VERSION ""

NS_ :

BS_:

BU_: CVC_B BCM_FL BCM_FR DUMMY_ECU DKCU BCM_R

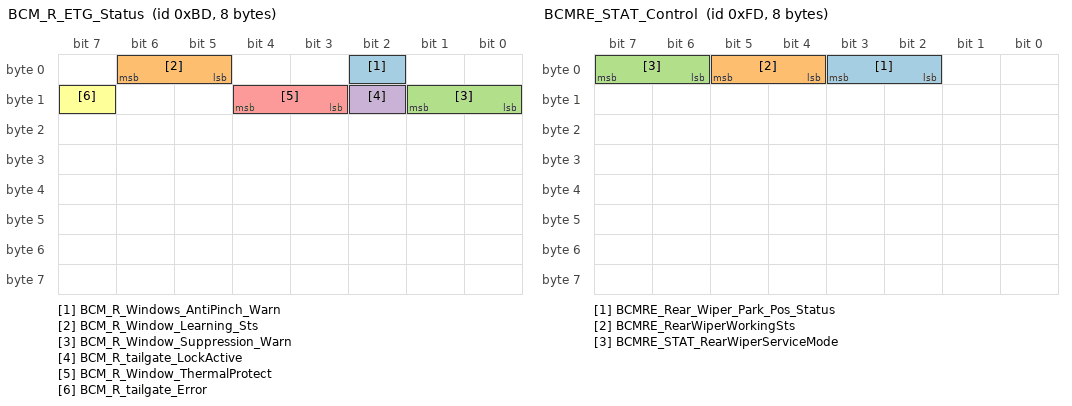
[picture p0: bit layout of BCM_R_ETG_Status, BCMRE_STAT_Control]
BO_ 189 BCM_R_ETG_Status: 8 BCM_R
 SG_ BCM_R_Windows_AntiPinch_Warn : 2|1@0+ (1,0) [0|1] ""  CVC_B
 SG_ BCM_R_Window_Learning_Sts : 6|2@0+ (1,0) [0|2] ""  CVC_B
 SG_ BCM_R_Window_Suppression_Warn : 9|2@0+ (1,0) [0|2] ""  CVC_B
 SG_ BCM_R_tailgate_LockActive : 10|1@0+ (1,0) [0|1] ""  CVC_B
 SG_ BCM_R_Window_ThermalProtect : 12|2@0+ (1,0) [0|2] ""  CVC_B
 SG_ BCM_R_tailgate_Error : 15|1@0+ (1,0) [0|1] ""  CVC_B

BO_ 206 BCMRE_DuctTemperature: 20 BCM_R
 SG_ BCMRE_DuctTempRearRight : 7|11@0+ (0.1,-30) [-30|100] "Degree C"  CVC_B
 SG_ BCMRE_DuctTempRearLeft : 12|11@0+ (0.1,-30) [-30|100] "Degree C"  CVC_B
 SG_ BCMRE_RearEvapTempSensor : 31|8@0+ (1,-40) [-40|85] "Degree C"  CVC_B
 SG_ BCMRE_DuctTempSensor3_Reserved : 39|8@0+ (1,-40) [-40|85] "Degree C"  CVC_B
 SG_ BCMRE_DuctTempSensor4_Reserved : 47|8@0+ (1,-40) [-40|85] "Degree C"  CVC_B
 SG_ BCMRE_DuctTempRearRightSts : 49|2@0+ (1,0) [0|3] ""  CVC_B
 SG_ BCMRE_DuctTempRearLeftSts : 51|2@0+ (1,0) [0|3] ""  CVC_B
 SG_ BCMRE_DuctTempSensor3_Sts : 53|2@0+ (1,0) [0|3] ""  CVC_B
 SG_ BCMRE_DuctTempSensor4_Sts : 55|2@0+ (1,0) [0|3] ""  CVC_B
 SG_ BCMRE_RearEvapTempSensor_Sts : 57|2@0+ (1,0) [0|3] ""  CVC_B

BO_ 253 BCMRE_STAT_Control: 8 BCM_R
 SG_ BCMRE_Rear_Wiper_Park_Pos_Status : 3|2@0+ (1,0) [0|3] ""  CVC_B
 SG_ BCMRE_RearWiperWorkingSts : 5|2@0+ (1,0) [0|2] ""  CVC_B
 SG_ BCMRE_STAT_RearWiperServiceMode : 7|2@0+ (1,0) [0|3] ""  CVC_B

BO_ 275 BCM_RE_Stat_SwtLightBrightness: 8 BCM_R
 SG_ BCM_Stat_SwitchLightBrightness : 7|8@0+ (0.4,0) [0|100] "%"  CVC_B
 SG_ BCM_Rear_Wash_Status : 8|1@0+ (1,0) [0|1] ""  CVC_B

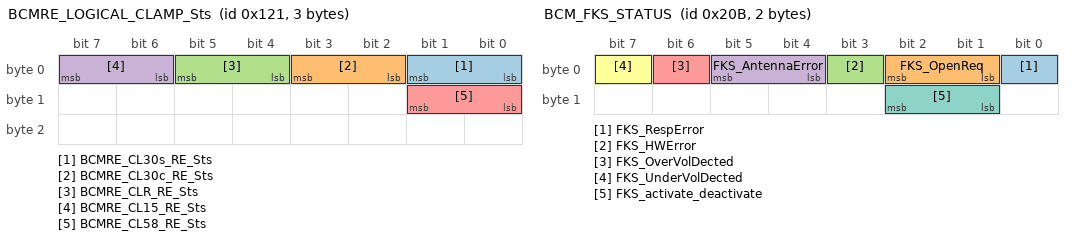
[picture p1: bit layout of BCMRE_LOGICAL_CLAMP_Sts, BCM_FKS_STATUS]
BO_ 289 BCMRE_LOGICAL_CLAMP_Sts: 3 BCM_R
 SG_ BCMRE_CL30s_RE_Sts : 1|2@0+ (1,0) [0|3] ""  CVC_B
 SG_ BCMRE_CL30c_RE_Sts : 3|2@0+ (1,0) [0|3] ""  CVC_B
 SG_ BCMRE_CLR_RE_Sts : 5|2@0+ (1,0) [0|3] ""  CVC_B
 SG_ BCMRE_CL15_RE_Sts : 7|2@0+ (1,0) [0|3] ""  CVC_B
 SG_ BCMRE_CL58_RE_Sts : 9|2@0+ (1,0) [0|3] ""  CVC_B

BO_ 325 BCMRE_ThermalComponents_Status: 32 BCM_R
 SG_ BCMRE_CoolantLevel3 : 1|2@0+ (1,0) [0|3] ""  CVC_B
 SG_ BCMRE_CoolantLevel3Error : 3|1@0+ (1,0) [0|1] ""  CVC_B
 SG_ BCMRE_PT_Sensor1_Pressure : 15|8@0+ (1,0) [0|37.27] "Bar"  CVC_B
 SG_ BCMRE_PT_Sensor1_Temp : 23|8@0+ (1,-40) [-40|150] "Degree C"  CVC_B
 SG_ BCMRE_PT_Sensor2_Pressure : 31|8@0+ (1,0) [0|37.27] "Bar"  CVC_B
 SG_ BCMRE_PT_Sensor2_Temp : 39|8@0+ (1,-40) [-40|150] "Degree C"  CVC_B
 SG_ BCMRE_Refrigerent_Temp_Sensor : 47|8@0+ (1,-40) [-40|130] "Degree C"  CVC_B
 SG_ BCMRE_SOV_Status : 49|2@0+ (1,0) [0|3] ""  CVC_B
 SG_ BCMRE_SOV2_Fault : 7|2@0+ (1,0) [0|3] ""  CVC_B
 SG_ BCMRE_EvapSOV2_Status : 5|2@0+ (1,0) [0|3] ""  CVC_B
 SG_ BCMRE_RearBlwMotor : 63|3@0+ (1,0) [0|7] ""  CVC_B
 SG_ BCMRE_RearBlwDiagFlag1 : 60|4@0+ (1,0) [0|15] ""  CVC_B
 SG_ BCMRE_RearBLFM_ErrorResp : 56|1@0+ (1,0) [0|1] ""  CVC_B
 SG_ BCMRE_RearBlwDiagFlag2 : 71|8@0+ (1,0) [0|255] ""  CVC_B
 SG_ BCMRE_RearBlwIBATT : 79|8@0+ (0.15,0) [0|38] "A"  CVC_B
 SG_ BCMRE_RearBlwRotationSpd : 87|8@0+ (20,0) [0|5100] "RPM"  CVC_B
 SG_ BCMRE_RearBlwTemperature : 95|8@0+ (1,-40) [0|255] "degC"  CVC_B
 SG_ BCMRE_RearBlwUBATT : 103|8@0+ (0.1,0) [0|255] "V"  CVC_B
 SG_ BCMRE_RearBlwSupplier : 111|8@0+ (1,0) [0|255] ""  CVC_B
 SG_ BCMRE_RearBlwUMotor : 119|8@0+ (0.1,0) [0|255] "V"  CVC_B
 SG_ BCMRE_RearBlwTorque : 167|10@0+ (0.001,0) [0|1.023] "Nm"  CVC_B
 SG_ BCMRE_RearAPTC_BusLineVolt : 127|8@0+ (4,0) [0|1020] "V"  CVC_B
 SG_ BCMRE_RearAPTC_BusLineCurrent : 135|8@0+ (0.1,0) [0|25.5] "A"  CVC_B
 SG_ BCMRE_RearAPTC_Temperature : 143|8@0+ (1,-40) [0|215] "Deg C"  CVC_B
 SG_ BCMRE_RearAPTC_HeatPwr : 151|8@0+ (1,0) [0|100] "%"  CVC_B
 SG_ BCMRE_RearAPTC_Status : 55|1@0+ (1,0) [0|1] ""  CVC_B
 SG_ BCMRE_RearAPTC_FaultState : 54|1@0+ (1,0) [0|1] ""  CVC_B
 SG_ BCMRE_RearAPTC_LinComError : 53|1@0+ (1,0) [0|1] ""  CVC_B
 SG_ BCMRE_RearAPTC_OverCurrentFault : 52|1@0+ (1,0) [0|1] ""  CVC_B
 SG_ BCMRE_RearAPTC_LvUnderVoltFault : 51|1@0+ (1,0) [0|1] ""  CVC_B
 SG_ BCMRE_RearAPTC_LvOverVoltFault : 50|1@0+ (1,0) [0|1] ""  CVC_B
 SG_ BCMRE_RearAPTC_IGBTTempSensorFau : 185|1@0+ (1,0) [0|1] ""  CVC_B
 SG_ BCMRE_RearAPTC_IGBTOverTempFault : 184|1@0+ (1,0) [0|1] ""  CVC_B
 SG_ BCMRE_RearAPTC_TempSensorFault : 192|1@0+ (1,0) [0|1] ""  CVC_B
 SG_ BCMRE_RearAPTC_OverTempFault : 193|1@0+ (1,0) [0|1] ""  CVC_B
 SG_ BCMRE_RearAPTC_HvUnderVoltFault : 194|1@0+ (1,0) [0|1] ""  CVC_B
 SG_ BCMRE_RearAPTC_HvOverVoltFault : 195|1@0+ (1,0) [0|1] ""  CVC_B
 SG_ BCMRE_RearAPTC_ShortCircuitFault : 196|1@0+ (1,0) [0|1] ""  CVC_B
 SG_ BCMRE_RearAPTC_OpentCircuitFault : 197|1@0+ (1,0) [0|1] ""  CVC_B
 SG_ BCMRE_RearAPTC_ResponseError : 198|1@0+ (1,0) [0|1] ""  CVC_B
 SG_ BCMRE_RearAPTC_IGBTTemperature : 159|8@0+ (1,-40) [0|215] "Deg C"  CVC_B
 SG_ BCMRE_RearEXV_RsErr : 199|1@0+ (1,0) [0|1] ""  CVC_B
 SG_ BCMRE_RearEXV_CurInit_Stat : 173|2@0+ (1,0) [0|3] ""  CVC_B
 SG_ BCMRE_RearEXV_Run_Stat : 2|1@0+ (1,0) [0|1] ""  CVC_B
 SG_ BCMRE_RearEXV_Fault_Stat : 171|4@0+ (1,0) [0|15] ""  CVC_B
 SG_ BCMRE_RearEXV_Volt_Stat : 189|2@0+ (1,0) [0|3] ""  CVC_B
 SG_ BCMRE_RearEXV_OvrTemp_Warn : 187|2@0+ (1,0) [0|3] ""  CVC_B
 SG_ BCMRE_RearEXV_Pos : 183|10@0+ (1,0) [0|576] ""  CVC_B

BO_ 522 ETG_STATUS: 8 BCM_R
 SG_ ETG_Lift_Gate_Status : 43|4@0+ (1,0) [0|15] ""  CVC_B
 SG_ ETG_Power_Latch_Status : 5|3@0+ (1,0) [0|7] ""  CVC_B
 SG_ ETG_Latch_Segment : 7|2@0+ (1,0) [0|3] ""  CVC_B
 SG_ ETG_Opening_Percentage : 15|8@0+ (1,0) [0|100] "%"  CVC_B
 SG_ ETG_DSW_Status : 16|1@0+ (1,0) [0|1] ""  CVC_B
 SG_ ETG_GSW_Status : 17|1@0+ (1,0) [0|1] ""  CVC_B
 SG_ ETG_LTS_Status : 18|1@0+ (1,0) [0|1] ""  CVC_B
 SG_ ETG_RTS_Status : 19|1@0+ (1,0) [0|1] ""  CVC_B
 SG_ ETG_HAL_Status : 20|1@0+ (1,0) [0|1] ""  CVC_B
 SG_ ETG_FUL_Status : 21|1@0+ (1,0) [0|1] ""  CVC_B
 SG_ ETG_AJR_Status : 22|1@0+ (1,0) [0|1] ""  CVC_B
 SG_ ETG_NTL_Status : 23|1@0+ (1,0) [0|1] ""  CVC_B
 SG_ ETG_ERR_Voltage : 25|2@0+ (1,0) [0|3] ""  CVC_B
 SG_ ETG_ERR_Left_Motor : 27|2@0+ (1,0) [0|3] ""  CVC_B
 SG_ ETG_ERR_Right_Motor : 29|2@0+ (1,0) [0|3] ""  CVC_B
 SG_ ETG_ERR_Latch : 31|2@0+ (1,0) [0|3] ""  CVC_B
 SG_ ETG_ERR_Hall : 33|2@0+ (1,0) [0|3] ""  CVC_B
 SG_ ETG_Lift_Motor_Stall : 34|1@0+ (1,0) [0|1] ""  CVC_B
 SG_ ETG_Lift_Motor_AntiPinch : 35|1@0+ (1,0) [0|1] ""  CVC_B
 SG_ ETG_Lift_Motor_Thermal : 36|1@0+ (1,0) [0|1] ""  CVC_B
 SG_ ETG_Power_Latch_Thermal : 37|1@0+ (1,0) [0|1] ""  CVC_B
 SG_ ETG_Abuse_Protection : 38|1@0+ (1,0) [0|1] ""  CVC_B

BO_ 523 BCM_FKS_STATUS: 2 BCM_R
 SG_ FKS_RespError : 0|1@0+ (1,0) [0|1] ""  CVC_B
 SG_ FKS_OpenReq : 2|2@0+ (1,0) [0|3] ""  CVC_B
 SG_ FKS_HWError : 3|1@0+ (1,0) [0|1] ""  CVC_B
 SG_ FKS_AntennaError : 5|2@0+ (1,0) [0|3] ""  CVC_B
 SG_ FKS_OverVolDected : 6|1@0+ (1,0) [0|1] ""  CVC_B
 SG_ FKS_UnderVolDected : 7|1@0+ (1,0) [0|1] ""  CVC_B
 SG_ FKS_activate_deactivate : 10|2@0+ (1,0) [0|3] ""  CVC_B

BO_ 535 BCMRE_ExteriorLight_STS: 12 BCM_R
 SG_ BCM_PositionLight_RL_STS : 2|3@0+ (1,0) [0|4] ""  CVC_B
 SG_ BCM_PositionLight_RR_STS : 5|3@0+ (1,0) [0|4] ""  CVC_B
 SG_ BCM_TurnIndicator_RL_STS : 10|3@0+ (1,0) [0|4] ""  CVC_B
 SG_ BCM_TurnIndicator_RR_STS : 13|3@0+ (1,0) [0|4] ""  CVC_B
 SG_ BCM_ReverseLamp_RL_STS : 18|3@0+ (1,0) [0|4] ""  CVC_B
 SG_ BCM_ReverseLamp_RR_STS : 21|3@0+ (1,0) [0|4] ""  CVC_B
 SG_ BCM_BrakeLight_RL_STS : 26|3@0+ (1,0) [0|4] ""  CVC_B
 SG_ BCM_BrakeLight_RR_STS : 29|3@0+ (1,0) [0|4] ""  CVC_B
 SG_ BCM_RearFogLamp_RR_STS : 34|3@0+ (1,0) [0|4] ""  CVC_B
 SG_ BCM_BrakeLight_Center_STS : 37|3@0+ (1,0) [0|4] ""  CVC_B
 SG_ BCM_LicensePlateLamp_RE_STS : 42|3@0+ (1,0) [0|4] ""  CVC_B
 SG_ BCM_RearFogLamp_RL_STS : 45|3@0+ (1,0) [0|4] ""  CVC_B
 SG_ BCM_SignatureRear_STS : 55|3@0+ (1,0) [0|4] ""  CVC_B
 SG_ BCMRE_WelcomeFarewellLight_STS : 71|3@0+ (1,0) [0|7] ""  CVC_B
 SG_ BCM_PositionLight_RM_STS : 68|3@0+ (1,0) [0|4] ""  CVC_B
 SG_ BCM_ParkingLight_RL_STS : 65|2@0+ (1,0) [0|3] ""  CVC_B
 SG_ BCM_ParkingLight_RM_STS : 79|2@0+ (1,0) [0|3] ""  CVC_B
 SG_ BCM_ParkingLight_RR_STS : 77|2@0+ (1,0) [0|3] ""  CVC_B

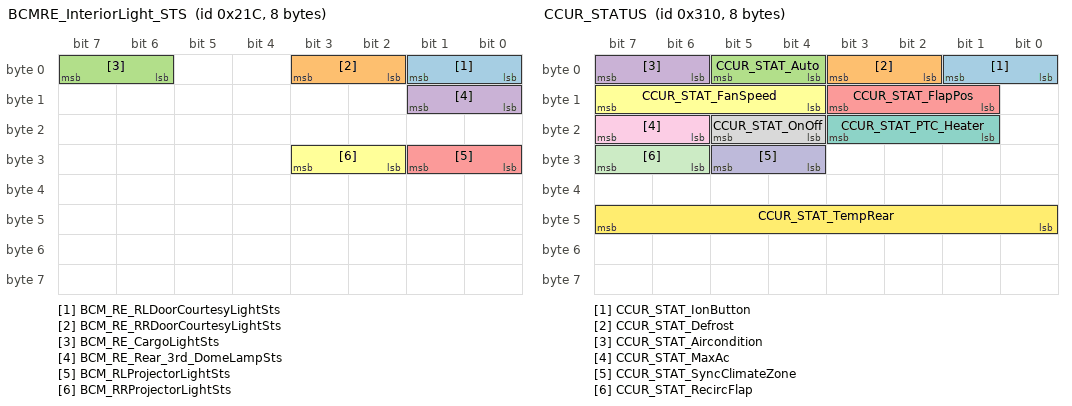
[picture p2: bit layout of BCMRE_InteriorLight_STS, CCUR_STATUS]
BO_ 540 BCMRE_InteriorLight_STS: 8 BCM_R
 SG_ BCM_RE_RLDoorCourtesyLightSts : 1|2@0+ (1,0) [0|3] ""  CVC_B
 SG_ BCM_RE_RRDoorCourtesyLightSts : 3|2@0+ (1,0) [0|3] ""  CVC_B
 SG_ BCM_RE_CargoLightSts : 7|2@0+ (1,0) [0|3] ""  CVC_B
 SG_ BCM_RE_Rear_3rd_DomeLampSts : 9|2@0+ (1,0) [0|3] ""  CVC_B
 SG_ BCM_RLProjectorLightSts : 25|2@0+ (1,0) [0|3] ""  CVC_B
 SG_ BCM_RRProjectorLightSts : 27|2@0+ (1,0) [0|3] ""  CVC_B

BO_ 784 CCUR_STATUS: 8 BCM_R
 SG_ CCUR_STAT_IonButton : 1|2@0+ (1,0) [0|3] ""  CVC_B
 SG_ CCUR_STAT_Defrost : 3|2@0+ (1,0) [0|3] ""  CVC_B
 SG_ CCUR_STAT_Auto : 5|2@0+ (1,0) [0|3] ""  CVC_B
 SG_ CCUR_STAT_Aircondition : 7|2@0+ (1,0) [0|3] ""  CVC_B
 SG_ CCUR_STAT_FlapPos : 11|3@0+ (1,0) [0|7] ""  CVC_B
 SG_ CCUR_STAT_FanSpeed : 15|4@0+ (1,0) [0|15] ""  CVC_B
 SG_ CCUR_STAT_PTC_Heater : 19|3@0+ (1,0) [0|7] ""  CVC_B
 SG_ CCUR_STAT_OnOff : 21|2@0+ (1,0) [0|3] ""  CVC_B
 SG_ CCUR_STAT_MaxAc : 23|2@0+ (1,0) [0|3] ""  CVC_B
 SG_ CCUR_STAT_SyncClimateZone : 29|2@0+ (1,0) [0|3] ""  CVC_B
 SG_ CCUR_STAT_RecircFlap : 31|2@0+ (1,0) [0|3] ""  CVC_B
 SG_ CCUR_STAT_TempRear : 47|8@0+ (0.5,0) [16|32] "Degree C"  CVC_B

BO_ 1040 BCM_RE_RearWindow_sts: 8 BCM_R
 SG_ BCMRE_RearHeatedWindow : 1|2@0+ (1,0) [0|3] ""  CVC_B

BO_ 1056 BCM_Comfort_Confirm_RE_sts: 8 BCM_R
 SG_ BCM_STAT_AutoRearWiper : 1|2@0+ (1,0) [0|3] ""  CVC_B
 SG_ BCM_STAT_MirrorFoldSetting : 3|2@0+ (1,0) [0|3] ""  CVC_B
 SG_ BCM_STAT_IMMO_KeyfobID2 : 7|3@0+ (1,0) [0|7] ""  CVC_B
 SG_ BCM_STAT_MirrorAutoUnfold : 9|2@0+ (1,0) [0|3] ""  CVC_B
 SG_ BCM_STAT_MirrorReverseLink : 11|2@0+ (1,0) [0|3] ""  CVC_B
 SG_ BCM_STAT_MirrorDefaultSTATting : 13|2@0+ (1,0) [0|3] ""  CVC_B
 SG_ BCM_STAT_WelcomeTriggerCondition : 15|2@0+ (1,0) [0|3] ""  CVC_B
 SG_ BCM_STAT_FrontDomeLamp : 17|2@0+ (1,0) [0|3] ""  CVC_B
 SG_ BCM_STAT_FollowMeHome : 20|3@0+ (1,0) [0|7] ""  CVC_B
 SG_ BCM_STAT_ExteriorLight : 23|3@0+ (1,0) [0|7] ""  CVC_B
 SG_ BCM_STAT_RemoteLockFeedback : 26|3@0+ (1,0) [0|7] ""  CVC_B
 SG_ BCM_STAT_RemoteDoorUnlock : 28|2@0+ (1,0) [0|3] ""  CVC_B
 SG_ BCM_STAT_AutoDoorUnlock : 30|2@0+ (1,0) [0|3] ""  CVC_B
 SG_ BCM_STAT_AmbientLightBrighness : 39|7@0+ (1,0) [0|100] "%"  CVC_B
 SG_ BCM_STAT_WiperServiceMode : 42|2@0+ (1,0) [0|3] ""  CVC_B
 SG_ BCM_STAT_IMMO_KeyfobID : 45|2@0+ (1,0) [0|3] ""  CVC_B
 SG_ BCM_STAT_RearHeatedWindowMirror : 47|2@0+ (1,0) [0|3] ""  CVC_B
 SG_ BCM_STAT_AntiTheftMode : 50|3@0+ (1,0) [0|7] ""  CVC_B
 SG_ BCM_STAT_ClimateKeepOnSts : 53|2@0+ (1,0) [0|3] ""  CVC_B
 SG_ BCM_STAT_FKSfeedback : 55|2@0+ (1,0) [0|3] ""  CVC_B
 SG_ SECCAN_CmftCnfrm : 63|8@0+ (1,0) [0|255] ""  CVC_B

BO_ 1075 BCMRE_Mirror_Sts: 8 BCM_R
 SG_ BCMRE_STAT_RearDefrost : 7|2@0+ (1,0) [0|3] ""  CVC_B

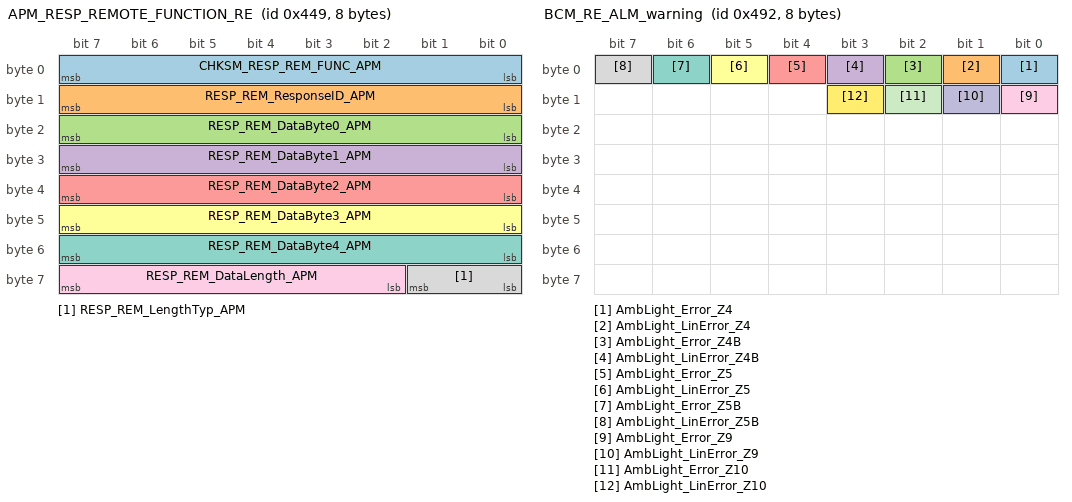
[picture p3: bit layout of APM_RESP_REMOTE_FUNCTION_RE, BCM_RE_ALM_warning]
BO_ 1097 APM_RESP_REMOTE_FUNCTION_RE: 8 BCM_R
 SG_ CHKSM_RESP_REM_FUNC_APM : 7|8@0+ (1,0) [0|255] ""  CVC_B
 SG_ RESP_REM_ResponseID_APM : 15|8@0+ (1,0) [0|254] ""  CVC_B
 SG_ RESP_REM_DataByte0_APM : 23|8@0+ (1,0) [0|254] ""  CVC_B
 SG_ RESP_REM_DataByte1_APM : 31|8@0+ (1,0) [0|254] ""  CVC_B
 SG_ RESP_REM_DataByte2_APM : 39|8@0+ (1,0) [0|254] ""  CVC_B
 SG_ RESP_REM_DataByte3_APM : 47|8@0+ (1,0) [0|254] ""  CVC_B
 SG_ RESP_REM_DataByte4_APM : 55|8@0+ (1,0) [0|254] ""  CVC_B
 SG_ RESP_REM_LengthTyp_APM : 57|2@0+ (1,0) [0|3] ""  CVC_B
 SG_ RESP_REM_DataLength_APM : 63|6@0+ (1,0) [0|63] ""  CVC_B

BO_ 1170 BCM_RE_ALM_warning: 8 BCM_R
 SG_ AmbLight_Error_Z4 : 0|1@0+ (1,0) [0|1] ""  CVC_B
 SG_ AmbLight_LinError_Z4 : 1|1@0+ (1,0) [0|1] ""  CVC_B
 SG_ AmbLight_Error_Z4B : 2|1@0+ (1,0) [0|1] ""  CVC_B
 SG_ AmbLight_LinError_Z4B : 3|1@0+ (1,0) [0|1] ""  CVC_B
 SG_ AmbLight_Error_Z5 : 4|1@0+ (1,0) [0|1] ""  CVC_B
 SG_ AmbLight_LinError_Z5 : 5|1@0+ (1,0) [0|1] ""  CVC_B
 SG_ AmbLight_Error_Z5B : 6|1@0+ (1,0) [0|1] ""  CVC_B
 SG_ AmbLight_LinError_Z5B : 7|1@0+ (1,0) [0|1] ""  CVC_B
 SG_ AmbLight_Error_Z9 : 8|1@0+ (1,0) [0|1] ""  CVC_B
 SG_ AmbLight_LinError_Z9 : 9|1@0+ (1,0) [0|1] ""  CVC_B
 SG_ AmbLight_Error_Z10 : 10|1@0+ (1,0) [0|1] ""  CVC_B
 SG_ AmbLight_LinError_Z10 : 11|1@0+ (1,0) [0|1] ""  CVC_B

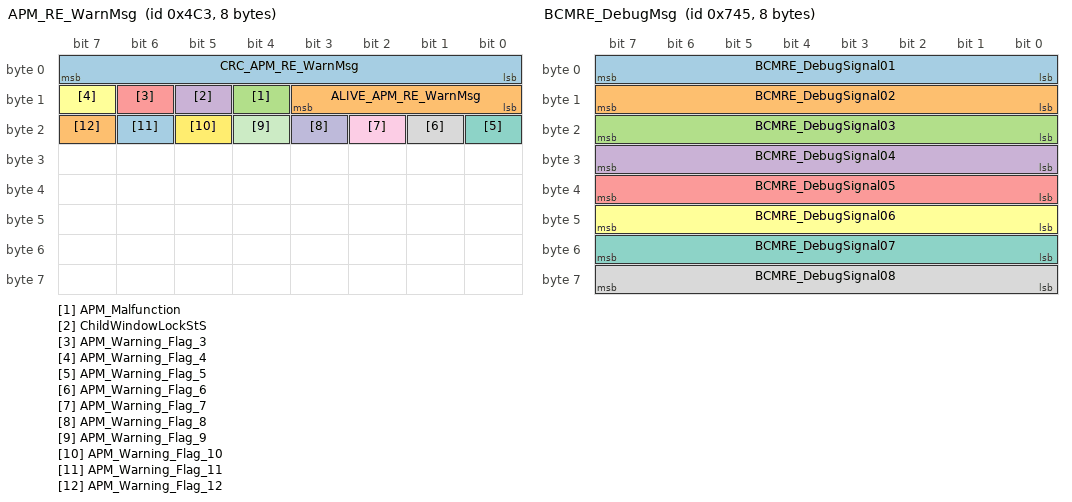
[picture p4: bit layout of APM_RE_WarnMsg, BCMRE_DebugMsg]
BO_ 1219 APM_RE_WarnMsg: 8 BCM_R
 SG_ CRC_APM_RE_WarnMsg : 7|8@0+ (1,0) [0|255] ""  CVC_B
 SG_ ALIVE_APM_RE_WarnMsg : 11|4@0+ (1,0) [0|15] ""  CVC_B
 SG_ APM_Malfunction : 12|1@0+ (1,0) [0|1] ""  CVC_B
 SG_ ChildWindowLockStS : 13|1@0+ (1,0) [0|1] ""  CVC_B
 SG_ APM_Warning_Flag_3 : 14|1@0+ (1,0) [0|1] ""  CVC_B
 SG_ APM_Warning_Flag_4 : 15|1@0+ (1,0) [0|1] ""  CVC_B
 SG_ APM_Warning_Flag_5 : 16|1@0+ (1,0) [0|1] ""  CVC_B
 SG_ APM_Warning_Flag_6 : 17|1@0+ (1,0) [0|1] ""  CVC_B
 SG_ APM_Warning_Flag_7 : 18|1@0+ (1,0) [0|1] ""  CVC_B
 SG_ APM_Warning_Flag_8 : 19|1@0+ (1,0) [0|1] ""  CVC_B
 SG_ APM_Warning_Flag_9 : 20|1@0+ (1,0) [0|1] ""  CVC_B
 SG_ APM_Warning_Flag_10 : 21|1@0+ (1,0) [0|1] ""  CVC_B
 SG_ APM_Warning_Flag_11 : 22|1@0+ (1,0) [0|1] ""  CVC_B
 SG_ APM_Warning_Flag_12 : 23|1@0+ (1,0) [0|1] ""  CVC_B

BO_ 1242 BCM_R_WarnMsg_R: 8 BCM_R
 SG_ CRC_BCM_R_WarnMsg_R : 7|8@0+ (1,0) [0|255] ""  CVC_B
 SG_ ALIVE_BCM_R_WarnMsg_R : 11|4@0+ (1,0) [0|15] ""  CVC_B
 SG_ BCM_R_NoValidKey_1 : 12|1@0+ (1,0) [0|1] ""  CVC_B
 SG_ BCM_R_SSB_defect : 13|1@0+ (1,0) [0|1] ""  CVC_B
 SG_ BCM_R_WrongGearPosToStart : 14|1@0+ (1,0) [0|1] ""  CVC_B
 SG_ BCM_R_NoValidKey_2 : 15|1@0+ (1,0) [0|1] ""  CVC_B
 SG_ BCM_R_PressBrakeToStart : 16|1@0+ (1,0) [0|1] ""  CVC_B
 SG_ BCM_R_TurnOffPosLightRemindr : 17|1@0+ (1,0) [0|1] ""  CVC_B
 SG_ BCM_R_KeyFob_LowBattery : 18|1@0+ (1,0) [0|1] ""  CVC_B
 SG_ BCM_R_StopLightDefect : 19|1@0+ (1,0) [0|1] ""  CVC_B
 SG_ BCM_R_LowBeamDefect : 20|1@0+ (1,0) [0|1] ""  CVC_B
 SG_ BCM_R_HighBeamDefect : 21|1@0+ (1,0) [0|1] ""  CVC_B
 SG_ BCM_R_PositionLightDefect : 22|1@0+ (1,0) [0|1] ""  CVC_B
 SG_ BCM_R_CHMLS_Defect : 23|1@0+ (1,0) [0|1] ""  CVC_B
 SG_ BCM_R_LicencePlateLight_Defect : 24|1@0+ (1,0) [0|1] ""  CVC_B
 SG_ BCM_R_FrontFog_Defect : 25|1@0+ (1,0) [0|1] ""  CVC_B
 SG_ BCM_R_RearLeftDoorLockDefect : 26|1@0+ (1,0) [0|1] ""  CVC_B
 SG_ BCM_R_ReverseLightDefect : 27|1@0+ (1,0) [0|1] ""  CVC_B
 SG_ BCM_R_RLS_Malfunction : 28|1@0+ (1,0) [0|1] ""  CVC_B
 SG_ BCM_R_12VBattery_LowLevel : 29|1@0+ (1,0) [0|1] ""  CVC_B
 SG_ BCM_R_ForgetKeyFOBInCar : 30|1@0+ (1,0) [0|1] ""  CVC_B
 SG_ BCM_R_12VBattery_Discharging : 31|1@0+ (1,0) [0|1] ""  CVC_B
 SG_ BCM_R_TurnIndicatorDefect : 32|1@0+ (1,0) [0|1] ""  CVC_B
 SG_ BCM_R_dTPMS_Malfunc : 33|1@0+ (1,0) [0|1] ""  CVC_B
 SG_ BCM_R_dTPMS_Malfunc_LostSensor : 34|1@0+ (1,0) [0|1] ""  CVC_B
 SG_ BCM_R_dTPMS_LowPressure : 35|1@0+ (1,0) [0|1] ""  CVC_B
 SG_ BCM_R_dTPMS_RapidLeak : 36|1@0+ (1,0) [0|1] ""  CVC_B
 SG_ BCM_R_dTPMS_HighTemperature : 37|1@0+ (1,0) [0|1] ""  CVC_B
 SG_ BCM_R_dTPMS_HighPressure : 38|1@0+ (1,0) [0|1] ""  CVC_B
 SG_ BCM_R_dTPMS_LowBattery : 39|1@0+ (1,0) [0|1] ""  CVC_B
 SG_ BCM_R_Keyfob_Leftcar : 40|1@0+ (1,0) [0|1] ""  CVC_B
 SG_ BCM_R_IDB_Brakelight_Malfunctio : 41|1@0+ (1,0) [0|1] ""  CVC_B
 SG_ BCM_R_CVC_Brakelight_Malfunction : 42|1@0+ (1,0) [0|1] ""  CVC_B
 SG_ BCM_R_ADAS_Turnlight_Malfunction : 43|1@0+ (1,0) [0|1] ""  CVC_B
 SG_ BCM_R_ADAS_Highbeam_Malfunction : 44|1@0+ (1,0) [0|1] ""  CVC_B
 SG_ BCM_R_ADAS_LowBeam_Malfunction : 45|1@0+ (1,0) [0|1] ""  CVC_B
 SG_ BCM_R_CVC_B_Malfunction : 46|1@0+ (1,0) [0|1] ""  CVC_B
 SG_ BCM_R_BCM_Malfunction : 47|1@0+ (1,0) [0|1] ""  CVC_B
 SG_ BCM_R_SCM_Malfunction : 48|1@0+ (1,0) [0|1] ""  CVC_B
 SG_ BCM_R_CrashSignalDefect : 49|1@0+ (1,0) [0|1] ""  CVC_B
 SG_ BCM_R_RearFog_Defect : 50|1@0+ (1,0) [0|1] ""  CVC_B
 SG_ BCM_R_FrontWiperDefect : 51|1@0+ (1,0) [0|1] ""  CVC_B
 SG_ BCM_R_FrontLeftDoorLockDefect : 55|1@0+ (1,0) [0|1] ""  CVC_B
 SG_ BCM_R_LDML_Malfunction : 56|1@0+ (1,0) [0|1] ""  CVC_B
 SG_ BCM_R_RLT_Malfunction : 60|1@0+ (1,0) [0|1] ""  CVC_B
 SG_ BCM_R_BCM_POWER_Malfunction : 61|1@0+ (1,0) [0|1] ""  CVC_B
 SG_ BCM_R_IDB_AutoHazardBlinking_Mal : 62|1@0+ (1,0) [0|1] ""  CVC_B
 SG_ BCM_R_LossCommGearStatus : 63|1@0+ (1,0) [0|1] ""  CVC_B

BO_ 1246 BCMRE_HornLight_Status: 8 BCM_R
 SG_ BCMRE_STAT_TurnIndicator : 7|4@0+ (1,0) [0|10] ""  CVC_B

BO_ 1861 BCMRE_DebugMsg: 8 BCM_FL
 SG_ BCMRE_DebugSignal01 : 7|8@0+ (1,0) [0|255] ""  CVC_B
 SG_ BCMRE_DebugSignal02 : 15|8@0+ (1,0) [0|255] ""  CVC_B
 SG_ BCMRE_DebugSignal03 : 23|8@0+ (1,0) [0|255] ""  CVC_B
 SG_ BCMRE_DebugSignal04 : 31|8@0+ (1,0) [0|255] ""  CVC_B
 SG_ BCMRE_DebugSignal05 : 39|8@0+ (1,0) [0|255] ""  CVC_B
 SG_ BCMRE_DebugSignal06 : 47|8@0+ (1,0) [0|255] ""  CVC_B
 SG_ BCMRE_DebugSignal07 : 55|8@0+ (1,0) [0|255] ""  CVC_B
 SG_ BCMRE_DebugSignal08 : 63|8@0+ (1,0) [0|255] ""  CVC_B

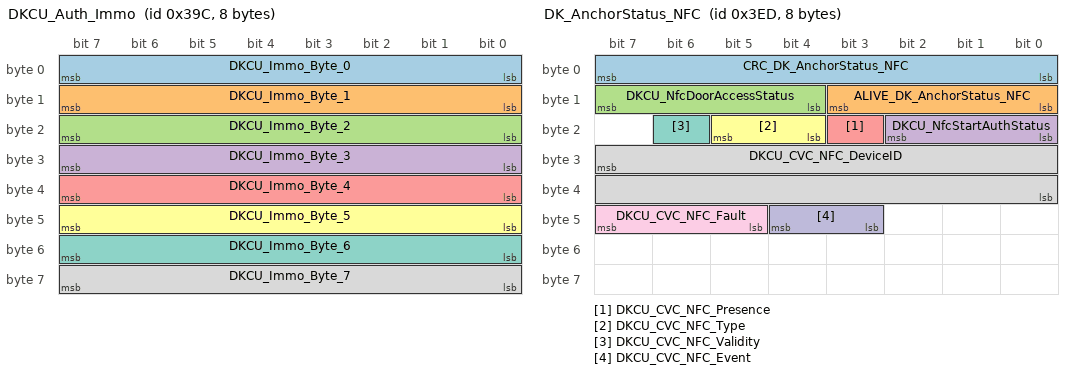
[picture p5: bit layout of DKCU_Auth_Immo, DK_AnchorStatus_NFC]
BO_ 924 DKCU_Auth_Immo: 8 DKCU
 SG_ DKCU_Immo_Byte_0 : 7|8@0+ (1,0) [0|255] ""  CVC_B
 SG_ DKCU_Immo_Byte_1 : 15|8@0+ (1,0) [0|255] ""  CVC_B
 SG_ DKCU_Immo_Byte_2 : 23|8@0+ (1,0) [0|255] ""  CVC_B
 SG_ DKCU_Immo_Byte_3 : 31|8@0+ (1,0) [0|255] ""  CVC_B
 SG_ DKCU_Immo_Byte_4 : 39|8@0+ (1,0) [0|255] ""  CVC_B
 SG_ DKCU_Immo_Byte_5 : 47|8@0+ (1,0) [0|255] ""  CVC_B
 SG_ DKCU_Immo_Byte_6 : 55|8@0+ (1,0) [0|255] ""  CVC_B
 SG_ DKCU_Immo_Byte_7 : 63|8@0+ (1,0) [0|255] ""  CVC_B

BO_ 1001 DK_KeyStatus: 32 DKCU
 SG_ CRC_DK_KeyStatus : 7|8@0+ (1,0) [0|255] ""  CVC_B
 SG_ ALIVE_DK_KeyStatus : 11|4@0+ (1,0) [0|15] ""  CVC_B
 SG_ DKCU_PrimaryDKValidationSts : 15|4@0+ (1,0) [0|15] ""  CVC_B
 SG_ DKCU_Guest1DKValidationSts : 19|4@0+ (1,0) [0|15] ""  CVC_B
 SG_ DKCU_Guest2DKValidationSts : 23|4@0+ (1,0) [0|15] ""  CVC_B
 SG_ DKCU_Guest3DKValidationSts : 27|4@0+ (1,0) [0|15] ""  CVC_B
 SG_ DKCU_Device_ID_Primary : 39|16@0+ (1,0) [0|65535] ""  CVC_B
 SG_ DKCU_Device_ID_Guest1 : 55|16@0+ (1,0) [0|65535] ""  CVC_B
 SG_ DKCU_Device_ID_Guest2 : 71|16@0+ (1,0) [0|65535] ""  CVC_B
 SG_ DKCU_Device_ID_Guest3 : 87|16@0+ (1,0) [0|65535] ""  CVC_B

BO_ 1002 DK_KeyLocation: 64 DKCU
 SG_ CRC_DK_KeyLocation : 7|8@0+ (1,0) [0|255] ""  CVC_B
 SG_ ALIVE_DK_KeyLocation : 11|4@0+ (1,0) [0|15] ""  CVC_B
 SG_ DKCU_PhoneKey_Count : 23|8@0+ (1,0) [0|4] ""  CVC_B
 SG_ DKCU_PhoneKey_PrimaryUser_ID : 31|1@0+ (1,0) [0|1] ""  CVC_B
 SG_ DKCU_PhoneKey_PrimaryUser_Locati : 30|4@0+ (1,0) [0|15] ""  CVC_B
 SG_ DKCU_PhoneKey_PrimaryUser_Motion : 26|1@0+ (1,0) [0|1] ""  CVC_B
 SG_ DKCU_PhoneKey_PrimaryUser_Age_10 : 39|16@0+ (1,0) [0|65535] ""  CVC_B
 SG_ DKCU_PhoneKey_PrimaryUser_RSSI : 55|8@0+ (1,-90) [-90|255] "dBm"  CVC_B
 SG_ DKCU_PhoneKey_PrimaryUser_ConfLv : 63|8@0+ (1,0) [0|255] "dBm"  CVC_B
 SG_ DKCU_UWB_Ranging_PrimaryUser_Dis : 71|4@0+ (0.1,0) [0|15] ""  CVC_B
 SG_ DKCU_BLE_Ranging_PrimaryUser_Dis : 67|8@0+ (1,0) [0|15] ""  CVC_B
 SG_ DKCU_CVC_PrimaryUser_DevicePolic : 75|4@0+ (1,0) [0|15] ""  CVC_B
 SG_ DKCU_PhoneKey_Guest1_ID : 87|1@0+ (1,0) [0|1] ""  CVC_B
 SG_ DKCU_PhoneKey_Guest1_Location : 86|4@0+ (1,0) [0|15] ""  CVC_B
 SG_ DKCU_PhoneKey_Guest1_MotionFlag : 82|1@0+ (1,0) [0|1] ""  CVC_B
 SG_ DKCU_PhoneKey_Guest1_Age_10ms : 95|16@0+ (1,0) [0|65535] ""  CVC_B
 SG_ DKCU_PhoneKey_Guest1_RSSI : 111|8@0+ (1,-90) [-90|255] ""  CVC_B
 SG_ DKCU_PhoneKey_Guest1_ConfLvl : 119|8@0+ (1,0) [0|255] ""  CVC_B
 SG_ DKCU_UWB_Ranging_Guest1_Distance : 127|4@0+ (0.1,0) [0|15] ""  CVC_B
 SG_ DKCU_BLE_Ranging_Guest1_Distance : 123|8@0+ (1,0) [0|255] ""  CVC_B
 SG_ DKCU_CVC_Guest1_DevicePolicy : 131|4@0+ (1,0) [0|15] ""  CVC_B
 SG_ DKCU_PhoneKey_Guest2_ID : 143|1@0+ (1,0) [0|1] ""  CVC_B
 SG_ DKCU_PhoneKey_Guest2_Location : 142|4@0+ (1,0) [0|15] ""  CVC_B
 SG_ DKCU_PhoneKey_Guest2_MotionFlag : 138|1@0+ (1,0) [0|1] ""  CVC_B
 SG_ DKCU_PhoneKey_Guest2_Age_10ms : 151|16@0+ (1,0) [0|65535] ""  CVC_B
 SG_ DKCU_PhoneKey_Guest2_RSSI : 167|8@0+ (1,-90) [-90|255] "dBm"  CVC_B
 SG_ DKCU_PhoneKey_Guest2_ConfLvl : 175|8@0+ (1,0) [0|255] ""  CVC_B
 SG_ DKCU_UWB_Ranging_Guest2_Distance : 183|4@0+ (0.1,0) [0|15] ""  CVC_B
 SG_ DKCU_BLE_Ranging_Guest2_Distance : 179|8@0+ (1,0) [0|255] ""  CVC_B
 SG_ DKCU_CVC_Guest2_DevicePolicy : 187|4@0+ (1,0) [0|15] ""  CVC_B
 SG_ DKCU_PhoneKey_Guest3_ID : 199|1@0+ (1,0) [0|1] ""  CVC_B
 SG_ DKCU_PhoneKey_Guest3_Location : 198|4@0+ (1,0) [0|15] ""  CVC_B
 SG_ DKCU_PhoneKey_Guest3_MotionFlag : 194|1@0+ (1,0) [0|1] ""  CVC_B
 SG_ DKCU_PhoneKey_Guest3_Age_10ms : 207|16@0+ (1,0) [0|65535] ""  CVC_B
 SG_ DKCU_PhoneKey_Guest3_RSSI : 223|8@0+ (1,-90) [-90|255] "dBm"  CVC_B
 SG_ DKCU_PhoneKey_Guest3_ConfLvl : 231|8@0+ (1,0) [0|255] ""  CVC_B
 SG_ DKCU_UWB_Ranging_Guest3_Distance : 239|4@0+ (0.1,0) [0|15] ""  CVC_B
 SG_ DKCU_BLE_Ranging_Guest3_Distance : 235|8@0+ (1,0) [0|255] ""  CVC_B
 SG_ DKCU_CVC_Guest3_DevicePolicy : 243|4@0+ (1,0) [0|15] ""  CVC_B

BO_ 1003 DK_DKCU_Command: 24 DKCU
 SG_ CRC_DK_DKCU_Command : 7|8@0+ (1,0) [0|255] ""  CVC_B
 SG_ ALIVE_DK_DKCU_Command : 11|4@0+ (1,0) [0|15] ""  CVC_B
 SG_ DKCU_CVC_Lock_Req : 12|1@0+ (1,0) [0|1] ""  CVC_B
 SG_ DKCU_CVC_Unlock_Req : 13|1@0+ (1,0) [0|1] ""  CVC_B
 SG_ DKCU_Foot_Kick_Req : 14|1@0+ (1,0) [0|1] ""  CVC_B
 SG_ DKCU_CVC_ApproachingUnlock_Req : 15|1@0+ (1,0) [0|1] ""  CVC_B
 SG_ DKCU_CVC_WalkawayLock_Req : 16|1@0+ (1,0) [0|1] ""  CVC_B
 SG_ DKCU_CVC_LocateCarReq : 17|1@0+ (1,0) [0|1] ""  CVC_B
 SG_ DKCU_CVC_FindCarReq : 18|1@0+ (1,0) [0|1] ""  CVC_B
 SG_ DKCU_CVC_Welcome_Req : 19|1@0+ (1,0) [0|1] ""  CVC_B
 SG_ Secure_ResetCnt_0x3EB : 135|16@0+ (1,0) [0|65535] ""  CVC_B
 SG_ Secure_MsgCnt_0x3EB : 151|16@0+ (1,0) [0|65535] ""  CVC_B
 SG_ Secure_MAC_0x3EB : 167|32@0+ (1,0) [0|4294967295] ""  CVC_B

BO_ 1005 DK_AnchorStatus_NFC: 8 DKCU
 SG_ CRC_DK_AnchorStatus_NFC : 7|8@0+ (1,0) [0|255] ""  CVC_B
 SG_ ALIVE_DK_AnchorStatus_NFC : 11|4@0+ (1,0) [0|15] ""  CVC_B
 SG_ DKCU_NfcDoorAccessStatus : 15|4@0+ (1,0) [0|15] ""  CVC_B
 SG_ DKCU_NfcStartAuthStatus : 18|3@0+ (1,0) [0|7] ""  CVC_B
 SG_ DKCU_CVC_NFC_Presence : 19|1@0+ (1,0) [0|1] ""  CVC_B
 SG_ DKCU_CVC_NFC_Type : 21|2@0+ (1,0) [0|3] ""  CVC_B
 SG_ DKCU_CVC_NFC_Validity : 22|1@0+ (1,0) [0|1] ""  CVC_B
 SG_ DKCU_CVC_NFC_DeviceID : 31|16@0+ (1,0) [0|65535] ""  CVC_B
 SG_ DKCU_CVC_NFC_Fault : 47|3@0+ (1,0) [0|2] ""  CVC_B
 SG_ DKCU_CVC_NFC_Event : 44|2@0+ (1,0) [0|3] ""  CVC_B

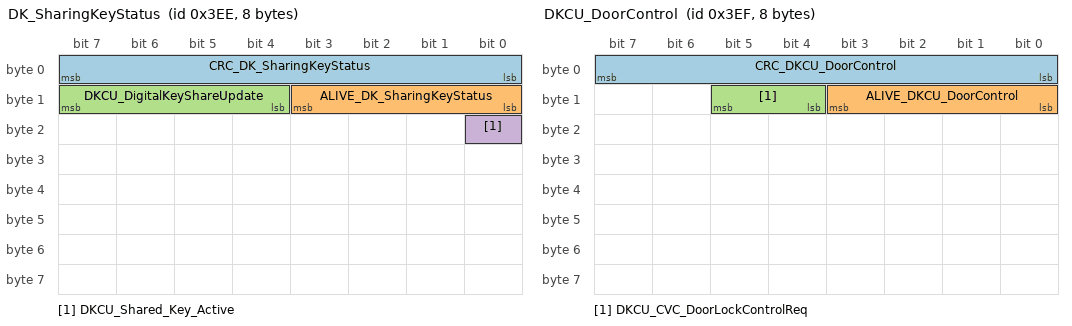
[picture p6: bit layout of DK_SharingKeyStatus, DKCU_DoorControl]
BO_ 1006 DK_SharingKeyStatus: 8 DKCU
 SG_ CRC_DK_SharingKeyStatus : 7|8@0+ (1,0) [0|255] ""  CVC_B
 SG_ ALIVE_DK_SharingKeyStatus : 11|4@0+ (1,0) [0|15] ""  CVC_B
 SG_ DKCU_DigitalKeyShareUpdate : 15|4@0+ (1,0) [0|15] ""  CVC_B
 SG_ DKCU_Shared_Key_Active : 16|1@0+ (1,0) [0|1] ""  CVC_B

BO_ 1007 DKCU_DoorControl: 8 DKCU
 SG_ CRC_DKCU_DoorControl : 7|8@0+ (1,0) [0|255] ""  CVC_B
 SG_ ALIVE_DKCU_DoorControl : 11|4@0+ (1,0) [0|15] ""  CVC_B
 SG_ DKCU_CVC_DoorLockControlReq : 13|2@0+ (1,0) [0|3] ""  CVC_B

BO_ 1008 DKCU_TailgateBonnetControl: 24 DKCU
 SG_ CRC_DKCU_TailgateBonnetControl : 7|8@0+ (1,0) [0|255] ""  CVC_B
 SG_ ALIVE_DKCU_TailgateBonnetControl : 11|4@0+ (1,0) [0|15] ""  CVC_B
 SG_ DKCU_CVC_TailgateLockControlReq : 13|2@0+ (1,0) [0|3] ""  CVC_B
 SG_ DKCU_CVC_TailgateOpenReq : 15|2@0+ (1,0) [0|3] ""  CVC_B
 SG_ DKCU_CVC_BonnetLockControlReq : 17|2@0+ (1,0) [0|3] ""  CVC_B
 SG_ DKCU_CVC_BonnetOpenReq : 19|2@0+ (1,0) [0|3] ""  CVC_B
 SG_ Secure_ResetCnt_0x3F0 : 135|16@0+ (1,0) [0|65535] ""  CVC_B
 SG_ Secure_MsgCnt_0x3F0 : 151|16@0+ (1,0) [0|65535] ""  CVC_B
 SG_ Secure_MAC_0x3F0 : 167|32@0+ (1,0) [0|4294967295] ""  CVC_B

BO_ 1010 DK_AnchorSignal_Status: 16 DKCU
 SG_ CRC_DK_AnchorSignal_Status : 7|8@0+ (1,0) [0|255] ""  CVC_B
 SG_ ALIVE_DK_AnchorSignal_Status : 11|4@0+ (1,0) [0|15] ""  CVC_B
 SG_ DKCU_BLE_RSSI_Front_dBm : 71|8@0+ (1,-127) [-127|0] ""  CVC_B
 SG_ DKCU_BLE_RSSI_Right_dBm : 31|8@0+ (1,-127) [-127|0] ""  CVC_B
 SG_ DKCU_BLE_RSSI_Left_dBm : 39|8@0+ (1,-127) [-127|0] ""  CVC_B
 SG_ DKCU_BLE_RSSI_Rear_dBm : 47|8@0+ (1,-127) [-127|0] ""  CVC_B
 SG_ DKCU_BLE_RSSI_MasterECU_dBm : 55|8@0+ (1,-127) [-127|0] ""  CVC_B
 SG_ DKCU_UWB_ConfLvl_Front_dBm : 63|8@0+ (1,-127) [-127|0] ""  CVC_B
 SG_ DKCU_UWB_ConfLvl_Right_dBm : 23|8@0+ (1,-127) [-127|0] ""  CVC_B
 SG_ DKCU_UWB_ConfLvl_Left_dBm : 79|8@0+ (1,-127) [-127|0] ""  CVC_B
 SG_ DKCU_UWB_ConfLvl_Rear_dBm : 87|8@0+ (1,-127) [-127|0] ""  CVC_B
 SG_ DKCU_UWB_ConfLvl_MasterECU_dBm : 95|8@0+ (1,-127) [-127|0] ""  CVC_B
 SG_ DKCU_UWB_ConfLvl_CPD_dBm : 103|8@0+ (1,-127) [-127|0] ""  CVC_B

BO_ 1012 DK_WarnMsg: 8 DKCU
 SG_ CRC_DK_WarnMsg : 7|8@0+ (1,0) [0|255] ""  CVC_B
 SG_ ALIVE_DK_WarnMsg : 11|4@0+ (1,0) [0|15] ""  CVC_B
 SG_ DKAnchor_FrontAnchorStatus_A1 : 12|1@0+ (1,0) [0|1] ""  CVC_B
 SG_ DKAnchor_LeftAnchorStatus_A2 : 13|1@0+ (1,0) [0|1] ""  CVC_B
 SG_ DKAnchor_RightAnchorStatus_A3 : 14|1@0+ (1,0) [0|1] ""  CVC_B
 SG_ DKAnchor_RearAnchorStatus_A4 : 15|1@0+ (1,0) [0|1] ""  CVC_B
 SG_ DKAnchor_DKCUAnchorStatus_A5 : 16|1@0+ (1,0) [0|1] ""  CVC_B
 SG_ DKAnchor_CPDAnchorStatus_A6 : 17|1@0+ (1,0) [0|1] ""  CVC_B
 SG_ DKAnchor_ExtNFCStatus_A7 : 18|1@0+ (1,0) [0|1] ""  CVC_B
 SG_ DKAnchor_IntNFCStatus_A8 : 19|1@0+ (1,0) [0|1] ""  CVC_B
 SG_ DK_PhoneKeyPanicAlarmAlert : 20|1@0+ (1,0) [0|1] ""  CVC_B
 SG_ DK_PhoneKeyBattLowAlert : 21|1@0+ (1,0) [0|1] ""  CVC_B
 SG_ DK_PhoneKeyIdleStsAlert : 22|1@0+ (1,0) [0|1] ""  CVC_B
 SG_ DK_VehicleIdleStsAlert : 23|1@0+ (1,0) [0|1] ""  CVC_B
 SG_ DK_BleOnOffStsAlert : 24|1@0+ (1,0) [0|1] ""  CVC_B
 SG_ DK_LeftCarAlert : 25|1@0+ (1,0) [0|1] ""  CVC_B
 SG_ DK_AuthFailAlert : 26|1@0+ (1,0) [0|1] ""  CVC_B
 SG_ DK_PhoneKeyForgotInsideAlert : 27|1@0+ (1,0) [0|1] ""  CVC_B
 SG_ DK_PhoneKeyApproachUnlockAlert : 28|1@0+ (1,0) [0|1] ""  CVC_B
 SG_ DK_PhoneKeyCapabilityAlert : 29|1@0+ (1,0) [0|1] ""  CVC_B
 SG_ DK_PhoneKeyNfcExteriorAuthFailAl : 30|1@0+ (1,0) [0|1] ""  CVC_B
 SG_ DK_PhoneKeyNfcInteriorAuthFailAl : 31|1@0+ (1,0) [0|1] ""  CVC_B
 SG_ DK_PhoneKeyTrunkClosingAlert : 32|1@0+ (1,0) [0|1] ""  CVC_B
 SG_ DK_PhoneKeyWalkawayLockFailAlert : 33|1@0+ (1,0) [0|1] ""  CVC_B
 SG_ DK_PhoneKeyRemoteBLECmdFailAlert : 34|1@0+ (1,0) [0|1] ""  CVC_B

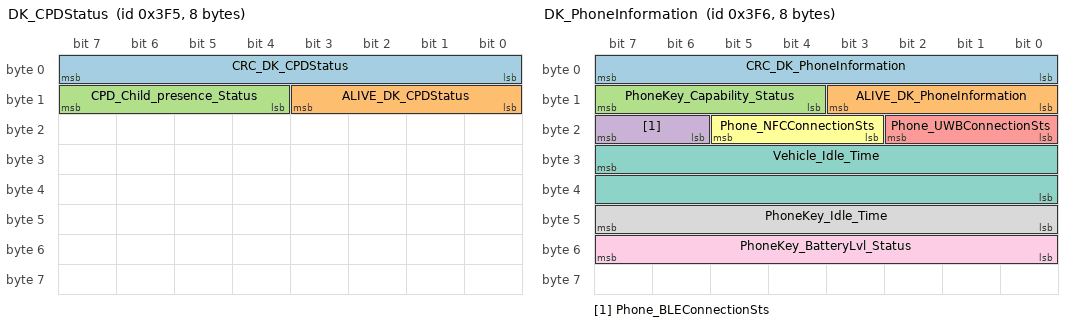
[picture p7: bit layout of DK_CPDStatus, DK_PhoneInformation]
BO_ 1013 DK_CPDStatus: 8 DKCU
 SG_ CRC_DK_CPDStatus : 7|8@0+ (1,0) [0|255] ""  CVC_B
 SG_ ALIVE_DK_CPDStatus : 11|4@0+ (1,0) [0|15] ""  CVC_B
 SG_ CPD_Child_presence_Status : 15|4@0+ (1,0) [0|15] ""  CVC_B

BO_ 1014 DK_PhoneInformation: 8 DKCU
 SG_ CRC_DK_PhoneInformation : 7|8@0+ (1,0) [0|255] ""  CVC_B
 SG_ ALIVE_DK_PhoneInformation : 11|4@0+ (1,0) [0|15] ""  CVC_B
 SG_ PhoneKey_Capability_Status : 15|4@0+ (1,0) [0|15] ""  CVC_B
 SG_ Phone_BLEConnectionSts : 23|2@0+ (1,0) [0|3] ""  CVC_B
 SG_ Phone_UWBConnectionSts : 18|3@0+ (1,0) [0|7] ""  CVC_B
 SG_ Phone_NFCConnectionSts : 21|3@0+ (1,0) [0|7] ""  CVC_B
 SG_ Vehicle_Idle_Time : 31|16@0+ (1,0) [0|65535] ""  CVC_B
 SG_ PhoneKey_Idle_Time : 47|8@0+ (1,0) [0|255] ""  CVC_B
 SG_ PhoneKey_BatteryLvl_Status : 55|8@0+ (1,0) [0|100] ""  CVC_B

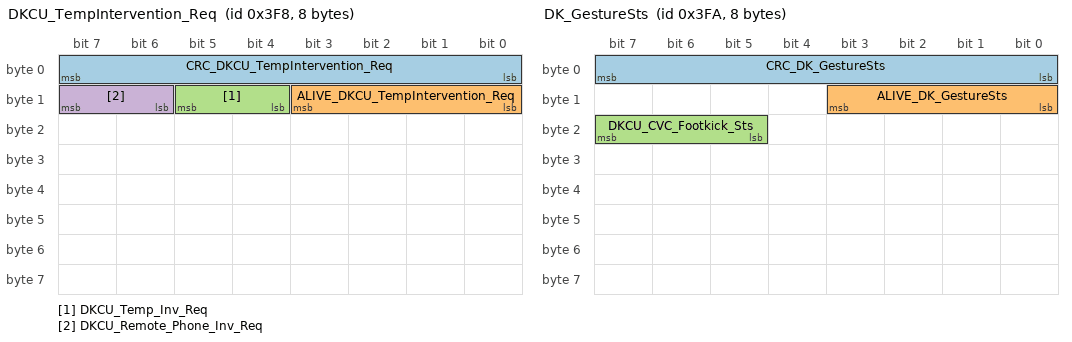
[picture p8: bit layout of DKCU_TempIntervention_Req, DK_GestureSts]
BO_ 1016 DKCU_TempIntervention_Req: 8 DKCU
 SG_ CRC_DKCU_TempIntervention_Req : 7|8@0+ (1,0) [0|255] ""  CVC_B
 SG_ ALIVE_DKCU_TempIntervention_Req : 11|4@0+ (1,0) [0|15] ""  CVC_B
 SG_ DKCU_Temp_Inv_Req : 13|2@0+ (1,0) [0|3] ""  CVC_B
 SG_ DKCU_Remote_Phone_Inv_Req : 15|2@0+ (1,0) [0|3] ""  CVC_B

BO_ 1018 DK_GestureSts: 8 DKCU
 SG_ CRC_DK_GestureSts : 7|8@0+ (1,0) [0|255] ""  CVC_B
 SG_ ALIVE_DK_GestureSts : 11|4@0+ (1,0) [0|15] ""  CVC_B
 SG_ DKCU_CVC_Footkick_Sts : 23|3@0+ (1,0) [0|7] ""  CVC_B

BO_ 1974 DKCU_Synchronization_Req: 8 DKCU
 SG_ DKCU_Req_RandomData : 7|24@0+ (1,0) [0|16777215] ""  CVC_B
 SG_ DKCU_Req_MAC : 31|40@0+ (1,0) [0|1099511627775] ""  CVC_B

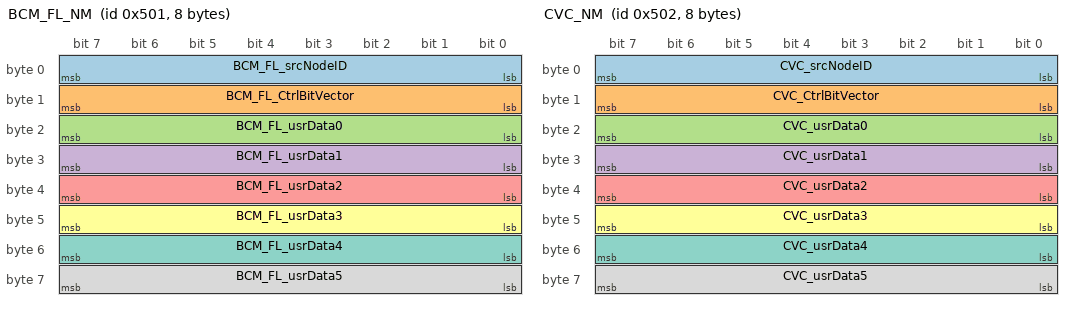
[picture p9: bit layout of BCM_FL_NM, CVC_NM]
BO_ 1281 BCM_FL_NM: 8 BCM_FL
 SG_ BCM_FL_srcNodeID : 7|8@0+ (1,0) [0|255] ""  CVC_B,BCM_FR,DKCU,BCM_R
 SG_ BCM_FL_CtrlBitVector : 15|8@0+ (1,0) [0|255] ""  CVC_B,BCM_FR,DKCU,BCM_R
 SG_ BCM_FL_usrData0 : 23|8@0+ (1,0) [0|255] ""  CVC_B,BCM_FR,DKCU,BCM_R
 SG_ BCM_FL_usrData1 : 31|8@0+ (1,0) [0|255] ""  CVC_B,BCM_FR,DKCU,BCM_R
 SG_ BCM_FL_usrData2 : 39|8@0+ (1,0) [0|255] ""  CVC_B,BCM_FR,DKCU,BCM_R
 SG_ BCM_FL_usrData3 : 47|8@0+ (1,0) [0|255] ""  CVC_B,BCM_FR,DKCU,BCM_R
 SG_ BCM_FL_usrData4 : 55|8@0+ (1,0) [0|255] ""  CVC_B,BCM_FR,DKCU,BCM_R
 SG_ BCM_FL_usrData5 : 63|8@0+ (1,0) [0|255] ""  CVC_B,BCM_FR,DKCU,BCM_R

BO_ 1282 CVC_NM: 8 CVC_B
 SG_ CVC_srcNodeID : 7|8@0+ (1,0) [0|255] ""  BCM_FL,BCM_FR,DKCU,BCM_R
 SG_ CVC_CtrlBitVector : 15|8@0+ (1,0) [0|255] ""  BCM_FL,BCM_FR,DKCU,BCM_R
 SG_ CVC_usrData0 : 23|8@0+ (1,0) [0|255] ""  BCM_FL,BCM_FR,DKCU,BCM_R
 SG_ CVC_usrData1 : 31|8@0+ (1,0) [0|255] ""  BCM_FL,BCM_FR,DKCU,BCM_R
 SG_ CVC_usrData2 : 39|8@0+ (1,0) [0|255] ""  BCM_FL,BCM_FR,DKCU,BCM_R
 SG_ CVC_usrData3 : 47|8@0+ (1,0) [0|255] ""  BCM_FL,BCM_FR,DKCU,BCM_R
 SG_ CVC_usrData4 : 55|8@0+ (1,0) [0|255] ""  BCM_FL,BCM_FR,DKCU,BCM_R
 SG_ CVC_usrData5 : 63|8@0+ (1,0) [0|255] ""  BCM_FL,BCM_FR,DKCU,BCM_R

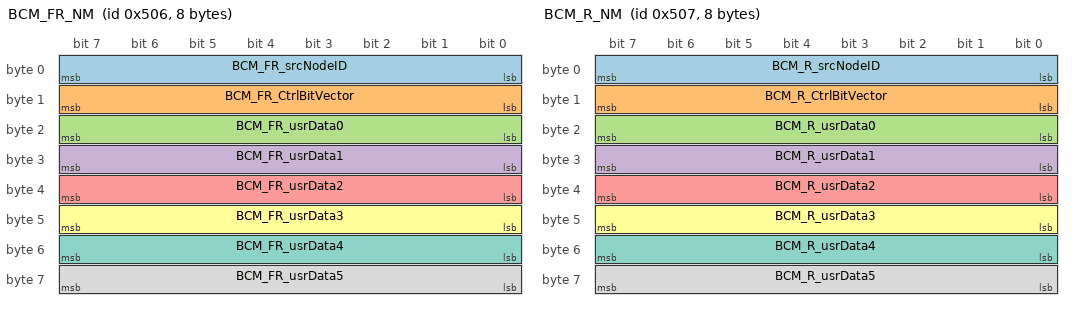
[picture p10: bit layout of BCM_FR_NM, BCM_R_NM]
BO_ 1286 BCM_FR_NM: 8 BCM_FR
 SG_ BCM_FR_srcNodeID : 7|8@0+ (1,0) [0|255] ""  CVC_B,BCM_FL,DKCU,BCM_R
 SG_ BCM_FR_CtrlBitVector : 15|8@0+ (1,0) [0|255] ""  CVC_B,BCM_FL,DKCU,BCM_R
 SG_ BCM_FR_usrData0 : 23|8@0+ (1,0) [0|255] ""  CVC_B,BCM_FL,DKCU,BCM_R
 SG_ BCM_FR_usrData1 : 31|8@0+ (1,0) [0|255] ""  CVC_B,BCM_FL,DKCU,BCM_R
 SG_ BCM_FR_usrData2 : 39|8@0+ (1,0) [0|255] ""  CVC_B,BCM_FL,DKCU,BCM_R
 SG_ BCM_FR_usrData3 : 47|8@0+ (1,0) [0|255] ""  CVC_B,BCM_FL,DKCU,BCM_R
 SG_ BCM_FR_usrData4 : 55|8@0+ (1,0) [0|255] ""  CVC_B,BCM_FL,DKCU,BCM_R
 SG_ BCM_FR_usrData5 : 63|8@0+ (1,0) [0|255] ""  CVC_B,BCM_FL,DKCU,BCM_R

BO_ 1287 BCM_R_NM: 8 BCM_R
 SG_ BCM_R_srcNodeID : 7|8@0+ (1,0) [0|255] ""  CVC_B,BCM_FL,BCM_FR,DKCU
 SG_ BCM_R_CtrlBitVector : 15|8@0+ (1,0) [0|255] ""  CVC_B,BCM_FL,BCM_FR,DKCU
 SG_ BCM_R_usrData0 : 23|8@0+ (1,0) [0|255] ""  CVC_B,BCM_FL,BCM_FR,DKCU
 SG_ BCM_R_usrData1 : 31|8@0+ (1,0) [0|255] ""  CVC_B,BCM_FL,BCM_FR,DKCU
 SG_ BCM_R_usrData2 : 39|8@0+ (1,0) [0|255] ""  CVC_B,BCM_FL,BCM_FR,DKCU
 SG_ BCM_R_usrData3 : 47|8@0+ (1,0) [0|255] ""  CVC_B,BCM_FL,BCM_FR,DKCU
 SG_ BCM_R_usrData4 : 55|8@0+ (1,0) [0|255] ""  CVC_B,BCM_FL,BCM_FR,DKCU
 SG_ BCM_R_usrData5 : 63|8@0+ (1,0) [0|255] ""  CVC_B,BCM_FL,BCM_FR,DKCU

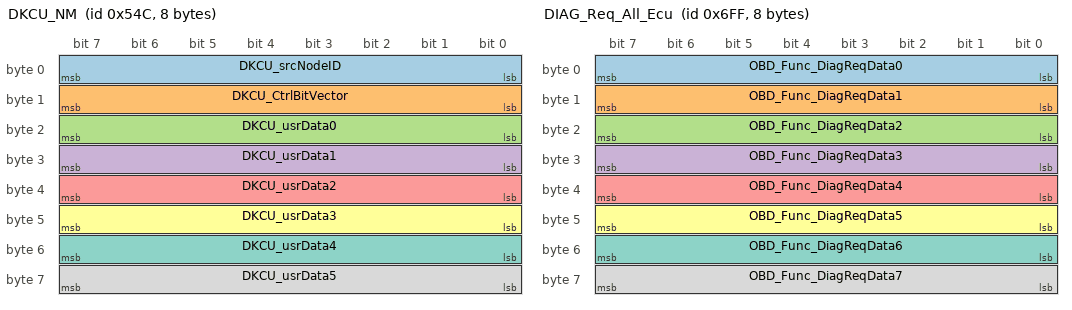
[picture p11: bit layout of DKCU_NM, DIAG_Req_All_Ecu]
BO_ 1356 DKCU_NM: 8 DKCU
 SG_ DKCU_srcNodeID : 7|8@0+ (1,0) [0|255] ""  CVC_B,BCM_FL,BCM_FR,BCM_R
 SG_ DKCU_CtrlBitVector : 15|8@0+ (1,0) [0|255] ""  CVC_B,BCM_FL,BCM_FR,BCM_R
 SG_ DKCU_usrData0 : 23|8@0+ (1,0) [0|255] ""  CVC_B,BCM_FL,BCM_FR,BCM_R
 SG_ DKCU_usrData1 : 31|8@0+ (1,0) [0|255] ""  CVC_B,BCM_FL,BCM_FR,BCM_R
 SG_ DKCU_usrData2 : 39|8@0+ (1,0) [0|255] ""  CVC_B,BCM_FL,BCM_FR,BCM_R
 SG_ DKCU_usrData3 : 47|8@0+ (1,0) [0|255] ""  CVC_B,BCM_FL,BCM_FR,BCM_R
 SG_ DKCU_usrData4 : 55|8@0+ (1,0) [0|255] ""  CVC_B,BCM_FL,BCM_FR,BCM_R
 SG_ DKCU_usrData5 : 63|8@0+ (1,0) [0|255] ""  CVC_B,BCM_FL,BCM_FR,BCM_R

BO_ 1537 BCM_FL_DiagResp: 64 BCM_FL
 SG_ BCM_FL_DiagRespData0 : 7|8@0+ (1,0) [0|255] ""  CVC_B
 SG_ BCM_FL_DiagRespData1 : 15|8@0+ (1,0) [0|255] ""  CVC_B
 SG_ BCM_FL_DiagRespData2 : 23|8@0+ (1,0) [0|255] ""  CVC_B
 SG_ BCM_FL_DiagRespData3 : 31|8@0+ (1,0) [0|255] ""  CVC_B
 SG_ BCM_FL_DiagRespData4 : 39|8@0+ (1,0) [0|255] ""  CVC_B
 SG_ BCM_FL_DiagRespData5 : 47|8@0+ (1,0) [0|255] ""  CVC_B
 SG_ BCM_FL_DiagRespData6 : 55|8@0+ (1,0) [0|255] ""  CVC_B
 SG_ BCM_FL_DiagRespData7 : 63|8@0+ (1,0) [0|255] ""  CVC_B
 SG_ BCM_FL_DiagRespData8 : 71|8@0+ (1,0) [0|255] ""  CVC_B
 SG_ BCM_FL_DiagRespData9 : 79|8@0+ (1,0) [0|255] ""  CVC_B
 SG_ BCM_FL_DiagRespData10 : 87|8@0+ (1,0) [0|255] ""  CVC_B
 SG_ BCM_FL_DiagRespData11 : 95|8@0+ (1,0) [0|255] ""  CVC_B
 SG_ BCM_FL_DiagRespData12 : 103|8@0+ (1,0) [0|255] ""  CVC_B
 SG_ BCM_FL_DiagRespData13 : 111|8@0+ (1,0) [0|255] ""  CVC_B
 SG_ BCM_FL_DiagRespData14 : 119|8@0+ (1,0) [0|255] ""  CVC_B
 SG_ BCM_FL_DiagRespData15 : 127|8@0+ (1,0) [0|255] ""  CVC_B
 SG_ BCM_FL_DiagRespData16 : 135|8@0+ (1,0) [0|255] ""  CVC_B
 SG_ BCM_FL_DiagRespData17 : 143|8@0+ (1,0) [0|255] ""  CVC_B
 SG_ BCM_FL_DiagRespData18 : 151|8@0+ (1,0) [0|255] ""  CVC_B
 SG_ BCM_FL_DiagRespData19 : 159|8@0+ (1,0) [0|255] ""  CVC_B
 SG_ BCM_FL_DiagRespData20 : 167|8@0+ (1,0) [0|255] ""  CVC_B
 SG_ BCM_FL_DiagRespData21 : 175|8@0+ (1,0) [0|255] ""  CVC_B
 SG_ BCM_FL_DiagRespData22 : 183|8@0+ (1,0) [0|255] ""  CVC_B
 SG_ BCM_FL_DiagRespData23 : 191|8@0+ (1,0) [0|255] ""  CVC_B
 SG_ BCM_FL_DiagRespData24 : 199|8@0+ (1,0) [0|255] ""  CVC_B
 SG_ BCM_FL_DiagRespData25 : 207|8@0+ (1,0) [0|255] ""  CVC_B
 SG_ BCM_FL_DiagRespData26 : 215|8@0+ (1,0) [0|255] ""  CVC_B
 SG_ BCM_FL_DiagRespData27 : 223|8@0+ (1,0) [0|255] ""  CVC_B
 SG_ BCM_FL_DiagRespData28 : 231|8@0+ (1,0) [0|255] ""  CVC_B
 SG_ BCM_FL_DiagRespData29 : 239|8@0+ (1,0) [0|255] ""  CVC_B
 SG_ BCM_FL_DiagRespData30 : 247|8@0+ (1,0) [0|255] ""  CVC_B
 SG_ BCM_FL_DiagRespData31 : 255|8@0+ (1,0) [0|255] ""  CVC_B
 SG_ BCM_FL_DiagRespData32 : 263|8@0+ (1,0) [0|255] ""  CVC_B
 SG_ BCM_FL_DiagRespData33 : 271|8@0+ (1,0) [0|255] ""  CVC_B
 SG_ BCM_FL_DiagRespData34 : 279|8@0+ (1,0) [0|255] ""  CVC_B
 SG_ BCM_FL_DiagRespData35 : 287|8@0+ (1,0) [0|255] ""  CVC_B
 SG_ BCM_FL_DiagRespData36 : 295|8@0+ (1,0) [0|255] ""  CVC_B
 SG_ BCM_FL_DiagRespData37 : 303|8@0+ (1,0) [0|255] ""  CVC_B
 SG_ BCM_FL_DiagRespData38 : 311|8@0+ (1,0) [0|255] ""  CVC_B
 SG_ BCM_FL_DiagRespData39 : 319|8@0+ (1,0) [0|255] ""  CVC_B
 SG_ BCM_FL_DiagRespData40 : 327|8@0+ (1,0) [0|255] ""  CVC_B
 SG_ BCM_FL_DiagRespData41 : 335|8@0+ (1,0) [0|255] ""  CVC_B
 SG_ BCM_FL_DiagRespData42 : 343|8@0+ (1,0) [0|255] ""  CVC_B
 SG_ BCM_FL_DiagRespData43 : 351|8@0+ (1,0) [0|255] ""  CVC_B
 SG_ BCM_FL_DiagRespData44 : 359|8@0+ (1,0) [0|255] ""  CVC_B
 SG_ BCM_FL_DiagRespData45 : 367|8@0+ (1,0) [0|255] ""  CVC_B
 SG_ BCM_FL_DiagRespData46 : 375|8@0+ (1,0) [0|255] ""  CVC_B
 SG_ BCM_FL_DiagRespData47 : 383|8@0+ (1,0) [0|255] ""  CVC_B
 SG_ BCM_FL_DiagRespData48 : 391|8@0+ (1,0) [0|255] ""  CVC_B
 SG_ BCM_FL_DiagRespData49 : 399|8@0+ (1,0) [0|255] ""  CVC_B
 SG_ BCM_FL_DiagRespData50 : 407|8@0+ (1,0) [0|255] ""  CVC_B
 SG_ BCM_FL_DiagRespData51 : 415|8@0+ (1,0) [0|255] ""  CVC_B
 SG_ BCM_FL_DiagRespData52 : 423|8@0+ (1,0) [0|255] ""  CVC_B
 SG_ BCM_FL_DiagRespData53 : 431|8@0+ (1,0) [0|255] ""  CVC_B
 SG_ BCM_FL_DiagRespData54 : 439|8@0+ (1,0) [0|255] ""  CVC_B
 SG_ BCM_FL_DiagRespData55 : 447|8@0+ (1,0) [0|255] ""  CVC_B
 SG_ BCM_FL_DiagRespData56 : 455|8@0+ (1,0) [0|255] ""  CVC_B
 SG_ BCM_FL_DiagRespData57 : 463|8@0+ (1,0) [0|255] ""  CVC_B
 SG_ BCM_FL_DiagRespData58 : 471|8@0+ (1,0) [0|255] ""  CVC_B
 SG_ BCM_FL_DiagRespData59 : 479|8@0+ (1,0) [0|255] ""  CVC_B
 SG_ BCM_FL_DiagRespData60 : 487|8@0+ (1,0) [0|255] ""  CVC_B
 SG_ BCM_FL_DiagRespData61 : 495|8@0+ (1,0) [0|255] ""  CVC_B
 SG_ BCM_FL_DiagRespData62 : 503|8@0+ (1,0) [0|255] ""  CVC_B
 SG_ BCM_FL_DiagRespData63 : 511|8@0+ (1,0) [0|255] ""  CVC_B

BO_ 1665 BCM_FL_DiagReq: 64 CVC_B
 SG_ BCM_FL_DiagReqData0 : 7|8@0+ (1,0) [0|255] ""  BCM_FL
 SG_ BCM_FL_DiagReqData1 : 15|8@0+ (1,0) [0|255] ""  BCM_FL
 SG_ BCM_FL_DiagReqData2 : 23|8@0+ (1,0) [0|255] ""  BCM_FL
 SG_ BCM_FL_DiagReqData3 : 31|8@0+ (1,0) [0|255] ""  BCM_FL
 SG_ BCM_FL_DiagReqData4 : 39|8@0+ (1,0) [0|255] ""  BCM_FL
 SG_ BCM_FL_DiagReqData5 : 47|8@0+ (1,0) [0|255] ""  BCM_FL
 SG_ BCM_FL_DiagReqData6 : 55|8@0+ (1,0) [0|255] ""  BCM_FL
 SG_ BCM_FL_DiagReqData7 : 63|8@0+ (1,0) [0|255] ""  BCM_FL
 SG_ BCM_FL_DiagReqData8 : 71|8@0+ (1,0) [0|255] ""  BCM_FL
 SG_ BCM_FL_DiagReqData9 : 79|8@0+ (1,0) [0|255] ""  BCM_FL
 SG_ BCM_FL_DiagReqData10 : 87|8@0+ (1,0) [0|255] ""  BCM_FL
 SG_ BCM_FL_DiagReqData11 : 95|8@0+ (1,0) [0|255] ""  BCM_FL
 SG_ BCM_FL_DiagReqData12 : 103|8@0+ (1,0) [0|255] ""  BCM_FL
 SG_ BCM_FL_DiagReqData13 : 111|8@0+ (1,0) [0|255] ""  BCM_FL
 SG_ BCM_FL_DiagReqData14 : 119|8@0+ (1,0) [0|255] ""  BCM_FL
 SG_ BCM_FL_DiagReqData15 : 127|8@0+ (1,0) [0|255] ""  BCM_FL
 SG_ BCM_FL_DiagReqData16 : 135|8@0+ (1,0) [0|255] ""  BCM_FL
 SG_ BCM_FL_DiagReqData17 : 143|8@0+ (1,0) [0|255] ""  BCM_FL
 SG_ BCM_FL_DiagReqData18 : 151|8@0+ (1,0) [0|255] ""  BCM_FL
 SG_ BCM_FL_DiagReqData19 : 159|8@0+ (1,0) [0|255] ""  BCM_FL
 SG_ BCM_FL_DiagReqData20 : 167|8@0+ (1,0) [0|255] ""  BCM_FL
 SG_ BCM_FL_DiagReqData21 : 175|8@0+ (1,0) [0|255] ""  BCM_FL
 SG_ BCM_FL_DiagReqData22 : 183|8@0+ (1,0) [0|255] ""  BCM_FL
 SG_ BCM_FL_DiagReqData23 : 191|8@0+ (1,0) [0|255] ""  BCM_FL
 SG_ BCM_FL_DiagReqData24 : 199|8@0+ (1,0) [0|255] ""  BCM_FL
 SG_ BCM_FL_DiagReqData25 : 207|8@0+ (1,0) [0|255] ""  BCM_FL
 SG_ BCM_FL_DiagReqData26 : 215|8@0+ (1,0) [0|255] ""  BCM_FL
 SG_ BCM_FL_DiagReqData27 : 223|8@0+ (1,0) [0|255] ""  BCM_FL
 SG_ BCM_FL_DiagReqData28 : 231|8@0+ (1,0) [0|255] ""  BCM_FL
 SG_ BCM_FL_DiagReqData29 : 239|8@0+ (1,0) [0|255] ""  BCM_FL
 SG_ BCM_FL_DiagReqData30 : 247|8@0+ (1,0) [0|255] ""  BCM_FL
 SG_ BCM_FL_DiagReqData31 : 255|8@0+ (1,0) [0|255] ""  BCM_FL
 SG_ BCM_FL_DiagReqData32 : 263|8@0+ (1,0) [0|255] ""  BCM_FL
 SG_ BCM_FL_DiagReqData33 : 271|8@0+ (1,0) [0|255] ""  BCM_FL
 SG_ BCM_FL_DiagReqData34 : 279|8@0+ (1,0) [0|255] ""  BCM_FL
 SG_ BCM_FL_DiagReqData35 : 287|8@0+ (1,0) [0|255] ""  BCM_FL
 SG_ BCM_FL_DiagReqData36 : 295|8@0+ (1,0) [0|255] ""  BCM_FL
 SG_ BCM_FL_DiagReqData37 : 303|8@0+ (1,0) [0|255] ""  BCM_FL
 SG_ BCM_FL_DiagReqData38 : 311|8@0+ (1,0) [0|255] ""  BCM_FL
 SG_ BCM_FL_DiagReqData39 : 319|8@0+ (1,0) [0|255] ""  BCM_FL
 SG_ BCM_FL_DiagReqData40 : 327|8@0+ (1,0) [0|255] ""  BCM_FL
 SG_ BCM_FL_DiagReqData41 : 335|8@0+ (1,0) [0|255] ""  BCM_FL
 SG_ BCM_FL_DiagReqData42 : 343|8@0+ (1,0) [0|255] ""  BCM_FL
 SG_ BCM_FL_DiagReqData43 : 351|8@0+ (1,0) [0|255] ""  BCM_FL
 SG_ BCM_FL_DiagReqData44 : 359|8@0+ (1,0) [0|255] ""  BCM_FL
 SG_ BCM_FL_DiagReqData45 : 367|8@0+ (1,0) [0|255] ""  BCM_FL
 SG_ BCM_FL_DiagReqData46 : 375|8@0+ (1,0) [0|255] ""  BCM_FL
 SG_ BCM_FL_DiagReqData47 : 383|8@0+ (1,0) [0|255] ""  BCM_FL
 SG_ BCM_FL_DiagReqData48 : 391|8@0+ (1,0) [0|255] ""  BCM_FL
 SG_ BCM_FL_DiagReqData49 : 399|8@0+ (1,0) [0|255] ""  BCM_FL
 SG_ BCM_FL_DiagReqData50 : 407|8@0+ (1,0) [0|255] ""  BCM_FL
 SG_ BCM_FL_DiagReqData51 : 415|8@0+ (1,0) [0|255] ""  BCM_FL
 SG_ BCM_FL_DiagReqData52 : 423|8@0+ (1,0) [0|255] ""  BCM_FL
 SG_ BCM_FL_DiagReqData53 : 431|8@0+ (1,0) [0|255] ""  BCM_FL
 SG_ BCM_FL_DiagReqData54 : 439|8@0+ (1,0) [0|255] ""  BCM_FL
 SG_ BCM_FL_DiagReqData55 : 447|8@0+ (1,0) [0|255] ""  BCM_FL
 SG_ BCM_FL_DiagReqData56 : 455|8@0+ (1,0) [0|255] ""  BCM_FL
 SG_ BCM_FL_DiagReqData57 : 463|8@0+ (1,0) [0|255] ""  BCM_FL
 SG_ BCM_FL_DiagReqData58 : 471|8@0+ (1,0) [0|255] ""  BCM_FL
 SG_ BCM_FL_DiagReqData59 : 479|8@0+ (1,0) [0|255] ""  BCM_FL
 SG_ BCM_FL_DiagReqData60 : 487|8@0+ (1,0) [0|255] ""  BCM_FL
 SG_ BCM_FL_DiagReqData61 : 495|8@0+ (1,0) [0|255] ""  BCM_FL
 SG_ BCM_FL_DiagReqData62 : 503|8@0+ (1,0) [0|255] ""  BCM_FL
 SG_ BCM_FL_DiagReqData63 : 511|8@0+ (1,0) [0|255] ""  BCM_FL

BO_ 1542 BCM_FR_DiagResp: 64 BCM_FR
 SG_ BCM_FR_DiagRespData0 : 7|8@0+ (1,0) [0|255] ""  CVC_B
 SG_ BCM_FR_DiagRespData1 : 15|8@0+ (1,0) [0|255] ""  CVC_B
 SG_ BCM_FR_DiagRespData2 : 23|8@0+ (1,0) [0|255] ""  CVC_B
 SG_ BCM_FR_DiagRespData3 : 31|8@0+ (1,0) [0|255] ""  CVC_B
 SG_ BCM_FR_DiagRespData4 : 39|8@0+ (1,0) [0|255] ""  CVC_B
 SG_ BCM_FR_DiagRespData5 : 47|8@0+ (1,0) [0|255] ""  CVC_B
 SG_ BCM_FR_DiagRespData6 : 55|8@0+ (1,0) [0|255] ""  CVC_B
 SG_ BCM_FR_DiagRespData7 : 63|8@0+ (1,0) [0|255] ""  CVC_B
 SG_ BCM_FR_DiagRespData8 : 71|8@0+ (1,0) [0|255] ""  CVC_B
 SG_ BCM_FR_DiagRespData9 : 79|8@0+ (1,0) [0|255] ""  CVC_B
 SG_ BCM_FR_DiagRespData10 : 87|8@0+ (1,0) [0|255] ""  CVC_B
 SG_ BCM_FR_DiagRespData11 : 95|8@0+ (1,0) [0|255] ""  CVC_B
 SG_ BCM_FR_DiagRespData12 : 103|8@0+ (1,0) [0|255] ""  CVC_B
 SG_ BCM_FR_DiagRespData13 : 111|8@0+ (1,0) [0|255] ""  CVC_B
 SG_ BCM_FR_DiagRespData14 : 119|8@0+ (1,0) [0|255] ""  CVC_B
 SG_ BCM_FR_DiagRespData15 : 127|8@0+ (1,0) [0|255] ""  CVC_B
 SG_ BCM_FR_DiagRespData16 : 135|8@0+ (1,0) [0|255] ""  CVC_B
 SG_ BCM_FR_DiagRespData17 : 143|8@0+ (1,0) [0|255] ""  CVC_B
 SG_ BCM_FR_DiagRespData18 : 151|8@0+ (1,0) [0|255] ""  CVC_B
 SG_ BCM_FR_DiagRespData19 : 159|8@0+ (1,0) [0|255] ""  CVC_B
 SG_ BCM_FR_DiagRespData20 : 167|8@0+ (1,0) [0|255] ""  CVC_B
 SG_ BCM_FR_DiagRespData21 : 175|8@0+ (1,0) [0|255] ""  CVC_B
 SG_ BCM_FR_DiagRespData22 : 183|8@0+ (1,0) [0|255] ""  CVC_B
 SG_ BCM_FR_DiagRespData23 : 191|8@0+ (1,0) [0|255] ""  CVC_B
 SG_ BCM_FR_DiagRespData24 : 199|8@0+ (1,0) [0|255] ""  CVC_B
 SG_ BCM_FR_DiagRespData25 : 207|8@0+ (1,0) [0|255] ""  CVC_B
 SG_ BCM_FR_DiagRespData26 : 215|8@0+ (1,0) [0|255] ""  CVC_B
 SG_ BCM_FR_DiagRespData27 : 223|8@0+ (1,0) [0|255] ""  CVC_B
 SG_ BCM_FR_DiagRespData28 : 231|8@0+ (1,0) [0|255] ""  CVC_B
 SG_ BCM_FR_DiagRespData29 : 239|8@0+ (1,0) [0|255] ""  CVC_B
 SG_ BCM_FR_DiagRespData30 : 247|8@0+ (1,0) [0|255] ""  CVC_B
 SG_ BCM_FR_DiagRespData31 : 255|8@0+ (1,0) [0|255] ""  CVC_B
 SG_ BCM_FR_DiagRespData32 : 263|8@0+ (1,0) [0|255] ""  CVC_B
 SG_ BCM_FR_DiagRespData33 : 271|8@0+ (1,0) [0|255] ""  CVC_B
 SG_ BCM_FR_DiagRespData34 : 279|8@0+ (1,0) [0|255] ""  CVC_B
 SG_ BCM_FR_DiagRespData35 : 287|8@0+ (1,0) [0|255] ""  CVC_B
 SG_ BCM_FR_DiagRespData36 : 295|8@0+ (1,0) [0|255] ""  CVC_B
 SG_ BCM_FR_DiagRespData37 : 303|8@0+ (1,0) [0|255] ""  CVC_B
 SG_ BCM_FR_DiagRespData38 : 311|8@0+ (1,0) [0|255] ""  CVC_B
 SG_ BCM_FR_DiagRespData39 : 319|8@0+ (1,0) [0|255] ""  CVC_B
 SG_ BCM_FR_DiagRespData40 : 327|8@0+ (1,0) [0|255] ""  CVC_B
 SG_ BCM_FR_DiagRespData41 : 335|8@0+ (1,0) [0|255] ""  CVC_B
 SG_ BCM_FR_DiagRespData42 : 343|8@0+ (1,0) [0|255] ""  CVC_B
 SG_ BCM_FR_DiagRespData43 : 351|8@0+ (1,0) [0|255] ""  CVC_B
 SG_ BCM_FR_DiagRespData44 : 359|8@0+ (1,0) [0|255] ""  CVC_B
 SG_ BCM_FR_DiagRespData45 : 367|8@0+ (1,0) [0|255] ""  CVC_B
 SG_ BCM_FR_DiagRespData46 : 375|8@0+ (1,0) [0|255] ""  CVC_B
 SG_ BCM_FR_DiagRespData47 : 383|8@0+ (1,0) [0|255] ""  CVC_B
 SG_ BCM_FR_DiagRespData48 : 391|8@0+ (1,0) [0|255] ""  CVC_B
 SG_ BCM_FR_DiagRespData49 : 399|8@0+ (1,0) [0|255] ""  CVC_B
 SG_ BCM_FR_DiagRespData50 : 407|8@0+ (1,0) [0|255] ""  CVC_B
 SG_ BCM_FR_DiagRespData51 : 415|8@0+ (1,0) [0|255] ""  CVC_B
 SG_ BCM_FR_DiagRespData52 : 423|8@0+ (1,0) [0|255] ""  CVC_B
 SG_ BCM_FR_DiagRespData53 : 431|8@0+ (1,0) [0|255] ""  CVC_B
 SG_ BCM_FR_DiagRespData54 : 439|8@0+ (1,0) [0|255] ""  CVC_B
 SG_ BCM_FR_DiagRespData55 : 447|8@0+ (1,0) [0|255] ""  CVC_B
 SG_ BCM_FR_DiagRespData56 : 455|8@0+ (1,0) [0|255] ""  CVC_B
 SG_ BCM_FR_DiagRespData57 : 463|8@0+ (1,0) [0|255] ""  CVC_B
 SG_ BCM_FR_DiagRespData58 : 471|8@0+ (1,0) [0|255] ""  CVC_B
 SG_ BCM_FR_DiagRespData59 : 479|8@0+ (1,0) [0|255] ""  CVC_B
 SG_ BCM_FR_DiagRespData60 : 487|8@0+ (1,0) [0|255] ""  CVC_B
 SG_ BCM_FR_DiagRespData61 : 495|8@0+ (1,0) [0|255] ""  CVC_B
 SG_ BCM_FR_DiagRespData62 : 503|8@0+ (1,0) [0|255] ""  CVC_B
 SG_ BCM_FR_DiagRespData63 : 511|8@0+ (1,0) [0|255] ""  CVC_B

BO_ 1670 BCM_FR_DiagReq: 64 CVC_B
 SG_ BCM_FR_DiagReqData0 : 7|8@0+ (1,0) [0|255] ""  BCM_FR
 SG_ BCM_FR_DiagReqData1 : 15|8@0+ (1,0) [0|255] ""  BCM_FR
 SG_ BCM_FR_DiagReqData2 : 23|8@0+ (1,0) [0|255] ""  BCM_FR
 SG_ BCM_FR_DiagReqData3 : 31|8@0+ (1,0) [0|255] ""  BCM_FR
 SG_ BCM_FR_DiagReqData4 : 39|8@0+ (1,0) [0|255] ""  BCM_FR
 SG_ BCM_FR_DiagReqData5 : 47|8@0+ (1,0) [0|255] ""  BCM_FR
 SG_ BCM_FR_DiagReqData6 : 55|8@0+ (1,0) [0|255] ""  BCM_FR
 SG_ BCM_FR_DiagReqData7 : 63|8@0+ (1,0) [0|255] ""  BCM_FR
 SG_ BCM_FR_DiagReqData8 : 71|8@0+ (1,0) [0|255] ""  BCM_FR
 SG_ BCM_FR_DiagReqData9 : 79|8@0+ (1,0) [0|255] ""  BCM_FR
 SG_ BCM_FR_DiagReqData10 : 87|8@0+ (1,0) [0|255] ""  BCM_FR
 SG_ BCM_FR_DiagReqData11 : 95|8@0+ (1,0) [0|255] ""  BCM_FR
 SG_ BCM_FR_DiagReqData12 : 103|8@0+ (1,0) [0|255] ""  BCM_FR
 SG_ BCM_FR_DiagReqData13 : 111|8@0+ (1,0) [0|255] ""  BCM_FR
 SG_ BCM_FR_DiagReqData14 : 119|8@0+ (1,0) [0|255] ""  BCM_FR
 SG_ BCM_FR_DiagReqData15 : 127|8@0+ (1,0) [0|255] ""  BCM_FR
 SG_ BCM_FR_DiagReqData16 : 135|8@0+ (1,0) [0|255] ""  BCM_FR
 SG_ BCM_FR_DiagReqData17 : 143|8@0+ (1,0) [0|255] ""  BCM_FR
 SG_ BCM_FR_DiagReqData18 : 151|8@0+ (1,0) [0|255] ""  BCM_FR
 SG_ BCM_FR_DiagReqData19 : 159|8@0+ (1,0) [0|255] ""  BCM_FR
 SG_ BCM_FR_DiagReqData20 : 167|8@0+ (1,0) [0|255] ""  BCM_FR
 SG_ BCM_FR_DiagReqData21 : 175|8@0+ (1,0) [0|255] ""  BCM_FR
 SG_ BCM_FR_DiagReqData22 : 183|8@0+ (1,0) [0|255] ""  BCM_FR
 SG_ BCM_FR_DiagReqData23 : 191|8@0+ (1,0) [0|255] ""  BCM_FR
 SG_ BCM_FR_DiagReqData24 : 199|8@0+ (1,0) [0|255] ""  BCM_FR
 SG_ BCM_FR_DiagReqData25 : 207|8@0+ (1,0) [0|255] ""  BCM_FR
 SG_ BCM_FR_DiagReqData26 : 215|8@0+ (1,0) [0|255] ""  BCM_FR
 SG_ BCM_FR_DiagReqData27 : 223|8@0+ (1,0) [0|255] ""  BCM_FR
 SG_ BCM_FR_DiagReqData28 : 231|8@0+ (1,0) [0|255] ""  BCM_FR
 SG_ BCM_FR_DiagReqData29 : 239|8@0+ (1,0) [0|255] ""  BCM_FR
 SG_ BCM_FR_DiagReqData30 : 247|8@0+ (1,0) [0|255] ""  BCM_FR
 SG_ BCM_FR_DiagReqData31 : 255|8@0+ (1,0) [0|255] ""  BCM_FR
 SG_ BCM_FR_DiagReqData32 : 263|8@0+ (1,0) [0|255] ""  BCM_FR
 SG_ BCM_FR_DiagReqData33 : 271|8@0+ (1,0) [0|255] ""  BCM_FR
 SG_ BCM_FR_DiagReqData34 : 279|8@0+ (1,0) [0|255] ""  BCM_FR
 SG_ BCM_FR_DiagReqData35 : 287|8@0+ (1,0) [0|255] ""  BCM_FR
 SG_ BCM_FR_DiagReqData36 : 295|8@0+ (1,0) [0|255] ""  BCM_FR
 SG_ BCM_FR_DiagReqData37 : 303|8@0+ (1,0) [0|255] ""  BCM_FR
 SG_ BCM_FR_DiagReqData38 : 311|8@0+ (1,0) [0|255] ""  BCM_FR
 SG_ BCM_FR_DiagReqData39 : 319|8@0+ (1,0) [0|255] ""  BCM_FR
 SG_ BCM_FR_DiagReqData40 : 327|8@0+ (1,0) [0|255] ""  BCM_FR
 SG_ BCM_FR_DiagReqData41 : 335|8@0+ (1,0) [0|255] ""  BCM_FR
 SG_ BCM_FR_DiagReqData42 : 343|8@0+ (1,0) [0|255] ""  BCM_FR
 SG_ BCM_FR_DiagReqData43 : 351|8@0+ (1,0) [0|255] ""  BCM_FR
 SG_ BCM_FR_DiagReqData44 : 359|8@0+ (1,0) [0|255] ""  BCM_FR
 SG_ BCM_FR_DiagReqData45 : 367|8@0+ (1,0) [0|255] ""  BCM_FR
 SG_ BCM_FR_DiagReqData46 : 375|8@0+ (1,0) [0|255] ""  BCM_FR
 SG_ BCM_FR_DiagReqData47 : 383|8@0+ (1,0) [0|255] ""  BCM_FR
 SG_ BCM_FR_DiagReqData48 : 391|8@0+ (1,0) [0|255] ""  BCM_FR
 SG_ BCM_FR_DiagReqData49 : 399|8@0+ (1,0) [0|255] ""  BCM_FR
 SG_ BCM_FR_DiagReqData50 : 407|8@0+ (1,0) [0|255] ""  BCM_FR
 SG_ BCM_FR_DiagReqData51 : 415|8@0+ (1,0) [0|255] ""  BCM_FR
 SG_ BCM_FR_DiagReqData52 : 423|8@0+ (1,0) [0|255] ""  BCM_FR
 SG_ BCM_FR_DiagReqData53 : 431|8@0+ (1,0) [0|255] ""  BCM_FR
 SG_ BCM_FR_DiagReqData54 : 439|8@0+ (1,0) [0|255] ""  BCM_FR
 SG_ BCM_FR_DiagReqData55 : 447|8@0+ (1,0) [0|255] ""  BCM_FR
 SG_ BCM_FR_DiagReqData56 : 455|8@0+ (1,0) [0|255] ""  BCM_FR
 SG_ BCM_FR_DiagReqData57 : 463|8@0+ (1,0) [0|255] ""  BCM_FR
 SG_ BCM_FR_DiagReqData58 : 471|8@0+ (1,0) [0|255] ""  BCM_FR
 SG_ BCM_FR_DiagReqData59 : 479|8@0+ (1,0) [0|255] ""  BCM_FR
 SG_ BCM_FR_DiagReqData60 : 487|8@0+ (1,0) [0|255] ""  BCM_FR
 SG_ BCM_FR_DiagReqData61 : 495|8@0+ (1,0) [0|255] ""  BCM_FR
 SG_ BCM_FR_DiagReqData62 : 503|8@0+ (1,0) [0|255] ""  BCM_FR
 SG_ BCM_FR_DiagReqData63 : 511|8@0+ (1,0) [0|255] ""  BCM_FR

BO_ 1543 BCM_R_DiagResp: 64 BCM_R
 SG_ BCM_R_DiagRespData0 : 7|8@0+ (1,0) [0|255] ""  CVC_B
 SG_ BCM_R_DiagRespData1 : 15|8@0+ (1,0) [0|255] ""  CVC_B
 SG_ BCM_R_DiagRespData2 : 23|8@0+ (1,0) [0|255] ""  CVC_B
 SG_ BCM_R_DiagRespData3 : 31|8@0+ (1,0) [0|255] ""  CVC_B
 SG_ BCM_R_DiagRespData4 : 39|8@0+ (1,0) [0|255] ""  CVC_B
 SG_ BCM_R_DiagRespData5 : 47|8@0+ (1,0) [0|255] ""  CVC_B
 SG_ BCM_R_DiagRespData6 : 55|8@0+ (1,0) [0|255] ""  CVC_B
 SG_ BCM_R_DiagRespData7 : 63|8@0+ (1,0) [0|255] ""  CVC_B
 SG_ BCM_R_DiagRespData8 : 71|8@0+ (1,0) [0|255] ""  CVC_B
 SG_ BCM_R_DiagRespData9 : 79|8@0+ (1,0) [0|255] ""  CVC_B
 SG_ BCM_R_DiagRespData10 : 87|8@0+ (1,0) [0|255] ""  CVC_B
 SG_ BCM_R_DiagRespData11 : 95|8@0+ (1,0) [0|255] ""  CVC_B
 SG_ BCM_R_DiagRespData12 : 103|8@0+ (1,0) [0|255] ""  CVC_B
 SG_ BCM_R_DiagRespData13 : 111|8@0+ (1,0) [0|255] ""  CVC_B
 SG_ BCM_R_DiagRespData14 : 119|8@0+ (1,0) [0|255] ""  CVC_B
 SG_ BCM_R_DiagRespData15 : 127|8@0+ (1,0) [0|255] ""  CVC_B
 SG_ BCM_R_DiagRespData16 : 135|8@0+ (1,0) [0|255] ""  CVC_B
 SG_ BCM_R_DiagRespData17 : 143|8@0+ (1,0) [0|255] ""  CVC_B
 SG_ BCM_R_DiagRespData18 : 151|8@0+ (1,0) [0|255] ""  CVC_B
 SG_ BCM_R_DiagRespData19 : 159|8@0+ (1,0) [0|255] ""  CVC_B
 SG_ BCM_R_DiagRespData20 : 167|8@0+ (1,0) [0|255] ""  CVC_B
 SG_ BCM_R_DiagRespData21 : 175|8@0+ (1,0) [0|255] ""  CVC_B
 SG_ BCM_R_DiagRespData22 : 183|8@0+ (1,0) [0|255] ""  CVC_B
 SG_ BCM_R_DiagRespData23 : 191|8@0+ (1,0) [0|255] ""  CVC_B
 SG_ BCM_R_DiagRespData24 : 199|8@0+ (1,0) [0|255] ""  CVC_B
 SG_ BCM_R_DiagRespData25 : 207|8@0+ (1,0) [0|255] ""  CVC_B
 SG_ BCM_R_DiagRespData26 : 215|8@0+ (1,0) [0|255] ""  CVC_B
 SG_ BCM_R_DiagRespData27 : 223|8@0+ (1,0) [0|255] ""  CVC_B
 SG_ BCM_R_DiagRespData28 : 231|8@0+ (1,0) [0|255] ""  CVC_B
 SG_ BCM_R_DiagRespData29 : 239|8@0+ (1,0) [0|255] ""  CVC_B
 SG_ BCM_R_DiagRespData30 : 247|8@0+ (1,0) [0|255] ""  CVC_B
 SG_ BCM_R_DiagRespData31 : 255|8@0+ (1,0) [0|255] ""  CVC_B
 SG_ BCM_R_DiagRespData32 : 263|8@0+ (1,0) [0|255] ""  CVC_B
 SG_ BCM_R_DiagRespData33 : 271|8@0+ (1,0) [0|255] ""  CVC_B
 SG_ BCM_R_DiagRespData34 : 279|8@0+ (1,0) [0|255] ""  CVC_B
 SG_ BCM_R_DiagRespData35 : 287|8@0+ (1,0) [0|255] ""  CVC_B
 SG_ BCM_R_DiagRespData36 : 295|8@0+ (1,0) [0|255] ""  CVC_B
 SG_ BCM_R_DiagRespData37 : 303|8@0+ (1,0) [0|255] ""  CVC_B
 SG_ BCM_R_DiagRespData38 : 311|8@0+ (1,0) [0|255] ""  CVC_B
 SG_ BCM_R_DiagRespData39 : 319|8@0+ (1,0) [0|255] ""  CVC_B
 SG_ BCM_R_DiagRespData40 : 327|8@0+ (1,0) [0|255] ""  CVC_B
 SG_ BCM_R_DiagRespData41 : 335|8@0+ (1,0) [0|255] ""  CVC_B
 SG_ BCM_R_DiagRespData42 : 343|8@0+ (1,0) [0|255] ""  CVC_B
 SG_ BCM_R_DiagRespData43 : 351|8@0+ (1,0) [0|255] ""  CVC_B
 SG_ BCM_R_DiagRespData44 : 359|8@0+ (1,0) [0|255] ""  CVC_B
 SG_ BCM_R_DiagRespData45 : 367|8@0+ (1,0) [0|255] ""  CVC_B
 SG_ BCM_R_DiagRespData46 : 375|8@0+ (1,0) [0|255] ""  CVC_B
 SG_ BCM_R_DiagRespData47 : 383|8@0+ (1,0) [0|255] ""  CVC_B
 SG_ BCM_R_DiagRespData48 : 391|8@0+ (1,0) [0|255] ""  CVC_B
 SG_ BCM_R_DiagRespData49 : 399|8@0+ (1,0) [0|255] ""  CVC_B
 SG_ BCM_R_DiagRespData50 : 407|8@0+ (1,0) [0|255] ""  CVC_B
 SG_ BCM_R_DiagRespData51 : 415|8@0+ (1,0) [0|255] ""  CVC_B
 SG_ BCM_R_DiagRespData52 : 423|8@0+ (1,0) [0|255] ""  CVC_B
 SG_ BCM_R_DiagRespData53 : 431|8@0+ (1,0) [0|255] ""  CVC_B
 SG_ BCM_R_DiagRespData54 : 439|8@0+ (1,0) [0|255] ""  CVC_B
 SG_ BCM_R_DiagRespData55 : 447|8@0+ (1,0) [0|255] ""  CVC_B
 SG_ BCM_R_DiagRespData56 : 455|8@0+ (1,0) [0|255] ""  CVC_B
 SG_ BCM_R_DiagRespData57 : 463|8@0+ (1,0) [0|255] ""  CVC_B
 SG_ BCM_R_DiagRespData58 : 471|8@0+ (1,0) [0|255] ""  CVC_B
 SG_ BCM_R_DiagRespData59 : 479|8@0+ (1,0) [0|255] ""  CVC_B
 SG_ BCM_R_DiagRespData60 : 487|8@0+ (1,0) [0|255] ""  CVC_B
 SG_ BCM_R_DiagRespData61 : 495|8@0+ (1,0) [0|255] ""  CVC_B
 SG_ BCM_R_DiagRespData62 : 503|8@0+ (1,0) [0|255] ""  CVC_B
 SG_ BCM_R_DiagRespData63 : 511|8@0+ (1,0) [0|255] ""  CVC_B

BO_ 1671 BCM_R_DiagReq: 64 CVC_B
 SG_ BCM_R_DiagReqData0 : 7|8@0+ (1,0) [0|255] ""  BCM_R
 SG_ BCM_R_DiagReqData1 : 15|8@0+ (1,0) [0|255] ""  BCM_R
 SG_ BCM_R_DiagReqData2 : 23|8@0+ (1,0) [0|255] ""  BCM_R
 SG_ BCM_R_DiagReqData3 : 31|8@0+ (1,0) [0|255] ""  BCM_R
 SG_ BCM_R_DiagReqData4 : 39|8@0+ (1,0) [0|255] ""  BCM_R
 SG_ BCM_R_DiagReqData5 : 47|8@0+ (1,0) [0|255] ""  BCM_R
 SG_ BCM_R_DiagReqData6 : 55|8@0+ (1,0) [0|255] ""  BCM_R
 SG_ BCM_R_DiagReqData7 : 63|8@0+ (1,0) [0|255] ""  BCM_R
 SG_ BCM_R_DiagReqData8 : 71|8@0+ (1,0) [0|255] ""  BCM_R
 SG_ BCM_R_DiagReqData9 : 79|8@0+ (1,0) [0|255] ""  BCM_R
 SG_ BCM_R_DiagReqData10 : 87|8@0+ (1,0) [0|255] ""  BCM_R
 SG_ BCM_R_DiagReqData11 : 95|8@0+ (1,0) [0|255] ""  BCM_R
 SG_ BCM_R_DiagReqData12 : 103|8@0+ (1,0) [0|255] ""  BCM_R
 SG_ BCM_R_DiagReqData13 : 111|8@0+ (1,0) [0|255] ""  BCM_R
 SG_ BCM_R_DiagReqData14 : 119|8@0+ (1,0) [0|255] ""  BCM_R
 SG_ BCM_R_DiagReqData15 : 127|8@0+ (1,0) [0|255] ""  BCM_R
 SG_ BCM_R_DiagReqData16 : 135|8@0+ (1,0) [0|255] ""  BCM_R
 SG_ BCM_R_DiagReqData17 : 143|8@0+ (1,0) [0|255] ""  BCM_R
 SG_ BCM_R_DiagReqData18 : 151|8@0+ (1,0) [0|255] ""  BCM_R
 SG_ BCM_R_DiagReqData19 : 159|8@0+ (1,0) [0|255] ""  BCM_R
 SG_ BCM_R_DiagReqData20 : 167|8@0+ (1,0) [0|255] ""  BCM_R
 SG_ BCM_R_DiagReqData21 : 175|8@0+ (1,0) [0|255] ""  BCM_R
 SG_ BCM_R_DiagReqData22 : 183|8@0+ (1,0) [0|255] ""  BCM_R
 SG_ BCM_R_DiagReqData23 : 191|8@0+ (1,0) [0|255] ""  BCM_R
 SG_ BCM_R_DiagReqData24 : 199|8@0+ (1,0) [0|255] ""  BCM_R
 SG_ BCM_R_DiagReqData25 : 207|8@0+ (1,0) [0|255] ""  BCM_R
 SG_ BCM_R_DiagReqData26 : 215|8@0+ (1,0) [0|255] ""  BCM_R
 SG_ BCM_R_DiagReqData27 : 223|8@0+ (1,0) [0|255] ""  BCM_R
 SG_ BCM_R_DiagReqData28 : 231|8@0+ (1,0) [0|255] ""  BCM_R
 SG_ BCM_R_DiagReqData29 : 239|8@0+ (1,0) [0|255] ""  BCM_R
 SG_ BCM_R_DiagReqData30 : 247|8@0+ (1,0) [0|255] ""  BCM_R
 SG_ BCM_R_DiagReqData31 : 255|8@0+ (1,0) [0|255] ""  BCM_R
 SG_ BCM_R_DiagReqData32 : 263|8@0+ (1,0) [0|255] ""  BCM_R
 SG_ BCM_R_DiagReqData33 : 271|8@0+ (1,0) [0|255] ""  BCM_R
 SG_ BCM_R_DiagReqData34 : 279|8@0+ (1,0) [0|255] ""  BCM_R
 SG_ BCM_R_DiagReqData35 : 287|8@0+ (1,0) [0|255] ""  BCM_R
 SG_ BCM_R_DiagReqData36 : 295|8@0+ (1,0) [0|255] ""  BCM_R
 SG_ BCM_R_DiagReqData37 : 303|8@0+ (1,0) [0|255] ""  BCM_R
 SG_ BCM_R_DiagReqData38 : 311|8@0+ (1,0) [0|255] ""  BCM_R
 SG_ BCM_R_DiagReqData39 : 319|8@0+ (1,0) [0|255] ""  BCM_R
 SG_ BCM_R_DiagReqData40 : 327|8@0+ (1,0) [0|255] ""  BCM_R
 SG_ BCM_R_DiagReqData41 : 335|8@0+ (1,0) [0|255] ""  BCM_R
 SG_ BCM_R_DiagReqData42 : 343|8@0+ (1,0) [0|255] ""  BCM_R
 SG_ BCM_R_DiagReqData43 : 351|8@0+ (1,0) [0|255] ""  BCM_R
 SG_ BCM_R_DiagReqData44 : 359|8@0+ (1,0) [0|255] ""  BCM_R
 SG_ BCM_R_DiagReqData45 : 367|8@0+ (1,0) [0|255] ""  BCM_R
 SG_ BCM_R_DiagReqData46 : 375|8@0+ (1,0) [0|255] ""  BCM_R
 SG_ BCM_R_DiagReqData47 : 383|8@0+ (1,0) [0|255] ""  BCM_R
 SG_ BCM_R_DiagReqData48 : 391|8@0+ (1,0) [0|255] ""  BCM_R
 SG_ BCM_R_DiagReqData49 : 399|8@0+ (1,0) [0|255] ""  BCM_R
 SG_ BCM_R_DiagReqData50 : 407|8@0+ (1,0) [0|255] ""  BCM_R
 SG_ BCM_R_DiagReqData51 : 415|8@0+ (1,0) [0|255] ""  BCM_R
 SG_ BCM_R_DiagReqData52 : 423|8@0+ (1,0) [0|255] ""  BCM_R
 SG_ BCM_R_DiagReqData53 : 431|8@0+ (1,0) [0|255] ""  BCM_R
 SG_ BCM_R_DiagReqData54 : 439|8@0+ (1,0) [0|255] ""  BCM_R
 SG_ BCM_R_DiagReqData55 : 447|8@0+ (1,0) [0|255] ""  BCM_R
 SG_ BCM_R_DiagReqData56 : 455|8@0+ (1,0) [0|255] ""  BCM_R
 SG_ BCM_R_DiagReqData57 : 463|8@0+ (1,0) [0|255] ""  BCM_R
 SG_ BCM_R_DiagReqData58 : 471|8@0+ (1,0) [0|255] ""  BCM_R
 SG_ BCM_R_DiagReqData59 : 479|8@0+ (1,0) [0|255] ""  BCM_R
 SG_ BCM_R_DiagReqData60 : 487|8@0+ (1,0) [0|255] ""  BCM_R
 SG_ BCM_R_DiagReqData61 : 495|8@0+ (1,0) [0|255] ""  BCM_R
 SG_ BCM_R_DiagReqData62 : 503|8@0+ (1,0) [0|255] ""  BCM_R
 SG_ BCM_R_DiagReqData63 : 511|8@0+ (1,0) [0|255] ""  BCM_R

BO_ 1612 DKCU_DiagResp: 64 DKCU
 SG_ DKCU_DiagRespData0 : 7|8@0+ (1,0) [0|255] ""  CVC_B
 SG_ DKCU_DiagRespData1 : 15|8@0+ (1,0) [0|255] ""  CVC_B
 SG_ DKCU_DiagRespData2 : 23|8@0+ (1,0) [0|255] ""  CVC_B
 SG_ DKCU_DiagRespData3 : 31|8@0+ (1,0) [0|255] ""  CVC_B
 SG_ DKCU_DiagRespData4 : 39|8@0+ (1,0) [0|255] ""  CVC_B
 SG_ DKCU_DiagRespData5 : 47|8@0+ (1,0) [0|255] ""  CVC_B
 SG_ DKCU_DiagRespData6 : 55|8@0+ (1,0) [0|255] ""  CVC_B
 SG_ DKCU_DiagRespData7 : 63|8@0+ (1,0) [0|255] ""  CVC_B
 SG_ DKCU_DiagRespData8 : 71|8@0+ (1,0) [0|255] ""  CVC_B
 SG_ DKCU_DiagRespData9 : 79|8@0+ (1,0) [0|255] ""  CVC_B
 SG_ DKCU_DiagRespData10 : 87|8@0+ (1,0) [0|255] ""  CVC_B
 SG_ DKCU_DiagRespData11 : 95|8@0+ (1,0) [0|255] ""  CVC_B
 SG_ DKCU_DiagRespData12 : 103|8@0+ (1,0) [0|255] ""  CVC_B
 SG_ DKCU_DiagRespData13 : 111|8@0+ (1,0) [0|255] ""  CVC_B
 SG_ DKCU_DiagRespData14 : 119|8@0+ (1,0) [0|255] ""  CVC_B
 SG_ DKCU_DiagRespData15 : 127|8@0+ (1,0) [0|255] ""  CVC_B
 SG_ DKCU_DiagRespData16 : 135|8@0+ (1,0) [0|255] ""  CVC_B
 SG_ DKCU_DiagRespData17 : 143|8@0+ (1,0) [0|255] ""  CVC_B
 SG_ DKCU_DiagRespData18 : 151|8@0+ (1,0) [0|255] ""  CVC_B
 SG_ DKCU_DiagRespData19 : 159|8@0+ (1,0) [0|255] ""  CVC_B
 SG_ DKCU_DiagRespData20 : 167|8@0+ (1,0) [0|255] ""  CVC_B
 SG_ DKCU_DiagRespData21 : 175|8@0+ (1,0) [0|255] ""  CVC_B
 SG_ DKCU_DiagRespData22 : 183|8@0+ (1,0) [0|255] ""  CVC_B
 SG_ DKCU_DiagRespData23 : 191|8@0+ (1,0) [0|255] ""  CVC_B
 SG_ DKCU_DiagRespData24 : 199|8@0+ (1,0) [0|255] ""  CVC_B
 SG_ DKCU_DiagRespData25 : 207|8@0+ (1,0) [0|255] ""  CVC_B
 SG_ DKCU_DiagRespData26 : 215|8@0+ (1,0) [0|255] ""  CVC_B
 SG_ DKCU_DiagRespData27 : 223|8@0+ (1,0) [0|255] ""  CVC_B
 SG_ DKCU_DiagRespData28 : 231|8@0+ (1,0) [0|255] ""  CVC_B
 SG_ DKCU_DiagRespData29 : 239|8@0+ (1,0) [0|255] ""  CVC_B
 SG_ DKCU_DiagRespData30 : 247|8@0+ (1,0) [0|255] ""  CVC_B
 SG_ DKCU_DiagRespData31 : 255|8@0+ (1,0) [0|255] ""  CVC_B
 SG_ DKCU_DiagRespData32 : 263|8@0+ (1,0) [0|255] ""  CVC_B
 SG_ DKCU_DiagRespData33 : 271|8@0+ (1,0) [0|255] ""  CVC_B
 SG_ DKCU_DiagRespData34 : 279|8@0+ (1,0) [0|255] ""  CVC_B
 SG_ DKCU_DiagRespData35 : 287|8@0+ (1,0) [0|255] ""  CVC_B
 SG_ DKCU_DiagRespData36 : 295|8@0+ (1,0) [0|255] ""  CVC_B
 SG_ DKCU_DiagRespData37 : 303|8@0+ (1,0) [0|255] ""  CVC_B
 SG_ DKCU_DiagRespData38 : 311|8@0+ (1,0) [0|255] ""  CVC_B
 SG_ DKCU_DiagRespData39 : 319|8@0+ (1,0) [0|255] ""  CVC_B
 SG_ DKCU_DiagRespData40 : 327|8@0+ (1,0) [0|255] ""  CVC_B
 SG_ DKCU_DiagRespData41 : 335|8@0+ (1,0) [0|255] ""  CVC_B
 SG_ DKCU_DiagRespData42 : 343|8@0+ (1,0) [0|255] ""  CVC_B
 SG_ DKCU_DiagRespData43 : 351|8@0+ (1,0) [0|255] ""  CVC_B
 SG_ DKCU_DiagRespData44 : 359|8@0+ (1,0) [0|255] ""  CVC_B
 SG_ DKCU_DiagRespData45 : 367|8@0+ (1,0) [0|255] ""  CVC_B
 SG_ DKCU_DiagRespData46 : 375|8@0+ (1,0) [0|255] ""  CVC_B
 SG_ DKCU_DiagRespData47 : 383|8@0+ (1,0) [0|255] ""  CVC_B
 SG_ DKCU_DiagRespData48 : 391|8@0+ (1,0) [0|255] ""  CVC_B
 SG_ DKCU_DiagRespData49 : 399|8@0+ (1,0) [0|255] ""  CVC_B
 SG_ DKCU_DiagRespData50 : 407|8@0+ (1,0) [0|255] ""  CVC_B
 SG_ DKCU_DiagRespData51 : 415|8@0+ (1,0) [0|255] ""  CVC_B
 SG_ DKCU_DiagRespData52 : 423|8@0+ (1,0) [0|255] ""  CVC_B
 SG_ DKCU_DiagRespData53 : 431|8@0+ (1,0) [0|255] ""  CVC_B
 SG_ DKCU_DiagRespData54 : 439|8@0+ (1,0) [0|255] ""  CVC_B
 SG_ DKCU_DiagRespData55 : 447|8@0+ (1,0) [0|255] ""  CVC_B
 SG_ DKCU_DiagRespData56 : 455|8@0+ (1,0) [0|255] ""  CVC_B
 SG_ DKCU_DiagRespData57 : 463|8@0+ (1,0) [0|255] ""  CVC_B
 SG_ DKCU_DiagRespData58 : 471|8@0+ (1,0) [0|255] ""  CVC_B
 SG_ DKCU_DiagRespData59 : 479|8@0+ (1,0) [0|255] ""  CVC_B
 SG_ DKCU_DiagRespData60 : 487|8@0+ (1,0) [0|255] ""  CVC_B
 SG_ DKCU_DiagRespData61 : 495|8@0+ (1,0) [0|255] ""  CVC_B
 SG_ DKCU_DiagRespData62 : 503|8@0+ (1,0) [0|255] ""  CVC_B
 SG_ DKCU_DiagRespData63 : 511|8@0+ (1,0) [0|255] ""  CVC_B

BO_ 1740 DKCU_DiagReq: 64 CVC_B
 SG_ DKCU_DiagReqData0 : 7|8@0+ (1,0) [0|255] ""  DKCU
 SG_ DKCU_DiagReqData1 : 15|8@0+ (1,0) [0|255] ""  DKCU
 SG_ DKCU_DiagReqData2 : 23|8@0+ (1,0) [0|255] ""  DKCU
 SG_ DKCU_DiagReqData3 : 31|8@0+ (1,0) [0|255] ""  DKCU
 SG_ DKCU_DiagReqData4 : 39|8@0+ (1,0) [0|255] ""  DKCU
 SG_ DKCU_DiagReqData5 : 47|8@0+ (1,0) [0|255] ""  DKCU
 SG_ DKCU_DiagReqData6 : 55|8@0+ (1,0) [0|255] ""  DKCU
 SG_ DKCU_DiagReqData7 : 63|8@0+ (1,0) [0|255] ""  DKCU
 SG_ DKCU_DiagReqData8 : 71|8@0+ (1,0) [0|255] ""  DKCU
 SG_ DKCU_DiagReqData9 : 79|8@0+ (1,0) [0|255] ""  DKCU
 SG_ DKCU_DiagReqData10 : 87|8@0+ (1,0) [0|255] ""  DKCU
 SG_ DKCU_DiagReqData11 : 95|8@0+ (1,0) [0|255] ""  DKCU
 SG_ DKCU_DiagReqData12 : 103|8@0+ (1,0) [0|255] ""  DKCU
 SG_ DKCU_DiagReqData13 : 111|8@0+ (1,0) [0|255] ""  DKCU
 SG_ DKCU_DiagReqData14 : 119|8@0+ (1,0) [0|255] ""  DKCU
 SG_ DKCU_DiagReqData15 : 127|8@0+ (1,0) [0|255] ""  DKCU
 SG_ DKCU_DiagReqData16 : 135|8@0+ (1,0) [0|255] ""  DKCU
 SG_ DKCU_DiagReqData17 : 143|8@0+ (1,0) [0|255] ""  DKCU
 SG_ DKCU_DiagReqData18 : 151|8@0+ (1,0) [0|255] ""  DKCU
 SG_ DKCU_DiagReqData19 : 159|8@0+ (1,0) [0|255] ""  DKCU
 SG_ DKCU_DiagReqData20 : 167|8@0+ (1,0) [0|255] ""  DKCU
 SG_ DKCU_DiagReqData21 : 175|8@0+ (1,0) [0|255] ""  DKCU
 SG_ DKCU_DiagReqData22 : 183|8@0+ (1,0) [0|255] ""  DKCU
 SG_ DKCU_DiagReqData23 : 191|8@0+ (1,0) [0|255] ""  DKCU
 SG_ DKCU_DiagReqData24 : 199|8@0+ (1,0) [0|255] ""  DKCU
 SG_ DKCU_DiagReqData25 : 207|8@0+ (1,0) [0|255] ""  DKCU
 SG_ DKCU_DiagReqData26 : 215|8@0+ (1,0) [0|255] ""  DKCU
 SG_ DKCU_DiagReqData27 : 223|8@0+ (1,0) [0|255] ""  DKCU
 SG_ DKCU_DiagReqData28 : 231|8@0+ (1,0) [0|255] ""  DKCU
 SG_ DKCU_DiagReqData29 : 239|8@0+ (1,0) [0|255] ""  DKCU
 SG_ DKCU_DiagReqData30 : 247|8@0+ (1,0) [0|255] ""  DKCU
 SG_ DKCU_DiagReqData31 : 255|8@0+ (1,0) [0|255] ""  DKCU
 SG_ DKCU_DiagReqData32 : 263|8@0+ (1,0) [0|255] ""  DKCU
 SG_ DKCU_DiagReqData33 : 271|8@0+ (1,0) [0|255] ""  DKCU
 SG_ DKCU_DiagReqData34 : 279|8@0+ (1,0) [0|255] ""  DKCU
 SG_ DKCU_DiagReqData35 : 287|8@0+ (1,0) [0|255] ""  DKCU
 SG_ DKCU_DiagReqData36 : 295|8@0+ (1,0) [0|255] ""  DKCU
 SG_ DKCU_DiagReqData37 : 303|8@0+ (1,0) [0|255] ""  DKCU
 SG_ DKCU_DiagReqData38 : 311|8@0+ (1,0) [0|255] ""  DKCU
 SG_ DKCU_DiagReqData39 : 319|8@0+ (1,0) [0|255] ""  DKCU
 SG_ DKCU_DiagReqData40 : 327|8@0+ (1,0) [0|255] ""  DKCU
 SG_ DKCU_DiagReqData41 : 335|8@0+ (1,0) [0|255] ""  DKCU
 SG_ DKCU_DiagReqData42 : 343|8@0+ (1,0) [0|255] ""  DKCU
 SG_ DKCU_DiagReqData43 : 351|8@0+ (1,0) [0|255] ""  DKCU
 SG_ DKCU_DiagReqData44 : 359|8@0+ (1,0) [0|255] ""  DKCU
 SG_ DKCU_DiagReqData45 : 367|8@0+ (1,0) [0|255] ""  DKCU
 SG_ DKCU_DiagReqData46 : 375|8@0+ (1,0) [0|255] ""  DKCU
 SG_ DKCU_DiagReqData47 : 383|8@0+ (1,0) [0|255] ""  DKCU
 SG_ DKCU_DiagReqData48 : 391|8@0+ (1,0) [0|255] ""  DKCU
 SG_ DKCU_DiagReqData49 : 399|8@0+ (1,0) [0|255] ""  DKCU
 SG_ DKCU_DiagReqData50 : 407|8@0+ (1,0) [0|255] ""  DKCU
 SG_ DKCU_DiagReqData51 : 415|8@0+ (1,0) [0|255] ""  DKCU
 SG_ DKCU_DiagReqData52 : 423|8@0+ (1,0) [0|255] ""  DKCU
 SG_ DKCU_DiagReqData53 : 431|8@0+ (1,0) [0|255] ""  DKCU
 SG_ DKCU_DiagReqData54 : 439|8@0+ (1,0) [0|255] ""  DKCU
 SG_ DKCU_DiagReqData55 : 447|8@0+ (1,0) [0|255] ""  DKCU
 SG_ DKCU_DiagReqData56 : 455|8@0+ (1,0) [0|255] ""  DKCU
 SG_ DKCU_DiagReqData57 : 463|8@0+ (1,0) [0|255] ""  DKCU
 SG_ DKCU_DiagReqData58 : 471|8@0+ (1,0) [0|255] ""  DKCU
 SG_ DKCU_DiagReqData59 : 479|8@0+ (1,0) [0|255] ""  DKCU
 SG_ DKCU_DiagReqData60 : 487|8@0+ (1,0) [0|255] ""  DKCU
 SG_ DKCU_DiagReqData61 : 495|8@0+ (1,0) [0|255] ""  DKCU
 SG_ DKCU_DiagReqData62 : 503|8@0+ (1,0) [0|255] ""  DKCU
 SG_ DKCU_DiagReqData63 : 511|8@0+ (1,0) [0|255] ""  DKCU

BO_ 1791 DIAG_Req_All_Ecu: 8 CVC_B
 SG_ OBD_Func_DiagReqData0 : 7|8@0+ (1,0) [0|255] ""  BCM_FL,BCM_FR,DKCU,BCM_R
 SG_ OBD_Func_DiagReqData1 : 15|8@0+ (1,0) [0|255] ""  BCM_FL,BCM_FR,DKCU,BCM_R
 SG_ OBD_Func_DiagReqData2 : 23|8@0+ (1,0) [0|255] ""  BCM_FL,BCM_FR,DKCU,BCM_R
 SG_ OBD_Func_DiagReqData3 : 31|8@0+ (1,0) [0|255] ""  BCM_FL,BCM_FR,DKCU,BCM_R
 SG_ OBD_Func_DiagReqData4 : 39|8@0+ (1,0) [0|255] ""  BCM_FL,BCM_FR,DKCU,BCM_R
 SG_ OBD_Func_DiagReqData5 : 47|8@0+ (1,0) [0|255] ""  BCM_FL,BCM_FR,DKCU,BCM_R
 SG_ OBD_Func_DiagReqData6 : 55|8@0+ (1,0) [0|255] ""  BCM_FL,BCM_FR,DKCU,BCM_R
 SG_ OBD_Func_DiagReqData7 : 63|8@0+ (1,0) [0|255] ""  BCM_FL,BCM_FR,DKCU,BCM_R

CM_ SG_ 189 BCM_R_Windows_AntiPinch_Warn "Feedback anti-pinch status to CVC for HMI warning";
CM_ SG_ 189 BCM_R_Window_Learning_Sts "Feedback learning status to CVC";
CM_ SG_ 189 BCM_R_Window_Suppression_Warn "Feedback the lifter suppression status";
CM_ SG_ 189 BCM_R_tailgate_LockActive "Feedback on the locking status of the tailgate";
CM_ SG_ 189 BCM_R_Window_ThermalProtect "Feedback thermal protection status";
CM_ SG_ 189 BCM_R_tailgate_Error "Feedback the incorrect position of the tailgate to CVC for issuing corresponding warnings on HMI";
CM_ SG_ 253 BCMRE_Rear_Wiper_Park_Pos_Status "Feedback the rear wiper status at parking position";
CM_ SG_ 253 BCMRE_RearWiperWorkingSts "Feedback the rear wiper working status";
CM_ SG_ 253 BCMRE_STAT_RearWiperServiceMode "Feedback the rear wiper service mode";
CM_ SG_ 275 BCM_Stat_SwitchLightBrightness "BCM_Stat_SwitchLightBrightness";
CM_ SG_ 275 BCM_Rear_Wash_Status "Rear Wiper Wash Status";
CM_ SG_ 289 BCMRE_CL30s_RE_Sts "Feedback status of clamp 30s RE side";
CM_ SG_ 289 BCMRE_CL30c_RE_Sts "Feedback status of clamp 30c RE side";
CM_ SG_ 289 BCMRE_CLR_RE_Sts "Feedback status of clamp_R RE side";
CM_ SG_ 289 BCMRE_CL15_RE_Sts "Feedback status of clamp 15 RE side";
CM_ SG_ 289 BCMRE_CL58_RE_Sts "Feedback status of clamp 58 RE side";
CM_ SG_ 325 BCMRE_SOV2_Fault "Rear HVAC SOV Fault";
CM_ SG_ 325 BCMRE_EvapSOV2_Status "Rear HVAC SOV Status";
CM_ SG_ 522 ETG_Lift_Gate_Status "The working status of rear lift gate";
CM_ SG_ 522 ETG_Power_Latch_Status "The working status of power latch";
CM_ SG_ 522 ETG_Latch_Segment "The segment of power latch";
CM_ SG_ 522 ETG_Opening_Percentage "The opening percentage of rear lift gate";
CM_ SG_ 522 ETG_DSW_Status "The status of driver switch";
CM_ SG_ 522 ETG_GSW_Status "The status of gate switch";
CM_ SG_ 522 ETG_LTS_Status "The status of left touch sensor";
CM_ SG_ 522 ETG_RTS_Status "The status of right touch sensor";
CM_ SG_ 522 ETG_HAL_Status "The level status of latch's half switch";
CM_ SG_ 522 ETG_FUL_Status "The level status of latch's full switch";
CM_ SG_ 522 ETG_AJR_Status "The level status of latch's AJAR switch";
CM_ SG_ 522 ETG_NTL_Status "The level status of latch's neutral switch";
CM_ SG_ 522 ETG_ERR_Voltage "The error status of ETG voltage";
CM_ SG_ 522 ETG_ERR_Left_Motor "The error status of left lift motor";
CM_ SG_ 522 ETG_ERR_Right_Motor "The error status of right lift motor";
CM_ SG_ 522 ETG_ERR_Latch "The error status of power latch";
CM_ SG_ 522 ETG_ERR_Hall "The error status of hall signal";
CM_ SG_ 522 ETG_Lift_Motor_Stall "The stall protection status of lift motor";
CM_ SG_ 522 ETG_Lift_Motor_AntiPinch "The antipinch protection status of lift motor";
CM_ SG_ 522 ETG_Lift_Motor_Thermal "The thermal protection status of lift motor";
CM_ SG_ 522 ETG_Power_Latch_Thermal "The thermal protection status of power latch";
CM_ SG_ 522 ETG_Abuse_Protection "The abuse protection status of ETG";
CM_ SG_ 523 FKS_RespError "FMS Error Status";
CM_ SG_ 523 FKS_OpenReq "Hands Free Access Operation Request";
CM_ SG_ 523 FKS_HWError "HW Error is set if error in RAM, ROM or NVRAM is detected.";
CM_ SG_ 523 FKS_AntennaError "Error for Bottom and Top Electrode is set if electrode is not connected, connection is broken or electrod is shorted to GND/VSUP.";
CM_ SG_ 523 FKS_OverVolDected "Over voltage error";
CM_ SG_ 523 FKS_UnderVolDected "Under voltage error";
CM_ SG_ 523 FKS_activate_deactivate "feedback activate or deactivate";
CM_ SG_ 535 BCM_PositionLight_RL_STS "Feedback status of RL position light";
CM_ SG_ 535 BCM_PositionLight_RR_STS "Feedback status of RR position light";
CM_ SG_ 535 BCM_TurnIndicator_RL_STS "Feedback status of RL indicator";
CM_ SG_ 535 BCM_TurnIndicator_RR_STS "Feedback status of RR indicator";
CM_ SG_ 535 BCM_ReverseLamp_RL_STS "Feedback left reverse lamp status";
CM_ SG_ 535 BCM_ReverseLamp_RR_STS "Feedback right reverse lamp status";
CM_ SG_ 535 BCM_BrakeLight_RL_STS "Feedback left brake light status";
CM_ SG_ 535 BCM_BrakeLight_RR_STS "Feedback right brake light status";
CM_ SG_ 535 BCM_RearFogLamp_RR_STS "Feedback Front fog light right";
CM_ SG_ 535 BCM_BrakeLight_Center_STS "Feedback center mounting light status";
CM_ SG_ 535 BCM_LicensePlateLamp_RE_STS "Feedback license plate lamp status";
CM_ SG_ 535 BCM_RearFogLamp_RL_STS "Feedback Front fog light left";
CM_ SG_ 535 BCM_PositionLight_RM_STS "RM Position Light Status";
CM_ SG_ 535 BCM_ParkingLight_RL_STS "RL Parking Light Status";
CM_ SG_ 535 BCM_ParkingLight_RM_STS "RM Parking Light Status";
CM_ SG_ 535 BCM_ParkingLight_RR_STS "RR Parking Light Status";
CM_ SG_ 540 BCM_RE_RLDoorCourtesyLightSts "Left rear door welcome light status";
CM_ SG_ 540 BCM_RE_RRDoorCourtesyLightSts "Right rear door welcome light status";
CM_ SG_ 540 BCM_RE_CargoLightSts "Status of trunk lights";
CM_ SG_ 540 BCM_RE_Rear_3rd_DomeLampSts "Rear roof light status";
CM_ SG_ 540 BCM_RLProjectorLightSts "Left rear projection light status";
CM_ SG_ 540 BCM_RRProjectorLightSts "Right rear projection light status";
CM_ SG_ 784 CCUR_STAT_IonButton "Status if the ionisator is active";
CM_ SG_ 784 CCUR_STAT_Defrost "Status activation of Defrost mode";
CM_ SG_ 784 CCUR_STAT_Auto "Status activation of auto mode";
CM_ SG_ 784 CCUR_STAT_Aircondition "Aircondition status";
CM_ SG_ 784 CCUR_STAT_FlapPos "Request for flap position";
CM_ SG_ 784 CCUR_STAT_FanSpeed "Blower settings Fan Speed for climate system";
CM_ SG_ 784 CCUR_STAT_PTC_Heater "CCU status for PTC heater";
CM_ SG_ 784 CCUR_STAT_OnOff "Status On  Off button for clima";
CM_ SG_ 784 CCUR_STAT_MaxAc "Status activation of MAX AC mode";
CM_ SG_ 784 CCUR_STAT_SyncClimateZone "Status dual clima automatic";
CM_ SG_ 784 CCUR_STAT_RecircFlap "Recirculation flap status, 100% fresh air, 0% recirculation mode";
CM_ SG_ 784 CCUR_STAT_TempRear "CCU status of temperature control driver (displaying temperature)";
CM_ SG_ 1040 BCMRE_RearHeatedWindow "Feedback Rear Demist status";
CM_ SG_ 1056 BCM_STAT_AutoRearWiper "On/Off Auto rear wiper";
CM_ SG_ 1056 BCM_STAT_MirrorFoldSetting "Status MirrorFold Default value =  0x1 Auto Fold ON/Invalid value = 3";
CM_ SG_ 1056 BCM_STAT_IMMO_KeyfobID2 "console as per request of a MHU to link keyfob to a profile - improvement signal";
CM_ SG_ 1056 BCM_STAT_MirrorAutoUnfold "Change Mirror Auto unfold mode";
CM_ SG_ 1056 BCM_STAT_MirrorReverseLink "Mirror Auto Tilt On Reverse Feedback";
CM_ SG_ 1056 BCM_STAT_MirrorDefaultSTATting "Trigger the default Mirror setting";
CM_ SG_ 1056 BCM_STAT_WelcomeTriggerCondition "Confirm Welcome trigger condition";
CM_ SG_ 1056 BCM_STAT_FrontDomeLamp "Confirm setting On/Off/Auto Front Dome Lamp";
CM_ SG_ 1056 BCM_STAT_FollowMeHome "Change follow me home headlamp mode and delay";
CM_ SG_ 1056 BCM_STAT_ExteriorLight "Change Exterior light mode";
CM_ SG_ 1056 BCM_STAT_RemoteLockFeedback "Remote Lock dback: customer can choose light feedback when lock the door with remote key";
CM_ SG_ 1056 BCM_STAT_RemoteDoorUnlock "Settings for Door lock unlock conditions";
CM_ SG_ 1056 BCM_STAT_AutoDoorUnlock "Auto door unlock: When the car is stopped and the shift lever is in ?P? position, selected doors will be unlocked automatically";
CM_ SG_ 1056 BCM_STAT_AmbientLightBrighness "Change Ambient light brighness percent";
CM_ SG_ 1056 BCM_STAT_WiperServiceMode "console as per request of a MHU to link keybof to a";
CM_ SG_ 1056 BCM_STAT_IMMO_KeyfobID "console as per request of a MHU to link keybof to a";
CM_ SG_ 1056 BCM_STAT_RearHeatedWindowMirror "This signal is necessary for the activation or deactivation of the rear screen heating for the rear window and the mirrors.Invalid value = 3";
CM_ SG_ 1056 BCM_STAT_AntiTheftMode "Confirm of setting Anti-theft mode";
CM_ SG_ 1056 BCM_STAT_ClimateKeepOnSts "Climate keep ON feedback status";
CM_ SG_ 1056 BCM_STAT_FKSfeedback "BCM_STAT_FKSfeedback";
CM_ SG_ 1056 SECCAN_CmftCnfrm "Secret portion from Secure CAN algorithm";
CM_ SG_ 1075 BCMRE_STAT_RearDefrost "Status activation of Defrost mode";
CM_ SG_ 1097 CHKSM_RESP_REM_FUNC_APM "Checksum";
CM_ SG_ 1097 RESP_REM_ResponseID_APM "The Service Identifier contains the information which function is requested";
CM_ SG_ 1097 RESP_REM_DataByte0_APM "Data byte for the  remote function";
CM_ SG_ 1097 RESP_REM_DataByte1_APM "Data byte for the  remote function";
CM_ SG_ 1097 RESP_REM_DataByte2_APM "Data byte for the  remote function";
CM_ SG_ 1097 RESP_REM_DataByte3_APM "Data byte for the  remote function";
CM_ SG_ 1097 RESP_REM_DataByte4_APM "Adresse of transmitter for remote functions";
CM_ SG_ 1097 RESP_REM_LengthTyp_APM "Lenght bit identify how long are the response  data";
CM_ SG_ 1097 RESP_REM_DataLength_APM "Lenght of the used data for the remote function response";
CM_ SG_ 1170 AmbLight_Error_Z4 "Status of Ambient Light ColorZone 4";
CM_ SG_ 1170 AmbLight_LinError_Z4 "Status of Ambient Light ColorZone 4";
CM_ SG_ 1170 AmbLight_Error_Z4B "Status of Ambient Light ColorZone 4";
CM_ SG_ 1170 AmbLight_LinError_Z4B "Status of Ambient Light ColorZone 4";
CM_ SG_ 1170 AmbLight_Error_Z5 "Status of Ambient Light ColorZone 5";
CM_ SG_ 1170 AmbLight_LinError_Z5 "Status of Ambient Light ColorZone 5";
CM_ SG_ 1170 AmbLight_Error_Z5B "Status of Ambient Light ColorZone 5";
CM_ SG_ 1170 AmbLight_LinError_Z5B "Status of Ambient Light ColorZone 5";
CM_ SG_ 1170 AmbLight_Error_Z9 "Status of Ambient Light ColorZone 9";
CM_ SG_ 1170 AmbLight_LinError_Z9 "Status of Ambient Light ColorZone 9";
CM_ SG_ 1170 AmbLight_Error_Z10 "Status of Ambient Light ColorZone 10";
CM_ SG_ 1170 AmbLight_LinError_Z10 "Status of Ambient Light ColorZone 10";
CM_ SG_ 1219 CRC_APM_RE_WarnMsg "Checksum";
CM_ SG_ 1219 ALIVE_APM_RE_WarnMsg "Alive Counter";
CM_ SG_ 1219 APM_Malfunction "Anti-pinch module malfunction";
CM_ SG_ 1219 ChildWindowLockStS "Child window lock status";
CM_ SG_ 1219 APM_Warning_Flag_3 "Warning Message Flag, Component owner, Supplier align and define for this signal";
CM_ SG_ 1219 APM_Warning_Flag_4 "Warning Message Flag, Component owner, Supplier align and define for this signal";
CM_ SG_ 1219 APM_Warning_Flag_5 "Warning Message Flag, Component owner, Supplier align and define for this signal";
CM_ SG_ 1219 APM_Warning_Flag_6 "Warning Message Flag, Component owner, Supplier align and define for this signal";
CM_ SG_ 1219 APM_Warning_Flag_7 "Warning Message Flag, Component owner, Supplier align and define for this signal";
CM_ SG_ 1219 APM_Warning_Flag_8 "Warning Message Flag, Component owner, Supplier align and define for this signal";
CM_ SG_ 1219 APM_Warning_Flag_9 "Warning Message Flag, Component owner, Supplier align and define for this signal";
CM_ SG_ 1219 APM_Warning_Flag_10 "Warning Message Flag, Component owner, Supplier align and define for this signal";
CM_ SG_ 1219 APM_Warning_Flag_11 "Warning Message Flag, Component owner, Supplier align and define for this signal";
CM_ SG_ 1219 APM_Warning_Flag_12 "Warning Message Flag, Component owner, Supplier align and define for this signal";
CM_ SG_ 1242 CRC_BCM_R_WarnMsg_R "Checksum BCM Warning Message";
CM_ SG_ 1242 ALIVE_BCM_R_WarnMsg_R "Alive counter";
CM_ SG_ 1242 BCM_R_NoValidKey_1 "Illegal key in the car";
CM_ SG_ 1242 BCM_R_SSB_defect "SSB button defect";
CM_ SG_ 1242 BCM_R_WrongGearPosToStart "Gear position is not P/N, Gear in wrong position to start";
CM_ SG_ 1242 BCM_R_NoValidKey_2 "Key FOBs are not in the car";
CM_ SG_ 1242 BCM_R_PressBrakeToStart "Brake padel not pressed to start the car";
CM_ SG_ 1242 BCM_R_TurnOffPosLightRemindr "Driver forget to turn off Position Lights during leaving car";
CM_ SG_ 1242 BCM_R_KeyFob_LowBattery "Keyfob battery low";
CM_ SG_ 1242 BCM_R_StopLightDefect "Stop light defect";
CM_ SG_ 1242 BCM_R_LowBeamDefect "Low beam defect";
CM_ SG_ 1242 BCM_R_HighBeamDefect "High beam defect";
CM_ SG_ 1242 BCM_R_PositionLightDefect "Position light defect";
CM_ SG_ 1242 BCM_R_CHMLS_Defect "CHMSL defect";
CM_ SG_ 1242 BCM_R_LicencePlateLight_Defect "License plate light defect";
CM_ SG_ 1242 BCM_R_FrontFog_Defect "Front fog lamp malfunction";
CM_ SG_ 1242 BCM_R_RearLeftDoorLockDefect "Defects or malfunctions in the left rear door lock";
CM_ SG_ 1242 BCM_R_ReverseLightDefect "Reverse light defect";
CM_ SG_ 1242 BCM_R_RLS_Malfunction "Rainwater/light sensor malfunction";
CM_ SG_ 1242 BCM_R_12VBattery_LowLevel "Low battery 12V battery";
CM_ SG_ 1242 BCM_R_ForgetKeyFOBInCar "Lock the car when the key is inside";
CM_ SG_ 1242 BCM_R_12VBattery_Discharging "Discharge of 12V battery";
CM_ SG_ 1242 BCM_R_TurnIndicatorDefect "Turn signal malfunction";
CM_ SG_ 1242 BCM_R_dTPMS_Malfunc "TPMS malfunction";
CM_ SG_ 1242 BCM_R_dTPMS_Malfunc_LostSensor "TPMS malfunction, sensor loss alarm";
CM_ SG_ 1242 BCM_R_dTPMS_LowPressure "Low tire pressure";
CM_ SG_ 1242 BCM_R_dTPMS_RapidLeak "Quick leak alarm";
CM_ SG_ 1242 BCM_R_dTPMS_HighTemperature "High tire temperature";
CM_ SG_ 1242 BCM_R_dTPMS_HighPressure "High tire pressure";
CM_ SG_ 1242 BCM_R_dTPMS_LowBattery "TPMS sensor battery low power";
CM_ SG_ 1242 BCM_R_Keyfob_Leftcar "Remote key leaving car warning";
CM_ SG_ 1242 BCM_R_IDB_Brakelight_Malfunctio "BCM detects brake light malfunction through internal data bus";
CM_ SG_ 1242 BCM_R_CVC_Brakelight_Malfunction "When BCM communicates with CVC, it is found that there is a fault with the brake light";
CM_ SG_ 1242 BCM_R_ADAS_Turnlight_Malfunction "BCM detects a malfunction in the turn signal during ADAS interaction";
CM_ SG_ 1242 BCM_R_ADAS_Highbeam_Malfunction "BCM and ADAS have discovered a malfunction in the high beam headlights";
CM_ SG_ 1242 BCM_R_ADAS_LowBeam_Malfunction "BCM and ADAS have discovered a malfunction in the low beam headlights";
CM_ SG_ 1242 BCM_R_CVC_B_Malfunction "BCM detects CVC-B fault";
CM_ SG_ 1242 BCM_R_BCM_Malfunction "Left front BCM detected internal malfunction";
CM_ SG_ 1242 BCM_R_SCM_Malfunction "BCM detects a fault in the seat control module";
CM_ SG_ 1242 BCM_R_CrashSignalDefect "Collision unlock signal error";
CM_ SG_ 1242 BCM_R_RearFog_Defect "BCM detects a fault in the left rear fog lamp or its control circuit";
CM_ SG_ 1242 BCM_R_FrontWiperDefect "Front wiper Fail";
CM_ SG_ 1242 BCM_R_FrontLeftDoorLockDefect "FrontLeftDoorLock Fail";
CM_ SG_ 1242 BCM_R_LDML_Malfunction "Front left ligth driver module Malfunction";
CM_ SG_ 1242 BCM_R_RLT_Malfunction "Tailgate ligth driver module Malfunction";
CM_ SG_ 1242 BCM_R_BCM_POWER_Malfunction "BCM detects a malfunction in its own power system";
CM_ SG_ 1242 BCM_R_IDB_AutoHazardBlinking_Mal "BCM detects a malfunction in the automatic hazard warning light flashing function through the internal data bus";
CM_ SG_ 1246 BCMRE_STAT_TurnIndicator "Turn light output  Status";
CM_ SG_ 1002 DKCU_PhoneKey_Count "Number of Digital Keys connected";
CM_ SG_ 1002 DKCU_PhoneKey_PrimaryUser_ID "Primary User ID";
CM_ SG_ 1002 DKCU_PhoneKey_PrimaryUser_Locati "Digital Key Location status";
CM_ SG_ 1002 DKCU_PhoneKey_PrimaryUser_Motion "Device is in motion or not";
CM_ SG_ 1002 DKCU_PhoneKey_PrimaryUser_Age_10 "Elapsed Time (10ms cycle) Since Last Location Update";
CM_ SG_ 1002 DKCU_PhoneKey_PrimaryUser_RSSI "Bluetooth Signal Stength for the device connected. Raw 0 -> −90 dBm Raw 45 -> −45 dBm Raw 60 -> −30 dBm";
CM_ SG_ 1002 DKCU_PhoneKey_PrimaryUser_ConfLv "Confidence Level (Signal quality) of UWB ranginging";
CM_ SG_ 1002 DKCU_UWB_Ranging_PrimaryUser_Dis "Digital Key UWB Ranging Distance";
CM_ SG_ 1002 DKCU_BLE_Ranging_PrimaryUser_Dis "Digital Key Bluetooth Ranging Distance";
CM_ SG_ 1002 DKCU_CVC_PrimaryUser_DevicePolic "PhoneKey Access Policy for Primary user";
CM_ SG_ 1002 DKCU_PhoneKey_Guest1_ID "Guest1 User ID";
CM_ SG_ 1002 DKCU_PhoneKey_Guest1_Location "Digital Key Location status";
CM_ SG_ 1002 DKCU_PhoneKey_Guest1_MotionFlag "Device is in motion or not";
CM_ SG_ 1002 DKCU_PhoneKey_Guest1_Age_10ms "Elapsed Time (10ms cycle) Since Last Location Update";
CM_ SG_ 1002 DKCU_PhoneKey_Guest1_RSSI "Bluetooth Signal Stength for the device connected. Raw 0 -> −90 dBm Raw 45 -> −45 dBm Raw 60 -> −30 dBm";
CM_ SG_ 1002 DKCU_PhoneKey_Guest1_ConfLvl "Confidence Level (Signal quality) of UWB ranginging";
CM_ SG_ 1002 DKCU_UWB_Ranging_Guest1_Distance "Digital Key UWB Ranging Distance";
CM_ SG_ 1002 DKCU_BLE_Ranging_Guest1_Distance "Digital Key Bluetooth Ranging Distance";
CM_ SG_ 1002 DKCU_CVC_Guest1_DevicePolicy "PhoneKey Access Policy for Primary user";
CM_ SG_ 1002 DKCU_PhoneKey_Guest2_ID "Guest2 User ID";
CM_ SG_ 1002 DKCU_PhoneKey_Guest2_Location "Digital Key Location status";
CM_ SG_ 1002 DKCU_PhoneKey_Guest2_MotionFlag "Device is in motion or not";
CM_ SG_ 1002 DKCU_PhoneKey_Guest2_Age_10ms "Elapsed Time (10ms cycle) Since Last Location Update";
CM_ SG_ 1002 DKCU_PhoneKey_Guest2_RSSI "Bluetooth Signal Stength for the device connected. Raw 0 -> −90 dBm Raw 45 -> −45 dBm Raw 60 -> −30 dBm";
CM_ SG_ 1002 DKCU_PhoneKey_Guest2_ConfLvl "Confidence Level (Signal quality) of UWB ranginging";
CM_ SG_ 1002 DKCU_UWB_Ranging_Guest2_Distance "Digital Key UWB Ranging Distance";
CM_ SG_ 1002 DKCU_BLE_Ranging_Guest2_Distance "Digital Key Bluetooth Ranging Distance";
CM_ SG_ 1002 DKCU_CVC_Guest2_DevicePolicy "PhoneKey Access Policy for Primary user";
CM_ SG_ 1002 DKCU_PhoneKey_Guest3_ID "Guest3 User ID";
CM_ SG_ 1002 DKCU_PhoneKey_Guest3_Location "Digital Key Location status";
CM_ SG_ 1002 DKCU_PhoneKey_Guest3_MotionFlag "Device is in motion or not";
CM_ SG_ 1002 DKCU_PhoneKey_Guest3_Age_10ms "Elapsed Time (10ms cycle) Since Last Location Update";
CM_ SG_ 1002 DKCU_PhoneKey_Guest3_RSSI "Bluetooth Signal Stength for the device connected. Raw 0 -> −90 dBm Raw 45 -> −45 dBm Raw 60 -> −30 dBm";
CM_ SG_ 1002 DKCU_PhoneKey_Guest3_ConfLvl "Confidence Level (Signal quality) of UWB ranginging";
CM_ SG_ 1002 DKCU_UWB_Ranging_Guest3_Distance "Digital Key UWB Ranging Distance";
CM_ SG_ 1002 DKCU_BLE_Ranging_Guest3_Distance "Digital Key Bluetooth Ranging Distance";
CM_ SG_ 1002 DKCU_CVC_Guest3_DevicePolicy "PhoneKey Access Policy for Primary user";
CM_ SG_ 1003 DKCU_CVC_Welcome_Req "Welcome request";
CM_ SG_ 1005 DKCU_CVC_NFC_Presence "NFC object indication";
CM_ SG_ 1005 DKCU_CVC_NFC_Type "NFC device type";
CM_ SG_ 1005 DKCU_CVC_NFC_Validity "NFC valid confirmation";
CM_ SG_ 1005 DKCU_CVC_NFC_DeviceID "Device ID";
CM_ SG_ 1005 DKCU_CVC_NFC_Fault "Fault Indication";
CM_ SG_ 1005 DKCU_CVC_NFC_Event "NFC Event type and reader confirmation";
CM_ SG_ 1006 DKCU_DigitalKeyShareUpdate "Digital key sharing update status";
CM_ SG_ 1006 DKCU_Shared_Key_Active "Shared key activation status";
CM_ SG_ 1010 DKCU_BLE_RSSI_Front_dBm "Bluetooth (BLE) Forward Received Signal Strength Indicator";
CM_ SG_ 1010 DKCU_BLE_RSSI_Right_dBm "Bluetooth (BLE) right side received signal strength indicator";
CM_ SG_ 1010 DKCU_BLE_RSSI_Left_dBm "Bluetooth (BLE) Left side Received Signal Strength Indicator";
CM_ SG_ 1010 DKCU_BLE_RSSI_Rear_dBm "Bluetooth (BLE) backward received signal strength indication";
CM_ SG_ 1010 DKCU_BLE_RSSI_MasterECU_dBm "Bluetooth (BLE) main controller receives signal strength indication";
CM_ SG_ 1010 DKCU_UWB_ConfLvl_Front_dBm "Ultra Wideband (UWB) Forward Confidence Level";
CM_ SG_ 1010 DKCU_UWB_ConfLvl_Right_dBm "Ultra Wideband (UWB) Right Confidence Level";
CM_ SG_ 1010 DKCU_UWB_ConfLvl_Left_dBm "Ultra Wideband (UWB) Left Confidence Level";
CM_ SG_ 1010 DKCU_UWB_ConfLvl_Rear_dBm "Ultra Wideband (UWB) Backward Confidence Level";
CM_ SG_ 1010 DKCU_UWB_ConfLvl_MasterECU_dBm "Confidence Level of Ultra Wideband (UWB) Main Controller";
CM_ SG_ 1010 DKCU_UWB_ConfLvl_CPD_dBm "CPD Confidence Level of Ultra Wideband (UWB)";
CM_ SG_ 1012 DKAnchor_ExtNFCStatus_A7 "Exterior NFC Reader Fault";
CM_ SG_ 1012 DKAnchor_IntNFCStatus_A8 "Interior NFC Reader Fault";
CM_ SG_ 1012 DK_PhoneKeyPanicAlarmAlert "User requested PanicAlarm via C-App";
CM_ SG_ 1012 DK_PhoneKeyBattLowAlert "PhoneKey battery level lower than 20%";
CM_ SG_ 1012 DK_PhoneKeyIdleStsAlert "PhoneKey Idle  for n minutes (PHONEKEYIDLETIMEOUT)";
CM_ SG_ 1012 DK_VehicleIdleStsAlert "Vehicle idle for n days (TUNABLE_VEHICLE_IDLE_TIMEOUT )";
CM_ SG_ 1012 DK_BleOnOffStsAlert "Bluetooth On/Off status";
CM_ SG_ 1012 DK_LeftCarAlert "Alert when key left car";
CM_ SG_ 1012 DK_AuthFailAlert "Alert when Digital Key authentication fails";
CM_ SG_ 1012 DK_PhoneKeyForgotInsideAlert "Alert whenwhen fogot inside and attempting to lock";
CM_ SG_ 1012 DK_PhoneKeyApproachUnlockAlert "Alert when approach unklock successful/unsucessful";
CM_ SG_ 1012 DK_PhoneKeyCapabilityAlert "Alert when BLE only device detected";
CM_ SG_ 1012 DK_PhoneKeyNfcExteriorAuthFailAl "Alert when NFC Exterior reader auth fails";
CM_ SG_ 1012 DK_PhoneKeyNfcInteriorAuthFailAl "Alert when NFC Exterior reader auth fails";
CM_ SG_ 1012 DK_PhoneKeyTrunkClosingAlert "Alert when Tailgate is closing";
CM_ SG_ 1012 DK_PhoneKeyWalkawayLockFailAlert "Alert when Walkaway Lock fails.";
CM_ SG_ 1012 DK_PhoneKeyRemoteBLECmdFailAlert "Alert when Bluetooth Remote Command fails.";
CM_ SG_ 1013 CPD_Child_presence_Status "CPD Child presence Status";
CM_ SG_ 1014 Vehicle_Idle_Time "vehicle idle status";
CM_ SG_ 1014 PhoneKey_Idle_Time "PhoneKey idle status";
CM_ SG_ 1014 PhoneKey_BatteryLvl_Status "PhoneKey battery status";
CM_ SG_ 1016 DKCU_Temp_Inv_Req "DKCU Temp Intervention Req";
CM_ SG_ 1016 DKCU_Remote_Phone_Inv_Req "DKCU Remote Phone Intervention Req";
CM_ SG_ 1018 DKCU_CVC_Footkick_Sts "DKCU detects Foot Kick gesture and confirms CVC";
CM_ SG_ 1281 BCM_FL_srcNodeID "Network Management Signal";
CM_ SG_ 1281 BCM_FL_CtrlBitVector "Network Management Signal";
CM_ SG_ 1281 BCM_FL_usrData0 "Network Management Signal";
CM_ SG_ 1281 BCM_FL_usrData1 "Network Management Signal";
CM_ SG_ 1281 BCM_FL_usrData2 "Network Management Signal";
CM_ SG_ 1281 BCM_FL_usrData3 "Network Management Signal";
CM_ SG_ 1281 BCM_FL_usrData4 "Network Management Signal";
CM_ SG_ 1281 BCM_FL_usrData5 "Network Management Signal";
CM_ SG_ 1282 CVC_srcNodeID "Network Management Signal";
CM_ SG_ 1282 CVC_CtrlBitVector "Network Management Signal";
CM_ SG_ 1282 CVC_usrData0 "Network Management Signal";
CM_ SG_ 1282 CVC_usrData1 "Network Management Signal";
CM_ SG_ 1282 CVC_usrData2 "Network Management Signal";
CM_ SG_ 1282 CVC_usrData3 "Network Management Signal";
CM_ SG_ 1282 CVC_usrData4 "Network Management Signal";
CM_ SG_ 1282 CVC_usrData5 "Network Management Signal";
CM_ SG_ 1286 BCM_FR_srcNodeID "Network Management Signal";
CM_ SG_ 1286 BCM_FR_CtrlBitVector "Network Management Signal";
CM_ SG_ 1286 BCM_FR_usrData0 "Network Management Signal";
CM_ SG_ 1286 BCM_FR_usrData1 "Network Management Signal";
CM_ SG_ 1286 BCM_FR_usrData2 "Network Management Signal";
CM_ SG_ 1286 BCM_FR_usrData3 "Network Management Signal";
CM_ SG_ 1286 BCM_FR_usrData4 "Network Management Signal";
CM_ SG_ 1286 BCM_FR_usrData5 "Network Management Signal";
CM_ SG_ 1287 BCM_R_srcNodeID "Network Management Signal";
CM_ SG_ 1287 BCM_R_CtrlBitVector "Network Management Signal";
CM_ SG_ 1287 BCM_R_usrData0 "Network Management Signal";
CM_ SG_ 1287 BCM_R_usrData1 "Network Management Signal";
CM_ SG_ 1287 BCM_R_usrData2 "Network Management Signal";
CM_ SG_ 1287 BCM_R_usrData3 "Network Management Signal";
CM_ SG_ 1287 BCM_R_usrData4 "Network Management Signal";
CM_ SG_ 1287 BCM_R_usrData5 "Network Management Signal";
CM_ SG_ 1356 DKCU_srcNodeID "Network Management Signal";
CM_ SG_ 1356 DKCU_CtrlBitVector "Network Management Signal";
CM_ SG_ 1356 DKCU_usrData0 "Network Management Signal";
CM_ SG_ 1356 DKCU_usrData1 "Network Management Signal";
CM_ SG_ 1356 DKCU_usrData2 "Network Management Signal";
CM_ SG_ 1356 DKCU_usrData3 "Network Management Signal";
CM_ SG_ 1356 DKCU_usrData4 "Network Management Signal";
CM_ SG_ 1356 DKCU_usrData5 "Network Management Signal";
CM_ SG_ 1537 BCM_FL_DiagRespData0 "Diagnostic signal Data response";
CM_ SG_ 1537 BCM_FL_DiagRespData1 "Remote Diagnostic signal Data response";
CM_ SG_ 1537 BCM_FL_DiagRespData2 "Diagnostic signal Data response";
CM_ SG_ 1537 BCM_FL_DiagRespData3 "Diagnostic signal Data response";
CM_ SG_ 1537 BCM_FL_DiagRespData4 "Diagnostic signal Data response";
CM_ SG_ 1537 BCM_FL_DiagRespData5 "Diagnostic signal Data response";
CM_ SG_ 1537 BCM_FL_DiagRespData6 "Remote Diagnostic signal Data response";
CM_ SG_ 1537 BCM_FL_DiagRespData7 "Diagnostic signal Data response";
CM_ SG_ 1665 BCM_FL_DiagReqData0 "Diagnostic signal Data request";
CM_ SG_ 1665 BCM_FL_DiagReqData1 "Diagnostic signal Data request";
CM_ SG_ 1665 BCM_FL_DiagReqData2 "Diagnostic signal Data request";
CM_ SG_ 1665 BCM_FL_DiagReqData3 "Diagnostic signal Data request";
CM_ SG_ 1665 BCM_FL_DiagReqData4 "Diagnostic signal Data request";
CM_ SG_ 1665 BCM_FL_DiagReqData5 "Diagnostic signal Data request";
CM_ SG_ 1665 BCM_FL_DiagReqData6 "Remote Diagnostic signal Data request";
CM_ SG_ 1665 BCM_FL_DiagReqData7 "Remote Diagnostic signal Data request";
CM_ SG_ 1542 BCM_FR_DiagRespData0 "Diagnostic signal Data response";
CM_ SG_ 1542 BCM_FR_DiagRespData1 "Remote Diagnostic signal Data response";
CM_ SG_ 1542 BCM_FR_DiagRespData2 "Diagnostic signal Data response";
CM_ SG_ 1542 BCM_FR_DiagRespData3 "Diagnostic signal Data response";
CM_ SG_ 1542 BCM_FR_DiagRespData4 "Diagnostic signal Data response";
CM_ SG_ 1542 BCM_FR_DiagRespData5 "Diagnostic signal Data response";
CM_ SG_ 1542 BCM_FR_DiagRespData6 "Remote Diagnostic signal Data response";
CM_ SG_ 1542 BCM_FR_DiagRespData7 "Diagnostic signal Data response";
CM_ SG_ 1670 BCM_FR_DiagReqData0 "Diagnostic signal Data request";
CM_ SG_ 1670 BCM_FR_DiagReqData1 "Diagnostic signal Data request";
CM_ SG_ 1670 BCM_FR_DiagReqData2 "Diagnostic signal Data request";
CM_ SG_ 1670 BCM_FR_DiagReqData3 "Diagnostic signal Data request";
CM_ SG_ 1670 BCM_FR_DiagReqData4 "Diagnostic signal Data request";
CM_ SG_ 1670 BCM_FR_DiagReqData5 "Diagnostic signal Data request";
CM_ SG_ 1670 BCM_FR_DiagReqData6 "Remote Diagnostic signal Data request";
CM_ SG_ 1670 BCM_FR_DiagReqData7 "Remote Diagnostic signal Data request";
CM_ SG_ 1543 BCM_R_DiagRespData0 "Diagnostic signal Data response";
CM_ SG_ 1543 BCM_R_DiagRespData1 "Remote Diagnostic signal Data response";
CM_ SG_ 1543 BCM_R_DiagRespData2 "Diagnostic signal Data response";
CM_ SG_ 1543 BCM_R_DiagRespData3 "Diagnostic signal Data response";
CM_ SG_ 1543 BCM_R_DiagRespData4 "Diagnostic signal Data response";
CM_ SG_ 1543 BCM_R_DiagRespData5 "Diagnostic signal Data response";
CM_ SG_ 1543 BCM_R_DiagRespData6 "Remote Diagnostic signal Data response";
CM_ SG_ 1543 BCM_R_DiagRespData7 "Diagnostic signal Data response";
CM_ SG_ 1671 BCM_R_DiagReqData0 "Diagnostic signal Data request";
CM_ SG_ 1671 BCM_R_DiagReqData1 "Diagnostic signal Data request";
CM_ SG_ 1671 BCM_R_DiagReqData2 "Diagnostic signal Data request";
CM_ SG_ 1671 BCM_R_DiagReqData3 "Diagnostic signal Data request";
CM_ SG_ 1671 BCM_R_DiagReqData4 "Diagnostic signal Data request";
CM_ SG_ 1671 BCM_R_DiagReqData5 "Diagnostic signal Data request";
CM_ SG_ 1671 BCM_R_DiagReqData6 "Diagnostic signal Data request";
CM_ SG_ 1671 BCM_R_DiagReqData7 "Diagnostic signal Data request";
CM_ SG_ 1671 BCM_R_DiagReqData8 "Diagnostic signal Data request";
CM_ SG_ 1671 BCM_R_DiagReqData9 "Diagnostic signal Data request";
CM_ SG_ 1671 BCM_R_DiagReqData10 "Diagnostic signal Data request";
CM_ SG_ 1671 BCM_R_DiagReqData11 "Diagnostic signal Data request";
CM_ SG_ 1671 BCM_R_DiagReqData12 "Diagnostic signal Data request";
CM_ SG_ 1671 BCM_R_DiagReqData13 "Diagnostic signal Data request";
CM_ SG_ 1671 BCM_R_DiagReqData14 "Diagnostic signal Data request";
CM_ SG_ 1671 BCM_R_DiagReqData15 "Diagnostic signal Data request";
CM_ SG_ 1671 BCM_R_DiagReqData16 "Diagnostic signal Data request";
CM_ SG_ 1671 BCM_R_DiagReqData17 "Diagnostic signal Data request";
CM_ SG_ 1671 BCM_R_DiagReqData18 "Diagnostic signal Data request";
CM_ SG_ 1671 BCM_R_DiagReqData19 "Diagnostic signal Data request";
CM_ SG_ 1671 BCM_R_DiagReqData20 "Diagnostic signal Data request";
CM_ SG_ 1671 BCM_R_DiagReqData21 "Diagnostic signal Data request";
CM_ SG_ 1671 BCM_R_DiagReqData22 "Diagnostic signal Data request";
CM_ SG_ 1671 BCM_R_DiagReqData23 "Diagnostic signal Data request";
CM_ SG_ 1671 BCM_R_DiagReqData24 "Diagnostic signal Data request";
CM_ SG_ 1671 BCM_R_DiagReqData25 "Diagnostic signal Data request";
CM_ SG_ 1671 BCM_R_DiagReqData26 "Diagnostic signal Data request";
CM_ SG_ 1671 BCM_R_DiagReqData27 "Diagnostic signal Data request";
CM_ SG_ 1671 BCM_R_DiagReqData28 "Diagnostic signal Data request";
CM_ SG_ 1671 BCM_R_DiagReqData29 "Diagnostic signal Data request";
CM_ SG_ 1671 BCM_R_DiagReqData30 "Diagnostic signal Data request";
CM_ SG_ 1671 BCM_R_DiagReqData31 "Diagnostic signal Data request";
CM_ SG_ 1671 BCM_R_DiagReqData32 "Diagnostic signal Data request";
CM_ SG_ 1671 BCM_R_DiagReqData33 "Diagnostic signal Data request";
CM_ SG_ 1671 BCM_R_DiagReqData34 "Diagnostic signal Data request";
CM_ SG_ 1671 BCM_R_DiagReqData35 "Diagnostic signal Data request";
CM_ SG_ 1671 BCM_R_DiagReqData36 "Diagnostic signal Data request";
CM_ SG_ 1671 BCM_R_DiagReqData37 "Diagnostic signal Data request";
CM_ SG_ 1671 BCM_R_DiagReqData38 "Diagnostic signal Data request";
CM_ SG_ 1671 BCM_R_DiagReqData39 "Diagnostic signal Data request";
CM_ SG_ 1671 BCM_R_DiagReqData40 "Diagnostic signal Data request";
CM_ SG_ 1671 BCM_R_DiagReqData41 "Diagnostic signal Data request";
CM_ SG_ 1671 BCM_R_DiagReqData42 "Diagnostic signal Data request";
CM_ SG_ 1671 BCM_R_DiagReqData43 "Diagnostic signal Data request";
CM_ SG_ 1671 BCM_R_DiagReqData44 "Diagnostic signal Data request";
CM_ SG_ 1671 BCM_R_DiagReqData45 "Diagnostic signal Data request";
CM_ SG_ 1671 BCM_R_DiagReqData46 "Diagnostic signal Data request";
CM_ SG_ 1671 BCM_R_DiagReqData47 "Diagnostic signal Data request";
CM_ SG_ 1671 BCM_R_DiagReqData48 "Diagnostic signal Data request";
CM_ SG_ 1671 BCM_R_DiagReqData49 "Diagnostic signal Data request";
CM_ SG_ 1671 BCM_R_DiagReqData50 "Diagnostic signal Data request";
CM_ SG_ 1671 BCM_R_DiagReqData51 "Diagnostic signal Data request";
CM_ SG_ 1671 BCM_R_DiagReqData52 "Diagnostic signal Data request";
CM_ SG_ 1671 BCM_R_DiagReqData53 "Diagnostic signal Data request";
CM_ SG_ 1671 BCM_R_DiagReqData54 "Diagnostic signal Data request";
CM_ SG_ 1671 BCM_R_DiagReqData55 "Diagnostic signal Data request";
CM_ SG_ 1671 BCM_R_DiagReqData56 "Diagnostic signal Data request";
CM_ SG_ 1671 BCM_R_DiagReqData57 "Diagnostic signal Data request";
CM_ SG_ 1671 BCM_R_DiagReqData58 "Diagnostic signal Data request";
CM_ SG_ 1671 BCM_R_DiagReqData59 "Diagnostic signal Data request";
CM_ SG_ 1671 BCM_R_DiagReqData60 "Diagnostic signal Data request";
CM_ SG_ 1671 BCM_R_DiagReqData61 "Diagnostic signal Data request";
CM_ SG_ 1671 BCM_R_DiagReqData62 "Diagnostic signal Data request";
CM_ SG_ 1671 BCM_R_DiagReqData63 "Diagnostic signal Data request";
CM_ SG_ 1612 DKCU_DiagRespData0 "Diagnostic signal Data response";
CM_ SG_ 1612 DKCU_DiagRespData1 "Remote Diagnostic signal Data response";
CM_ SG_ 1612 DKCU_DiagRespData2 "Diagnostic signal Data response";
CM_ SG_ 1612 DKCU_DiagRespData3 "Diagnostic signal Data response";
CM_ SG_ 1612 DKCU_DiagRespData4 "Diagnostic signal Data response";
CM_ SG_ 1612 DKCU_DiagRespData5 "Diagnostic signal Data response";
CM_ SG_ 1612 DKCU_DiagRespData6 "Remote Diagnostic signal Data response";
CM_ SG_ 1612 DKCU_DiagRespData7 "Diagnostic signal Data response";
CM_ SG_ 1740 DKCU_DiagReqData0 "Diagnostic signal Data request";
CM_ SG_ 1740 DKCU_DiagReqData1 "Diagnostic signal Data request";
CM_ SG_ 1740 DKCU_DiagReqData2 "Diagnostic signal Data request";
CM_ SG_ 1740 DKCU_DiagReqData3 "Diagnostic signal Data request";
CM_ SG_ 1740 DKCU_DiagReqData4 "Diagnostic signal Data request";
CM_ SG_ 1740 DKCU_DiagReqData5 "Diagnostic signal Data request";
CM_ SG_ 1740 DKCU_DiagReqData6 "Diagnostic signal Data request";
CM_ SG_ 1740 DKCU_DiagReqData7 "Diagnostic signal Data request";
CM_ SG_ 1740 DKCU_DiagReqData8 "Diagnostic signal Data request";
CM_ SG_ 1740 DKCU_DiagReqData9 "Diagnostic signal Data request";
CM_ SG_ 1740 DKCU_DiagReqData10 "Diagnostic signal Data request";
CM_ SG_ 1740 DKCU_DiagReqData11 "Diagnostic signal Data request";
CM_ SG_ 1740 DKCU_DiagReqData12 "Diagnostic signal Data request";
CM_ SG_ 1740 DKCU_DiagReqData13 "Diagnostic signal Data request";
CM_ SG_ 1740 DKCU_DiagReqData14 "Diagnostic signal Data request";
CM_ SG_ 1740 DKCU_DiagReqData15 "Diagnostic signal Data request";
CM_ SG_ 1740 DKCU_DiagReqData16 "Diagnostic signal Data request";
CM_ SG_ 1740 DKCU_DiagReqData17 "Diagnostic signal Data request";
CM_ SG_ 1740 DKCU_DiagReqData18 "Diagnostic signal Data request";
CM_ SG_ 1740 DKCU_DiagReqData19 "Diagnostic signal Data request";
CM_ SG_ 1740 DKCU_DiagReqData20 "Diagnostic signal Data request";
CM_ SG_ 1740 DKCU_DiagReqData21 "Diagnostic signal Data request";
CM_ SG_ 1740 DKCU_DiagReqData22 "Diagnostic signal Data request";
CM_ SG_ 1740 DKCU_DiagReqData23 "Diagnostic signal Data request";
CM_ SG_ 1740 DKCU_DiagReqData24 "Diagnostic signal Data request";
CM_ SG_ 1740 DKCU_DiagReqData25 "Diagnostic signal Data request";
CM_ SG_ 1740 DKCU_DiagReqData26 "Diagnostic signal Data request";
CM_ SG_ 1740 DKCU_DiagReqData27 "Diagnostic signal Data request";
CM_ SG_ 1740 DKCU_DiagReqData28 "Diagnostic signal Data request";
CM_ SG_ 1740 DKCU_DiagReqData29 "Diagnostic signal Data request";
CM_ SG_ 1740 DKCU_DiagReqData30 "Diagnostic signal Data request";
CM_ SG_ 1740 DKCU_DiagReqData31 "Diagnostic signal Data request";
CM_ SG_ 1740 DKCU_DiagReqData32 "Diagnostic signal Data request";
CM_ SG_ 1740 DKCU_DiagReqData33 "Diagnostic signal Data request";
CM_ SG_ 1740 DKCU_DiagReqData34 "Diagnostic signal Data request";
CM_ SG_ 1740 DKCU_DiagReqData35 "Diagnostic signal Data request";
CM_ SG_ 1740 DKCU_DiagReqData36 "Diagnostic signal Data request";
CM_ SG_ 1740 DKCU_DiagReqData37 "Diagnostic signal Data request";
CM_ SG_ 1740 DKCU_DiagReqData38 "Diagnostic signal Data request";
CM_ SG_ 1740 DKCU_DiagReqData39 "Diagnostic signal Data request";
CM_ SG_ 1740 DKCU_DiagReqData40 "Diagnostic signal Data request";
CM_ SG_ 1740 DKCU_DiagReqData41 "Diagnostic signal Data request";
CM_ SG_ 1740 DKCU_DiagReqData42 "Diagnostic signal Data request";
CM_ SG_ 1740 DKCU_DiagReqData43 "Diagnostic signal Data request";
CM_ SG_ 1740 DKCU_DiagReqData44 "Diagnostic signal Data request";
CM_ SG_ 1740 DKCU_DiagReqData45 "Diagnostic signal Data request";
CM_ SG_ 1740 DKCU_DiagReqData46 "Diagnostic signal Data request";
CM_ SG_ 1740 DKCU_DiagReqData47 "Diagnostic signal Data request";
CM_ SG_ 1740 DKCU_DiagReqData48 "Diagnostic signal Data request";
CM_ SG_ 1740 DKCU_DiagReqData49 "Diagnostic signal Data request";
CM_ SG_ 1740 DKCU_DiagReqData50 "Diagnostic signal Data request";
CM_ SG_ 1740 DKCU_DiagReqData51 "Diagnostic signal Data request";
CM_ SG_ 1740 DKCU_DiagReqData52 "Diagnostic signal Data request";
CM_ SG_ 1740 DKCU_DiagReqData53 "Diagnostic signal Data request";
CM_ SG_ 1740 DKCU_DiagReqData54 "Diagnostic signal Data request";
CM_ SG_ 1740 DKCU_DiagReqData55 "Diagnostic signal Data request";
CM_ SG_ 1740 DKCU_DiagReqData56 "Diagnostic signal Data request";
CM_ SG_ 1740 DKCU_DiagReqData57 "Diagnostic signal Data request";
CM_ SG_ 1740 DKCU_DiagReqData58 "Diagnostic signal Data request";
CM_ SG_ 1740 DKCU_DiagReqData59 "Diagnostic signal Data request";
CM_ SG_ 1740 DKCU_DiagReqData60 "Diagnostic signal Data request";
CM_ SG_ 1740 DKCU_DiagReqData61 "Diagnostic signal Data request";
CM_ SG_ 1740 DKCU_DiagReqData62 "Diagnostic signal Data request";
CM_ SG_ 1740 DKCU_DiagReqData63 "Diagnostic signal Data request";
CM_ SG_ 1791 OBD_Func_DiagReqData0 "Diagnostic message all ECUs";
CM_ SG_ 1791 OBD_Func_DiagReqData1 "Diagnostic message all ECUs";
CM_ SG_ 1791 OBD_Func_DiagReqData2 "Diagnostic message all ECUs";
CM_ SG_ 1791 OBD_Func_DiagReqData3 "Diagnostic message all ECUs";
CM_ SG_ 1791 OBD_Func_DiagReqData4 "Diagnostic message all ECUs";
CM_ SG_ 1791 OBD_Func_DiagReqData5 "Diagnostic message all ECUs";
CM_ SG_ 1791 OBD_Func_DiagReqData6 "Diagnostic message all ECUs";
CM_ SG_ 1791 OBD_Func_DiagReqData7 "Diagnostic message all ECUs";
BA_DEF_ BO_  "DiagRequest" ENUM  "No","Yes";
BA_DEF_ BO_  "DiagResponse" ENUM  "No","Yes";
BA_DEF_ BO_  "DiagState" ENUM  "No","Yes";
BA_DEF_ BO_  "GenMsgCycleTime" INT 0 65535;
BA_DEF_ BO_  "GenMsgCycleTimeFast" INT 0 65535;
BA_DEF_ BO_  "GenMsgDelayTime" INT 0 65535;
BA_DEF_ BO_  "GenMsgILSupport" ENUM  "No","Yes";
BA_DEF_ BO_  "GenMsgNrOfRepetition" INT 0 65535;
BA_DEF_ BO_  "GenMsgSendType" ENUM  "Cyclic","NoMsgSendType","NotUsed","NotUsed","NotUsed","NotUsed","NotUsed","IfActive","NoMsgSendType","NotUsed";
BA_DEF_ BO_  "NmAsrMessage" ENUM  "No","Yes";
BA_DEF_ BO_  "NmMessage" ENUM  "No","Yes";
BA_DEF_ SG_  "GenSigSendType" ENUM  "Cyclic","NoSigSendType","OnWriteWithRepetition","OnChange","OnChangeWithRepetition","IfActive","IfActiveWithRepetition","OnWrite","NotUsed","NotUsed","NotUsed","NotUsed","NotUsed";
BA_DEF_ SG_  "GenSigStartValue" INT 0 2147483647;
BA_DEF_ SG_  "GenSigTimeoutTime_ALL" INT 0 65535;
BA_DEF_ SG_  "InvalidValue" STRING ;
BA_DEF_ SG_  "GenSigInactiveValue" INT 0 2147483647;
BA_DEF_ BO_  "VFrameFormat" ENUM  "StandardCAN","ExtendedCAN","reserved","J1939PG","reserved","reserved","reserved","reserved","reserved","reserved","reserved","reserved","reserved","reserved","StandardCAN_FD","ExtendedCAN_FD";
BA_DEF_ BO_  "CANFD_BRS" ENUM  "0","1";
BA_DEF_ SG_  "SystemSignalLongSymbol" STRING ;
BA_DEF_DEF_  "DiagRequest" "No";
BA_DEF_DEF_  "DiagResponse" "No";
BA_DEF_DEF_  "DiagState" "No";
BA_DEF_DEF_  "GenMsgCycleTime" 0;
BA_DEF_DEF_  "GenMsgCycleTimeFast" 0;
BA_DEF_DEF_  "GenMsgDelayTime" 0;
BA_DEF_DEF_  "GenMsgILSupport" "Yes";
BA_DEF_DEF_  "GenMsgNrOfRepetition" 0;
BA_DEF_DEF_  "GenMsgSendType" "Cyclic";
BA_DEF_DEF_  "NmAsrMessage" "No";
BA_DEF_DEF_  "NmMessage" "No";
BA_DEF_DEF_  "GenSigSendType" "Cyclic";
BA_DEF_DEF_  "GenSigStartValue" 0;
BA_DEF_DEF_  "GenSigTimeoutTime_ALL" 0;
BA_DEF_DEF_  "InvalidValue" "";
BA_DEF_DEF_  "GenSigInactiveValue" 0;
BA_DEF_DEF_  "VFrameFormat" "StandardCAN_FD";
BA_DEF_DEF_  "CANFD_BRS" "1";
BA_DEF_DEF_  "SystemSignalLongSymbol" "";
BA_ "GenMsgCycleTime" BO_ 189 100;
BA_ "GenMsgCycleTime" BO_ 206 100;
BA_ "GenMsgCycleTime" BO_ 253 100;
BA_ "GenMsgCycleTime" BO_ 275 100;
BA_ "GenMsgCycleTime" BO_ 289 100;
BA_ "GenMsgCycleTime" BO_ 325 100;
BA_ "GenMsgCycleTime" BO_ 522 100;
BA_ "GenMsgCycleTime" BO_ 523 100;
BA_ "GenMsgCycleTimeFast" BO_ 523 30;
BA_ "GenMsgNrOfRepetition" BO_ 523 3;
BA_ "GenMsgCycleTime" BO_ 535 100;
BA_ "GenMsgCycleTime" BO_ 540 100;
BA_ "GenMsgCycleTimeFast" BO_ 784 20;
BA_ "GenMsgNrOfRepetition" BO_ 784 2;
BA_ "GenMsgSendType" BO_ 784 1;
BA_ "GenMsgCycleTimeFast" BO_ 1040 100;
BA_ "GenMsgNrOfRepetition" BO_ 1040 3;
BA_ "GenMsgSendType" BO_ 1040 1;
BA_ "GenMsgCycleTime" BO_ 1056 100;
BA_ "GenMsgCycleTimeFast" BO_ 1075 20;
BA_ "GenMsgNrOfRepetition" BO_ 1075 2;
BA_ "GenMsgSendType" BO_ 1075 1;
BA_ "GenMsgCycleTimeFast" BO_ 1097 100;
BA_ "GenMsgNrOfRepetition" BO_ 1097 3;
BA_ "GenMsgSendType" BO_ 1097 1;
BA_ "GenMsgSendType" BO_ 1170 1;
BA_ "GenMsgCycleTime" BO_ 1219 1000;
BA_ "GenMsgCycleTime" BO_ 1242 1000;
BA_ "GenMsgCycleTime" BO_ 1246 100;
BA_ "GenMsgSendType" BO_ 1861 1;
BA_ "GenMsgSendType" BO_ 924 1;
BA_ "GenMsgCycleTime" BO_ 1001 100;
BA_ "GenMsgCycleTimeFast" BO_ 1001 20;
BA_ "GenMsgNrOfRepetition" BO_ 1001 3;
BA_ "GenMsgCycleTime" BO_ 1002 100;
BA_ "GenMsgCycleTimeFast" BO_ 1002 20;
BA_ "GenMsgNrOfRepetition" BO_ 1002 3;
BA_ "GenMsgCycleTime" BO_ 1003 100;
BA_ "GenMsgCycleTime" BO_ 1005 100;
BA_ "GenMsgCycleTime" BO_ 1006 100;
BA_ "GenMsgCycleTime" BO_ 1007 100;
BA_ "GenMsgCycleTime" BO_ 1008 100;
BA_ "GenMsgCycleTime" BO_ 1010 100;
BA_ "GenMsgCycleTime" BO_ 1012 100;
BA_ "GenMsgCycleTime" BO_ 1013 100;
BA_ "GenMsgCycleTime" BO_ 1014 100;
BA_ "GenMsgCycleTime" BO_ 1016 100;
BA_ "GenMsgCycleTime" BO_ 1018 200;
BA_ "GenMsgCycleTimeFast" BO_ 1018 20;
BA_ "GenMsgNrOfRepetition" BO_ 1018 3;
BA_ "GenMsgCycleTimeFast" BO_ 1974 50;
BA_ "GenMsgNrOfRepetition" BO_ 1974 2;
BA_ "GenMsgSendType" BO_ 1974 1;
BA_ "NmMessage" BO_ 1281 1;
BA_ "NmAsrMessage" BO_ 1281 1;
BA_ "VFrameFormat" BO_ 1281 0;
BA_ "GenMsgCycleTime" BO_ 1281 640;
BA_ "GenMsgILSupport" BO_ 1281 0;
BA_ "NmMessage" BO_ 1282 1;
BA_ "NmAsrMessage" BO_ 1282 1;
BA_ "VFrameFormat" BO_ 1282 0;
BA_ "GenMsgCycleTime" BO_ 1282 640;
BA_ "GenMsgILSupport" BO_ 1282 0;
BA_ "NmMessage" BO_ 1286 1;
BA_ "NmAsrMessage" BO_ 1286 1;
BA_ "VFrameFormat" BO_ 1286 0;
BA_ "GenMsgCycleTime" BO_ 1286 640;
BA_ "GenMsgILSupport" BO_ 1286 0;
BA_ "NmMessage" BO_ 1287 1;
BA_ "NmAsrMessage" BO_ 1287 1;
BA_ "VFrameFormat" BO_ 1287 0;
BA_ "GenMsgCycleTime" BO_ 1287 640;
BA_ "GenMsgILSupport" BO_ 1287 0;
BA_ "NmMessage" BO_ 1356 1;
BA_ "NmAsrMessage" BO_ 1356 1;
BA_ "VFrameFormat" BO_ 1356 0;
BA_ "GenMsgCycleTime" BO_ 1356 640;
BA_ "GenMsgILSupport" BO_ 1356 0;
BA_ "GenMsgILSupport" BO_ 1537 0;
BA_ "DiagState" BO_ 1537 1;
BA_ "DiagResponse" BO_ 1537 1;
BA_ "GenMsgSendType" BO_ 1537 1;
BA_ "GenMsgILSupport" BO_ 1665 0;
BA_ "DiagState" BO_ 1665 1;
BA_ "DiagRequest" BO_ 1665 1;
BA_ "GenMsgSendType" BO_ 1665 1;
BA_ "GenMsgILSupport" BO_ 1542 0;
BA_ "DiagState" BO_ 1542 1;
BA_ "DiagResponse" BO_ 1542 1;
BA_ "GenMsgSendType" BO_ 1542 1;
BA_ "GenMsgILSupport" BO_ 1670 0;
BA_ "DiagState" BO_ 1670 1;
BA_ "DiagRequest" BO_ 1670 1;
BA_ "GenMsgSendType" BO_ 1670 1;
BA_ "GenMsgILSupport" BO_ 1543 0;
BA_ "DiagState" BO_ 1543 1;
BA_ "DiagResponse" BO_ 1543 1;
BA_ "GenMsgSendType" BO_ 1543 1;
BA_ "GenMsgILSupport" BO_ 1671 0;
BA_ "DiagState" BO_ 1671 1;
BA_ "DiagRequest" BO_ 1671 1;
BA_ "GenMsgSendType" BO_ 1671 1;
BA_ "GenMsgILSupport" BO_ 1612 0;
BA_ "DiagState" BO_ 1612 1;
BA_ "DiagResponse" BO_ 1612 1;
BA_ "GenMsgSendType" BO_ 1612 1;
BA_ "GenMsgILSupport" BO_ 1740 0;
BA_ "DiagState" BO_ 1740 1;
BA_ "DiagRequest" BO_ 1740 1;
BA_ "GenMsgSendType" BO_ 1740 1;
BA_ "GenMsgILSupport" BO_ 1791 0;
BA_ "DiagState" BO_ 1791 1;
BA_ "GenMsgSendType" BO_ 1791 1;
BA_ "GenSigStartValue" SG_ 206 BCMRE_DuctTempRearRight 300;
BA_ "GenSigStartValue" SG_ 206 BCMRE_DuctTempRearLeft 300;
BA_ "GenSigStartValue" SG_ 275 BCM_Stat_SwitchLightBrightness 80;
BA_ "GenSigStartValue" SG_ 325 BCMRE_SOV_Status 3;
BA_ "InvalidValue" SG_ 325 BCMRE_SOV2_Fault "3h";
BA_ "SystemSignalLongSymbol" SG_ 325 BCMRE_RearAPTC_IGBTTempSensorFau "BCMRE_RearAPTC_IGBTTempSensorFault";
BA_ "GenSigStartValue" SG_ 522 ETG_Lift_Gate_Status 9;
BA_ "GenSigStartValue" SG_ 522 ETG_Power_Latch_Status 7;
BA_ "GenSigStartValue" SG_ 522 ETG_Latch_Segment 3;
BA_ "GenSigStartValue" SG_ 522 ETG_AJR_Status 1;
BA_ "GenSigSendType" SG_ 535 BCM_PositionLight_RL_STS 4;
BA_ "GenSigSendType" SG_ 535 BCM_PositionLight_RR_STS 4;
BA_ "GenSigSendType" SG_ 535 BCM_TurnIndicator_RL_STS 4;
BA_ "GenSigSendType" SG_ 535 BCM_TurnIndicator_RR_STS 4;
BA_ "GenSigSendType" SG_ 535 BCM_ReverseLamp_RL_STS 4;
BA_ "GenSigSendType" SG_ 535 BCM_ReverseLamp_RR_STS 4;
BA_ "GenSigSendType" SG_ 535 BCM_BrakeLight_RL_STS 4;
BA_ "GenSigSendType" SG_ 535 BCM_BrakeLight_RR_STS 4;
BA_ "GenSigSendType" SG_ 535 BCM_RearFogLamp_RR_STS 4;
BA_ "GenSigSendType" SG_ 535 BCM_BrakeLight_Center_STS 4;
BA_ "GenSigSendType" SG_ 535 BCM_LicensePlateLamp_RE_STS 4;
BA_ "GenSigSendType" SG_ 535 BCM_RearFogLamp_RL_STS 4;
BA_ "GenSigSendType" SG_ 535 BCM_SignatureRear_STS 4;
BA_ "GenSigSendType" SG_ 535 BCMRE_WelcomeFarewellLight_STS 4;
BA_ "GenSigSendType" SG_ 535 BCM_PositionLight_RM_STS 4;
BA_ "InvalidValue" SG_ 535 BCM_ParkingLight_RL_STS "3h";
BA_ "GenSigSendType" SG_ 535 BCM_ParkingLight_RL_STS 4;
BA_ "InvalidValue" SG_ 535 BCM_ParkingLight_RM_STS "3h";
BA_ "GenSigSendType" SG_ 535 BCM_ParkingLight_RM_STS 4;
BA_ "InvalidValue" SG_ 535 BCM_ParkingLight_RR_STS "3h";
BA_ "GenSigSendType" SG_ 535 BCM_ParkingLight_RR_STS 4;
BA_ "GenSigStartValue" SG_ 540 BCM_RE_RLDoorCourtesyLightSts 2;
BA_ "GenSigSendType" SG_ 540 BCM_RE_RLDoorCourtesyLightSts 4;
BA_ "GenSigStartValue" SG_ 540 BCM_RE_RRDoorCourtesyLightSts 2;
BA_ "GenSigSendType" SG_ 540 BCM_RE_RRDoorCourtesyLightSts 4;
BA_ "GenSigSendType" SG_ 540 BCM_RE_CargoLightSts 4;
BA_ "GenSigSendType" SG_ 540 BCM_RE_Rear_3rd_DomeLampSts 4;
BA_ "GenSigSendType" SG_ 540 BCM_RLProjectorLightSts 4;
BA_ "GenSigSendType" SG_ 540 BCM_RRProjectorLightSts 4;
BA_ "GenSigSendType" SG_ 784 CCUR_STAT_IonButton 1;
BA_ "GenSigSendType" SG_ 784 CCUR_STAT_Defrost 1;
BA_ "GenSigSendType" SG_ 784 CCUR_STAT_Auto 1;
BA_ "GenSigSendType" SG_ 784 CCUR_STAT_Aircondition 1;
BA_ "GenSigSendType" SG_ 784 CCUR_STAT_FlapPos 1;
BA_ "GenSigSendType" SG_ 784 CCUR_STAT_FanSpeed 1;
BA_ "GenSigSendType" SG_ 784 CCUR_STAT_PTC_Heater 1;
BA_ "GenSigStartValue" SG_ 784 CCUR_STAT_OnOff 3;
BA_ "GenSigSendType" SG_ 784 CCUR_STAT_OnOff 1;
BA_ "GenSigSendType" SG_ 784 CCUR_STAT_MaxAc 1;
BA_ "GenSigSendType" SG_ 784 CCUR_STAT_SyncClimateZone 1;
BA_ "GenSigStartValue" SG_ 784 CCUR_STAT_RecircFlap 1;
BA_ "GenSigSendType" SG_ 784 CCUR_STAT_RecircFlap 1;
BA_ "GenSigStartValue" SG_ 784 CCUR_STAT_TempRear 40;
BA_ "GenSigSendType" SG_ 784 CCUR_STAT_TempRear 1;
BA_ "GenSigSendType" SG_ 1040 BCMRE_RearHeatedWindow 2;
BA_ "GenSigSendType" SG_ 1075 BCMRE_STAT_RearDefrost 4;
BA_ "GenSigSendType" SG_ 1097 CHKSM_RESP_REM_FUNC_APM 1;
BA_ "GenSigSendType" SG_ 1097 RESP_REM_ResponseID_APM 1;
BA_ "GenSigSendType" SG_ 1097 RESP_REM_DataByte0_APM 1;
BA_ "GenSigSendType" SG_ 1097 RESP_REM_DataByte1_APM 1;
BA_ "GenSigSendType" SG_ 1097 RESP_REM_DataByte2_APM 1;
BA_ "GenSigSendType" SG_ 1097 RESP_REM_DataByte3_APM 1;
BA_ "GenSigSendType" SG_ 1097 RESP_REM_DataByte4_APM 1;
BA_ "GenSigSendType" SG_ 1097 RESP_REM_LengthTyp_APM 1;
BA_ "GenSigSendType" SG_ 1097 RESP_REM_DataLength_APM 1;
BA_ "GenSigSendType" SG_ 1170 AmbLight_Error_Z4 3;
BA_ "GenSigSendType" SG_ 1170 AmbLight_LinError_Z4 3;
BA_ "GenSigSendType" SG_ 1170 AmbLight_Error_Z4B 3;
BA_ "GenSigSendType" SG_ 1170 AmbLight_LinError_Z4B 3;
BA_ "GenSigSendType" SG_ 1170 AmbLight_Error_Z5 3;
BA_ "GenSigSendType" SG_ 1170 AmbLight_LinError_Z5 3;
BA_ "GenSigSendType" SG_ 1170 AmbLight_Error_Z5B 3;
BA_ "GenSigSendType" SG_ 1170 AmbLight_LinError_Z5B 3;
BA_ "GenSigSendType" SG_ 1170 AmbLight_Error_Z9 3;
BA_ "GenSigSendType" SG_ 1170 AmbLight_LinError_Z9 3;
BA_ "GenSigSendType" SG_ 1170 AmbLight_Error_Z10 3;
BA_ "GenSigSendType" SG_ 1170 AmbLight_LinError_Z10 3;
BA_ "InvalidValue" SG_ 1219 ALIVE_APM_RE_WarnMsg "Fh";
BA_ "GenSigSendType" SG_ 1219 APM_Malfunction 4;
BA_ "GenSigSendType" SG_ 1219 ChildWindowLockStS 4;
BA_ "GenSigSendType" SG_ 1219 APM_Warning_Flag_3 4;
BA_ "GenSigSendType" SG_ 1219 APM_Warning_Flag_4 4;
BA_ "GenSigSendType" SG_ 1219 APM_Warning_Flag_5 4;
BA_ "GenSigSendType" SG_ 1219 APM_Warning_Flag_6 4;
BA_ "GenSigSendType" SG_ 1219 APM_Warning_Flag_7 4;
BA_ "GenSigSendType" SG_ 1219 APM_Warning_Flag_8 4;
BA_ "GenSigSendType" SG_ 1219 APM_Warning_Flag_9 4;
BA_ "GenSigSendType" SG_ 1219 APM_Warning_Flag_10 4;
BA_ "GenSigSendType" SG_ 1219 APM_Warning_Flag_11 4;
BA_ "GenSigSendType" SG_ 1219 APM_Warning_Flag_12 4;
BA_ "InvalidValue" SG_ 1242 ALIVE_BCM_R_WarnMsg_R "Fh";
BA_ "SystemSignalLongSymbol" SG_ 1242 BCM_R_IDB_AutoHazardBlinking_Mal "BCM_R_IDB_AutoHazardBlinking_Malf";
BA_ "GenSigSendType" SG_ 1861 BCMRE_DebugSignal01 1;
BA_ "GenSigSendType" SG_ 1861 BCMRE_DebugSignal02 1;
BA_ "GenSigSendType" SG_ 1861 BCMRE_DebugSignal03 1;
BA_ "GenSigSendType" SG_ 1861 BCMRE_DebugSignal04 1;
BA_ "GenSigSendType" SG_ 1861 BCMRE_DebugSignal05 1;
BA_ "GenSigSendType" SG_ 1861 BCMRE_DebugSignal06 1;
BA_ "GenSigSendType" SG_ 1861 BCMRE_DebugSignal07 1;
BA_ "GenSigSendType" SG_ 1861 BCMRE_DebugSignal08 1;
BA_ "GenSigSendType" SG_ 924 DKCU_Immo_Byte_0 1;
BA_ "GenSigSendType" SG_ 924 DKCU_Immo_Byte_1 1;
BA_ "GenSigSendType" SG_ 924 DKCU_Immo_Byte_2 1;
BA_ "GenSigSendType" SG_ 924 DKCU_Immo_Byte_3 1;
BA_ "GenSigSendType" SG_ 924 DKCU_Immo_Byte_4 1;
BA_ "GenSigSendType" SG_ 924 DKCU_Immo_Byte_5 1;
BA_ "GenSigSendType" SG_ 924 DKCU_Immo_Byte_6 1;
BA_ "GenSigSendType" SG_ 924 DKCU_Immo_Byte_7 1;
BA_ "InvalidValue" SG_ 1001 ALIVE_DK_KeyStatus "fh";
BA_ "GenSigSendType" SG_ 1001 DKCU_PrimaryDKValidationSts 4;
BA_ "GenSigSendType" SG_ 1001 DKCU_Guest1DKValidationSts 4;
BA_ "GenSigSendType" SG_ 1001 DKCU_Guest2DKValidationSts 4;
BA_ "GenSigSendType" SG_ 1001 DKCU_Guest3DKValidationSts 4;
BA_ "GenSigSendType" SG_ 1001 DKCU_Device_ID_Primary 4;
BA_ "GenSigSendType" SG_ 1001 DKCU_Device_ID_Guest1 4;
BA_ "GenSigSendType" SG_ 1001 DKCU_Device_ID_Guest2 4;
BA_ "GenSigSendType" SG_ 1001 DKCU_Device_ID_Guest3 4;
BA_ "InvalidValue" SG_ 1002 ALIVE_DK_KeyLocation "Fh";
BA_ "SystemSignalLongSymbol" SG_ 1002 DKCU_PhoneKey_PrimaryUser_Locati "DKCU_PhoneKey_PrimaryUser_Location";
BA_ "SystemSignalLongSymbol" SG_ 1002 DKCU_PhoneKey_PrimaryUser_Motion "DKCU_PhoneKey_PrimaryUser_MotionFlag";
BA_ "SystemSignalLongSymbol" SG_ 1002 DKCU_PhoneKey_PrimaryUser_Age_10 "DKCU_PhoneKey_PrimaryUser_Age_10ms";
BA_ "InvalidValue" SG_ 1002 DKCU_PhoneKey_PrimaryUser_RSSI "FFh";
BA_ "SystemSignalLongSymbol" SG_ 1002 DKCU_PhoneKey_PrimaryUser_ConfLv "DKCU_PhoneKey_PrimaryUser_ConfLvl";
BA_ "SystemSignalLongSymbol" SG_ 1002 DKCU_UWB_Ranging_PrimaryUser_Dis "DKCU_UWB_Ranging_PrimaryUser_Distance";
BA_ "SystemSignalLongSymbol" SG_ 1002 DKCU_BLE_Ranging_PrimaryUser_Dis "DKCU_BLE_Ranging_PrimaryUser_Distance";
BA_ "SystemSignalLongSymbol" SG_ 1002 DKCU_CVC_PrimaryUser_DevicePolic "DKCU_CVC_PrimaryUser_DevicePolicy";
BA_ "InvalidValue" SG_ 1003 ALIVE_DK_DKCU_Command "Fh";
BA_ "InvalidValue" SG_ 1005 ALIVE_DK_AnchorStatus_NFC "Fh";
BA_ "InvalidValue" SG_ 1006 ALIVE_DK_SharingKeyStatus "Fh";
BA_ "GenSigSendType" SG_ 1006 DKCU_DigitalKeyShareUpdate 7;
BA_ "InvalidValue" SG_ 1007 ALIVE_DKCU_DoorControl "Fh";
BA_ "InvalidValue" SG_ 1008 ALIVE_DKCU_TailgateBonnetControl "Fh";
BA_ "InvalidValue" SG_ 1010 ALIVE_DK_AnchorSignal_Status "Fh";
BA_ "GenSigStartValue" SG_ 1010 DKCU_BLE_RSSI_Front_dBm 127;
BA_ "GenSigStartValue" SG_ 1010 DKCU_BLE_RSSI_Right_dBm 127;
BA_ "GenSigStartValue" SG_ 1010 DKCU_BLE_RSSI_Left_dBm 127;
BA_ "GenSigStartValue" SG_ 1010 DKCU_BLE_RSSI_Rear_dBm 127;
BA_ "GenSigStartValue" SG_ 1010 DKCU_BLE_RSSI_MasterECU_dBm 127;
BA_ "GenSigStartValue" SG_ 1010 DKCU_UWB_ConfLvl_Front_dBm 127;
BA_ "GenSigStartValue" SG_ 1010 DKCU_UWB_ConfLvl_Right_dBm 127;
BA_ "GenSigStartValue" SG_ 1010 DKCU_UWB_ConfLvl_Left_dBm 127;
BA_ "GenSigStartValue" SG_ 1010 DKCU_UWB_ConfLvl_Rear_dBm 127;
BA_ "GenSigStartValue" SG_ 1010 DKCU_UWB_ConfLvl_MasterECU_dBm 127;
BA_ "GenSigStartValue" SG_ 1010 DKCU_UWB_ConfLvl_CPD_dBm 127;
BA_ "InvalidValue" SG_ 1012 ALIVE_DK_WarnMsg "Fh";
BA_ "SystemSignalLongSymbol" SG_ 1012 DK_PhoneKeyNfcExteriorAuthFailAl "DK_PhoneKeyNfcExteriorAuthFailAlert";
BA_ "SystemSignalLongSymbol" SG_ 1012 DK_PhoneKeyNfcInteriorAuthFailAl "DK_PhoneKeyNfcInteriorAuthFailAlert";
BA_ "InvalidValue" SG_ 1013 ALIVE_DK_CPDStatus "Fh";
BA_ "InvalidValue" SG_ 1014 ALIVE_DK_PhoneInformation "Fh";
BA_ "InvalidValue" SG_ 1016 ALIVE_DKCU_TempIntervention_Req "Fh";
BA_ "InvalidValue" SG_ 1018 ALIVE_DK_GestureSts "Fh";
BA_ "GenSigSendType" SG_ 1018 DKCU_CVC_Footkick_Sts 4;
BA_ "GenSigSendType" SG_ 1974 DKCU_Req_RandomData 2;
BA_ "GenSigSendType" SG_ 1974 DKCU_Req_MAC 2;
BA_ "GenSigTimeoutTime_ALL" SG_ 1281 BCM_FL_srcNodeID 2000;
BA_ "GenSigTimeoutTime_ALL" SG_ 1281 BCM_FL_CtrlBitVector 2000;
BA_ "GenSigTimeoutTime_ALL" SG_ 1281 BCM_FL_usrData0 2000;
BA_ "GenSigTimeoutTime_ALL" SG_ 1281 BCM_FL_usrData1 2000;
BA_ "GenSigTimeoutTime_ALL" SG_ 1281 BCM_FL_usrData2 2000;
BA_ "GenSigTimeoutTime_ALL" SG_ 1281 BCM_FL_usrData3 2000;
BA_ "GenSigTimeoutTime_ALL" SG_ 1281 BCM_FL_usrData4 2000;
BA_ "GenSigTimeoutTime_ALL" SG_ 1281 BCM_FL_usrData5 2000;
BA_ "InvalidValue" SG_ 1282 CVC_srcNodeID "FFh";
BA_ "GenSigTimeoutTime_ALL" SG_ 1282 CVC_srcNodeID 2000;
BA_ "GenSigTimeoutTime_ALL" SG_ 1282 CVC_CtrlBitVector 2000;
BA_ "GenSigStartValue" SG_ 1282 CVC_usrData0 255;
BA_ "GenSigTimeoutTime_ALL" SG_ 1282 CVC_usrData0 2000;
BA_ "GenSigStartValue" SG_ 1282 CVC_usrData1 255;
BA_ "GenSigTimeoutTime_ALL" SG_ 1282 CVC_usrData1 2000;
BA_ "GenSigStartValue" SG_ 1282 CVC_usrData2 255;
BA_ "GenSigTimeoutTime_ALL" SG_ 1282 CVC_usrData2 2000;
BA_ "GenSigStartValue" SG_ 1282 CVC_usrData3 255;
BA_ "GenSigTimeoutTime_ALL" SG_ 1282 CVC_usrData3 2000;
BA_ "GenSigStartValue" SG_ 1282 CVC_usrData4 255;
BA_ "GenSigTimeoutTime_ALL" SG_ 1282 CVC_usrData4 2000;
BA_ "GenSigStartValue" SG_ 1282 CVC_usrData5 255;
BA_ "GenSigTimeoutTime_ALL" SG_ 1282 CVC_usrData5 2000;
BA_ "GenSigTimeoutTime_ALL" SG_ 1286 BCM_FR_srcNodeID 2000;
BA_ "GenSigTimeoutTime_ALL" SG_ 1286 BCM_FR_CtrlBitVector 2000;
BA_ "GenSigTimeoutTime_ALL" SG_ 1286 BCM_FR_usrData0 2000;
BA_ "GenSigTimeoutTime_ALL" SG_ 1286 BCM_FR_usrData1 2000;
BA_ "GenSigTimeoutTime_ALL" SG_ 1286 BCM_FR_usrData2 2000;
BA_ "GenSigTimeoutTime_ALL" SG_ 1286 BCM_FR_usrData3 2000;
BA_ "GenSigTimeoutTime_ALL" SG_ 1286 BCM_FR_usrData4 2000;
BA_ "GenSigTimeoutTime_ALL" SG_ 1286 BCM_FR_usrData5 2000;
BA_ "GenSigStartValue" SG_ 1287 BCM_R_srcNodeID 7;
BA_ "GenSigTimeoutTime_ALL" SG_ 1287 BCM_R_srcNodeID 2000;
BA_ "GenSigTimeoutTime_ALL" SG_ 1287 BCM_R_CtrlBitVector 2000;
BA_ "GenSigTimeoutTime_ALL" SG_ 1287 BCM_R_usrData0 2000;
BA_ "GenSigTimeoutTime_ALL" SG_ 1287 BCM_R_usrData1 2000;
BA_ "GenSigTimeoutTime_ALL" SG_ 1287 BCM_R_usrData2 2000;
BA_ "GenSigTimeoutTime_ALL" SG_ 1287 BCM_R_usrData3 2000;
BA_ "GenSigTimeoutTime_ALL" SG_ 1287 BCM_R_usrData4 2000;
BA_ "GenSigTimeoutTime_ALL" SG_ 1287 BCM_R_usrData5 2000;
BA_ "GenSigTimeoutTime_ALL" SG_ 1356 DKCU_srcNodeID 2000;
BA_ "GenSigTimeoutTime_ALL" SG_ 1356 DKCU_CtrlBitVector 2000;
BA_ "GenSigTimeoutTime_ALL" SG_ 1356 DKCU_usrData0 2000;
BA_ "GenSigTimeoutTime_ALL" SG_ 1356 DKCU_usrData1 2000;
BA_ "GenSigTimeoutTime_ALL" SG_ 1356 DKCU_usrData2 2000;
BA_ "GenSigTimeoutTime_ALL" SG_ 1356 DKCU_usrData3 2000;
BA_ "GenSigTimeoutTime_ALL" SG_ 1356 DKCU_usrData4 2000;
BA_ "GenSigTimeoutTime_ALL" SG_ 1356 DKCU_usrData5 2000;
BA_ "GenSigSendType" SG_ 1537 BCM_FL_DiagRespData0 1;
BA_ "GenSigSendType" SG_ 1537 BCM_FL_DiagRespData1 1;
BA_ "GenSigSendType" SG_ 1537 BCM_FL_DiagRespData2 1;
BA_ "GenSigSendType" SG_ 1537 BCM_FL_DiagRespData3 1;
BA_ "GenSigSendType" SG_ 1537 BCM_FL_DiagRespData4 1;
BA_ "GenSigSendType" SG_ 1537 BCM_FL_DiagRespData5 1;
BA_ "GenSigSendType" SG_ 1537 BCM_FL_DiagRespData6 1;
BA_ "GenSigSendType" SG_ 1537 BCM_FL_DiagRespData7 1;
BA_ "GenSigSendType" SG_ 1537 BCM_FL_DiagRespData8 1;
BA_ "GenSigSendType" SG_ 1537 BCM_FL_DiagRespData9 1;
BA_ "GenSigSendType" SG_ 1537 BCM_FL_DiagRespData10 1;
BA_ "GenSigSendType" SG_ 1537 BCM_FL_DiagRespData11 1;
BA_ "GenSigSendType" SG_ 1537 BCM_FL_DiagRespData12 1;
BA_ "GenSigSendType" SG_ 1537 BCM_FL_DiagRespData13 1;
BA_ "GenSigSendType" SG_ 1537 BCM_FL_DiagRespData14 1;
BA_ "GenSigSendType" SG_ 1537 BCM_FL_DiagRespData15 1;
BA_ "GenSigSendType" SG_ 1537 BCM_FL_DiagRespData16 1;
BA_ "GenSigSendType" SG_ 1537 BCM_FL_DiagRespData17 1;
BA_ "GenSigSendType" SG_ 1537 BCM_FL_DiagRespData18 1;
BA_ "GenSigSendType" SG_ 1537 BCM_FL_DiagRespData19 1;
BA_ "GenSigSendType" SG_ 1537 BCM_FL_DiagRespData20 1;
BA_ "GenSigSendType" SG_ 1537 BCM_FL_DiagRespData21 1;
BA_ "GenSigSendType" SG_ 1537 BCM_FL_DiagRespData22 1;
BA_ "GenSigSendType" SG_ 1537 BCM_FL_DiagRespData23 1;
BA_ "GenSigSendType" SG_ 1537 BCM_FL_DiagRespData24 1;
BA_ "GenSigSendType" SG_ 1537 BCM_FL_DiagRespData25 1;
BA_ "GenSigSendType" SG_ 1537 BCM_FL_DiagRespData26 1;
BA_ "GenSigSendType" SG_ 1537 BCM_FL_DiagRespData27 1;
BA_ "GenSigSendType" SG_ 1537 BCM_FL_DiagRespData28 1;
BA_ "GenSigSendType" SG_ 1537 BCM_FL_DiagRespData29 1;
BA_ "GenSigSendType" SG_ 1537 BCM_FL_DiagRespData30 1;
BA_ "GenSigSendType" SG_ 1537 BCM_FL_DiagRespData31 1;
BA_ "GenSigSendType" SG_ 1537 BCM_FL_DiagRespData32 1;
BA_ "GenSigSendType" SG_ 1537 BCM_FL_DiagRespData33 1;
BA_ "GenSigSendType" SG_ 1537 BCM_FL_DiagRespData34 1;
BA_ "GenSigSendType" SG_ 1537 BCM_FL_DiagRespData35 1;
BA_ "GenSigSendType" SG_ 1537 BCM_FL_DiagRespData36 1;
BA_ "GenSigSendType" SG_ 1537 BCM_FL_DiagRespData37 1;
BA_ "GenSigSendType" SG_ 1537 BCM_FL_DiagRespData38 1;
BA_ "GenSigSendType" SG_ 1537 BCM_FL_DiagRespData39 1;
BA_ "GenSigSendType" SG_ 1537 BCM_FL_DiagRespData40 1;
BA_ "GenSigSendType" SG_ 1537 BCM_FL_DiagRespData41 1;
BA_ "GenSigSendType" SG_ 1537 BCM_FL_DiagRespData42 1;
BA_ "GenSigSendType" SG_ 1537 BCM_FL_DiagRespData43 1;
BA_ "GenSigSendType" SG_ 1537 BCM_FL_DiagRespData44 1;
BA_ "GenSigSendType" SG_ 1537 BCM_FL_DiagRespData45 1;
BA_ "GenSigSendType" SG_ 1537 BCM_FL_DiagRespData46 1;
BA_ "GenSigSendType" SG_ 1537 BCM_FL_DiagRespData47 1;
BA_ "GenSigSendType" SG_ 1537 BCM_FL_DiagRespData48 1;
BA_ "GenSigSendType" SG_ 1537 BCM_FL_DiagRespData49 1;
BA_ "GenSigSendType" SG_ 1537 BCM_FL_DiagRespData50 1;
BA_ "GenSigSendType" SG_ 1537 BCM_FL_DiagRespData51 1;
BA_ "GenSigSendType" SG_ 1537 BCM_FL_DiagRespData52 1;
BA_ "GenSigSendType" SG_ 1537 BCM_FL_DiagRespData53 1;
BA_ "GenSigSendType" SG_ 1537 BCM_FL_DiagRespData54 1;
BA_ "GenSigSendType" SG_ 1537 BCM_FL_DiagRespData55 1;
BA_ "GenSigSendType" SG_ 1537 BCM_FL_DiagRespData56 1;
BA_ "GenSigSendType" SG_ 1537 BCM_FL_DiagRespData57 1;
BA_ "GenSigSendType" SG_ 1537 BCM_FL_DiagRespData58 1;
BA_ "GenSigSendType" SG_ 1537 BCM_FL_DiagRespData59 1;
BA_ "GenSigSendType" SG_ 1537 BCM_FL_DiagRespData60 1;
BA_ "GenSigSendType" SG_ 1537 BCM_FL_DiagRespData61 1;
BA_ "GenSigSendType" SG_ 1537 BCM_FL_DiagRespData62 1;
BA_ "GenSigSendType" SG_ 1537 BCM_FL_DiagRespData63 1;
BA_ "GenSigSendType" SG_ 1665 BCM_FL_DiagReqData0 1;
BA_ "GenSigSendType" SG_ 1665 BCM_FL_DiagReqData1 1;
BA_ "GenSigSendType" SG_ 1665 BCM_FL_DiagReqData2 1;
BA_ "GenSigSendType" SG_ 1665 BCM_FL_DiagReqData3 1;
BA_ "GenSigSendType" SG_ 1665 BCM_FL_DiagReqData4 1;
BA_ "GenSigSendType" SG_ 1665 BCM_FL_DiagReqData5 1;
BA_ "GenSigSendType" SG_ 1665 BCM_FL_DiagReqData6 1;
BA_ "GenSigSendType" SG_ 1665 BCM_FL_DiagReqData7 1;
BA_ "GenSigSendType" SG_ 1665 BCM_FL_DiagReqData8 1;
BA_ "GenSigSendType" SG_ 1665 BCM_FL_DiagReqData9 1;
BA_ "GenSigSendType" SG_ 1665 BCM_FL_DiagReqData10 1;
BA_ "GenSigSendType" SG_ 1665 BCM_FL_DiagReqData11 1;
BA_ "GenSigSendType" SG_ 1665 BCM_FL_DiagReqData12 1;
BA_ "GenSigSendType" SG_ 1665 BCM_FL_DiagReqData13 1;
BA_ "GenSigSendType" SG_ 1665 BCM_FL_DiagReqData14 1;
BA_ "GenSigSendType" SG_ 1665 BCM_FL_DiagReqData15 1;
BA_ "GenSigSendType" SG_ 1665 BCM_FL_DiagReqData16 1;
BA_ "GenSigSendType" SG_ 1665 BCM_FL_DiagReqData17 1;
BA_ "GenSigSendType" SG_ 1665 BCM_FL_DiagReqData18 1;
BA_ "GenSigSendType" SG_ 1665 BCM_FL_DiagReqData19 1;
BA_ "GenSigSendType" SG_ 1665 BCM_FL_DiagReqData20 1;
BA_ "GenSigSendType" SG_ 1665 BCM_FL_DiagReqData21 1;
BA_ "GenSigSendType" SG_ 1665 BCM_FL_DiagReqData22 1;
BA_ "GenSigSendType" SG_ 1665 BCM_FL_DiagReqData23 1;
BA_ "GenSigSendType" SG_ 1665 BCM_FL_DiagReqData24 1;
BA_ "GenSigSendType" SG_ 1665 BCM_FL_DiagReqData25 1;
BA_ "GenSigSendType" SG_ 1665 BCM_FL_DiagReqData26 1;
BA_ "GenSigSendType" SG_ 1665 BCM_FL_DiagReqData27 1;
BA_ "GenSigSendType" SG_ 1665 BCM_FL_DiagReqData28 1;
BA_ "GenSigSendType" SG_ 1665 BCM_FL_DiagReqData29 1;
BA_ "GenSigSendType" SG_ 1665 BCM_FL_DiagReqData30 1;
BA_ "GenSigSendType" SG_ 1665 BCM_FL_DiagReqData31 1;
BA_ "GenSigSendType" SG_ 1665 BCM_FL_DiagReqData32 1;
BA_ "GenSigSendType" SG_ 1665 BCM_FL_DiagReqData33 1;
BA_ "GenSigSendType" SG_ 1665 BCM_FL_DiagReqData34 1;
BA_ "GenSigSendType" SG_ 1665 BCM_FL_DiagReqData35 1;
BA_ "GenSigSendType" SG_ 1665 BCM_FL_DiagReqData36 1;
BA_ "GenSigSendType" SG_ 1665 BCM_FL_DiagReqData37 1;
BA_ "GenSigSendType" SG_ 1665 BCM_FL_DiagReqData38 1;
BA_ "GenSigSendType" SG_ 1665 BCM_FL_DiagReqData39 1;
BA_ "GenSigSendType" SG_ 1665 BCM_FL_DiagReqData40 1;
BA_ "GenSigSendType" SG_ 1665 BCM_FL_DiagReqData41 1;
BA_ "GenSigSendType" SG_ 1665 BCM_FL_DiagReqData42 1;
BA_ "GenSigSendType" SG_ 1665 BCM_FL_DiagReqData43 1;
BA_ "GenSigSendType" SG_ 1665 BCM_FL_DiagReqData44 1;
BA_ "GenSigSendType" SG_ 1665 BCM_FL_DiagReqData45 1;
BA_ "GenSigSendType" SG_ 1665 BCM_FL_DiagReqData46 1;
BA_ "GenSigSendType" SG_ 1665 BCM_FL_DiagReqData47 1;
BA_ "GenSigSendType" SG_ 1665 BCM_FL_DiagReqData48 1;
BA_ "GenSigSendType" SG_ 1665 BCM_FL_DiagReqData49 1;
BA_ "GenSigSendType" SG_ 1665 BCM_FL_DiagReqData50 1;
BA_ "GenSigSendType" SG_ 1665 BCM_FL_DiagReqData51 1;
BA_ "GenSigSendType" SG_ 1665 BCM_FL_DiagReqData52 1;
BA_ "GenSigSendType" SG_ 1665 BCM_FL_DiagReqData53 1;
BA_ "GenSigSendType" SG_ 1665 BCM_FL_DiagReqData54 1;
BA_ "GenSigSendType" SG_ 1665 BCM_FL_DiagReqData55 1;
BA_ "GenSigSendType" SG_ 1665 BCM_FL_DiagReqData56 1;
BA_ "GenSigSendType" SG_ 1665 BCM_FL_DiagReqData57 1;
BA_ "GenSigSendType" SG_ 1665 BCM_FL_DiagReqData58 1;
BA_ "GenSigSendType" SG_ 1665 BCM_FL_DiagReqData59 1;
BA_ "GenSigSendType" SG_ 1665 BCM_FL_DiagReqData60 1;
BA_ "GenSigSendType" SG_ 1665 BCM_FL_DiagReqData61 1;
BA_ "GenSigSendType" SG_ 1665 BCM_FL_DiagReqData62 1;
BA_ "GenSigSendType" SG_ 1665 BCM_FL_DiagReqData63 1;
BA_ "GenSigSendType" SG_ 1542 BCM_FR_DiagRespData0 1;
BA_ "GenSigSendType" SG_ 1542 BCM_FR_DiagRespData1 1;
BA_ "GenSigSendType" SG_ 1542 BCM_FR_DiagRespData2 1;
BA_ "GenSigSendType" SG_ 1542 BCM_FR_DiagRespData3 1;
BA_ "GenSigSendType" SG_ 1542 BCM_FR_DiagRespData4 1;
BA_ "GenSigSendType" SG_ 1542 BCM_FR_DiagRespData5 1;
BA_ "GenSigSendType" SG_ 1542 BCM_FR_DiagRespData6 1;
BA_ "GenSigSendType" SG_ 1542 BCM_FR_DiagRespData7 1;
BA_ "GenSigSendType" SG_ 1542 BCM_FR_DiagRespData8 1;
BA_ "GenSigSendType" SG_ 1542 BCM_FR_DiagRespData9 1;
BA_ "GenSigSendType" SG_ 1542 BCM_FR_DiagRespData10 1;
BA_ "GenSigSendType" SG_ 1542 BCM_FR_DiagRespData11 1;
BA_ "GenSigSendType" SG_ 1542 BCM_FR_DiagRespData12 1;
BA_ "GenSigSendType" SG_ 1542 BCM_FR_DiagRespData13 1;
BA_ "GenSigSendType" SG_ 1542 BCM_FR_DiagRespData14 1;
BA_ "GenSigSendType" SG_ 1542 BCM_FR_DiagRespData15 1;
BA_ "GenSigSendType" SG_ 1542 BCM_FR_DiagRespData16 1;
BA_ "GenSigSendType" SG_ 1542 BCM_FR_DiagRespData17 1;
BA_ "GenSigSendType" SG_ 1542 BCM_FR_DiagRespData18 1;
BA_ "GenSigSendType" SG_ 1542 BCM_FR_DiagRespData19 1;
BA_ "GenSigSendType" SG_ 1542 BCM_FR_DiagRespData20 1;
BA_ "GenSigSendType" SG_ 1542 BCM_FR_DiagRespData21 1;
BA_ "GenSigSendType" SG_ 1542 BCM_FR_DiagRespData22 1;
BA_ "GenSigSendType" SG_ 1542 BCM_FR_DiagRespData23 1;
BA_ "GenSigSendType" SG_ 1542 BCM_FR_DiagRespData24 1;
BA_ "GenSigSendType" SG_ 1542 BCM_FR_DiagRespData25 1;
BA_ "GenSigSendType" SG_ 1542 BCM_FR_DiagRespData26 1;
BA_ "GenSigSendType" SG_ 1542 BCM_FR_DiagRespData27 1;
BA_ "GenSigSendType" SG_ 1542 BCM_FR_DiagRespData28 1;
BA_ "GenSigSendType" SG_ 1542 BCM_FR_DiagRespData29 1;
BA_ "GenSigSendType" SG_ 1542 BCM_FR_DiagRespData30 1;
BA_ "GenSigSendType" SG_ 1542 BCM_FR_DiagRespData31 1;
BA_ "GenSigSendType" SG_ 1542 BCM_FR_DiagRespData32 1;
BA_ "GenSigSendType" SG_ 1542 BCM_FR_DiagRespData33 1;
BA_ "GenSigSendType" SG_ 1542 BCM_FR_DiagRespData34 1;
BA_ "GenSigSendType" SG_ 1542 BCM_FR_DiagRespData35 1;
BA_ "GenSigSendType" SG_ 1542 BCM_FR_DiagRespData36 1;
BA_ "GenSigSendType" SG_ 1542 BCM_FR_DiagRespData37 1;
BA_ "GenSigSendType" SG_ 1542 BCM_FR_DiagRespData38 1;
BA_ "GenSigSendType" SG_ 1542 BCM_FR_DiagRespData39 1;
BA_ "GenSigSendType" SG_ 1542 BCM_FR_DiagRespData40 1;
BA_ "GenSigSendType" SG_ 1542 BCM_FR_DiagRespData41 1;
BA_ "GenSigSendType" SG_ 1542 BCM_FR_DiagRespData42 1;
BA_ "GenSigSendType" SG_ 1542 BCM_FR_DiagRespData43 1;
BA_ "GenSigSendType" SG_ 1542 BCM_FR_DiagRespData44 1;
BA_ "GenSigSendType" SG_ 1542 BCM_FR_DiagRespData45 1;
BA_ "GenSigSendType" SG_ 1542 BCM_FR_DiagRespData46 1;
BA_ "GenSigSendType" SG_ 1542 BCM_FR_DiagRespData47 1;
BA_ "GenSigSendType" SG_ 1542 BCM_FR_DiagRespData48 1;
BA_ "GenSigSendType" SG_ 1542 BCM_FR_DiagRespData49 1;
BA_ "GenSigSendType" SG_ 1542 BCM_FR_DiagRespData50 1;
BA_ "GenSigSendType" SG_ 1542 BCM_FR_DiagRespData51 1;
BA_ "GenSigSendType" SG_ 1542 BCM_FR_DiagRespData52 1;
BA_ "GenSigSendType" SG_ 1542 BCM_FR_DiagRespData53 1;
BA_ "GenSigSendType" SG_ 1542 BCM_FR_DiagRespData54 1;
BA_ "GenSigSendType" SG_ 1542 BCM_FR_DiagRespData55 1;
BA_ "GenSigSendType" SG_ 1542 BCM_FR_DiagRespData56 1;
BA_ "GenSigSendType" SG_ 1542 BCM_FR_DiagRespData57 1;
BA_ "GenSigSendType" SG_ 1542 BCM_FR_DiagRespData58 1;
BA_ "GenSigSendType" SG_ 1542 BCM_FR_DiagRespData59 1;
BA_ "GenSigSendType" SG_ 1542 BCM_FR_DiagRespData60 1;
BA_ "GenSigSendType" SG_ 1542 BCM_FR_DiagRespData61 1;
BA_ "GenSigSendType" SG_ 1542 BCM_FR_DiagRespData62 1;
BA_ "GenSigSendType" SG_ 1542 BCM_FR_DiagRespData63 1;
BA_ "GenSigSendType" SG_ 1670 BCM_FR_DiagReqData0 1;
BA_ "GenSigSendType" SG_ 1670 BCM_FR_DiagReqData1 1;
BA_ "GenSigSendType" SG_ 1670 BCM_FR_DiagReqData2 1;
BA_ "GenSigSendType" SG_ 1670 BCM_FR_DiagReqData3 1;
BA_ "GenSigSendType" SG_ 1670 BCM_FR_DiagReqData4 1;
BA_ "GenSigSendType" SG_ 1670 BCM_FR_DiagReqData5 1;
BA_ "GenSigSendType" SG_ 1670 BCM_FR_DiagReqData6 1;
BA_ "GenSigSendType" SG_ 1670 BCM_FR_DiagReqData7 1;
BA_ "GenSigSendType" SG_ 1670 BCM_FR_DiagReqData8 1;
BA_ "GenSigSendType" SG_ 1670 BCM_FR_DiagReqData9 1;
BA_ "GenSigSendType" SG_ 1670 BCM_FR_DiagReqData10 1;
BA_ "GenSigSendType" SG_ 1670 BCM_FR_DiagReqData11 1;
BA_ "GenSigSendType" SG_ 1670 BCM_FR_DiagReqData12 1;
BA_ "GenSigSendType" SG_ 1670 BCM_FR_DiagReqData13 1;
BA_ "GenSigSendType" SG_ 1670 BCM_FR_DiagReqData14 1;
BA_ "GenSigSendType" SG_ 1670 BCM_FR_DiagReqData15 1;
BA_ "GenSigSendType" SG_ 1670 BCM_FR_DiagReqData16 1;
BA_ "GenSigSendType" SG_ 1670 BCM_FR_DiagReqData17 1;
BA_ "GenSigSendType" SG_ 1670 BCM_FR_DiagReqData18 1;
BA_ "GenSigSendType" SG_ 1670 BCM_FR_DiagReqData19 1;
BA_ "GenSigSendType" SG_ 1670 BCM_FR_DiagReqData20 1;
BA_ "GenSigSendType" SG_ 1670 BCM_FR_DiagReqData21 1;
BA_ "GenSigSendType" SG_ 1670 BCM_FR_DiagReqData22 1;
BA_ "GenSigSendType" SG_ 1670 BCM_FR_DiagReqData23 1;
BA_ "GenSigSendType" SG_ 1670 BCM_FR_DiagReqData24 1;
BA_ "GenSigSendType" SG_ 1670 BCM_FR_DiagReqData25 1;
BA_ "GenSigSendType" SG_ 1670 BCM_FR_DiagReqData26 1;
BA_ "GenSigSendType" SG_ 1670 BCM_FR_DiagReqData27 1;
BA_ "GenSigSendType" SG_ 1670 BCM_FR_DiagReqData28 1;
BA_ "GenSigSendType" SG_ 1670 BCM_FR_DiagReqData29 1;
BA_ "GenSigSendType" SG_ 1670 BCM_FR_DiagReqData30 1;
BA_ "GenSigSendType" SG_ 1670 BCM_FR_DiagReqData31 1;
BA_ "GenSigSendType" SG_ 1670 BCM_FR_DiagReqData32 1;
BA_ "GenSigSendType" SG_ 1670 BCM_FR_DiagReqData33 1;
BA_ "GenSigSendType" SG_ 1670 BCM_FR_DiagReqData34 1;
BA_ "GenSigSendType" SG_ 1670 BCM_FR_DiagReqData35 1;
BA_ "GenSigSendType" SG_ 1670 BCM_FR_DiagReqData36 1;
BA_ "GenSigSendType" SG_ 1670 BCM_FR_DiagReqData37 1;
BA_ "GenSigSendType" SG_ 1670 BCM_FR_DiagReqData38 1;
BA_ "GenSigSendType" SG_ 1670 BCM_FR_DiagReqData39 1;
BA_ "GenSigSendType" SG_ 1670 BCM_FR_DiagReqData40 1;
BA_ "GenSigSendType" SG_ 1670 BCM_FR_DiagReqData41 1;
BA_ "GenSigSendType" SG_ 1670 BCM_FR_DiagReqData42 1;
BA_ "GenSigSendType" SG_ 1670 BCM_FR_DiagReqData43 1;
BA_ "GenSigSendType" SG_ 1670 BCM_FR_DiagReqData44 1;
BA_ "GenSigSendType" SG_ 1670 BCM_FR_DiagReqData45 1;
BA_ "GenSigSendType" SG_ 1670 BCM_FR_DiagReqData46 1;
BA_ "GenSigSendType" SG_ 1670 BCM_FR_DiagReqData47 1;
BA_ "GenSigSendType" SG_ 1670 BCM_FR_DiagReqData48 1;
BA_ "GenSigSendType" SG_ 1670 BCM_FR_DiagReqData49 1;
BA_ "GenSigSendType" SG_ 1670 BCM_FR_DiagReqData50 1;
BA_ "GenSigSendType" SG_ 1670 BCM_FR_DiagReqData51 1;
BA_ "GenSigSendType" SG_ 1670 BCM_FR_DiagReqData52 1;
BA_ "GenSigSendType" SG_ 1670 BCM_FR_DiagReqData53 1;
BA_ "GenSigSendType" SG_ 1670 BCM_FR_DiagReqData54 1;
BA_ "GenSigSendType" SG_ 1670 BCM_FR_DiagReqData55 1;
BA_ "GenSigSendType" SG_ 1670 BCM_FR_DiagReqData56 1;
BA_ "GenSigSendType" SG_ 1670 BCM_FR_DiagReqData57 1;
BA_ "GenSigSendType" SG_ 1670 BCM_FR_DiagReqData58 1;
BA_ "GenSigSendType" SG_ 1670 BCM_FR_DiagReqData59 1;
BA_ "GenSigSendType" SG_ 1670 BCM_FR_DiagReqData60 1;
BA_ "GenSigSendType" SG_ 1670 BCM_FR_DiagReqData61 1;
BA_ "GenSigSendType" SG_ 1670 BCM_FR_DiagReqData62 1;
BA_ "GenSigSendType" SG_ 1670 BCM_FR_DiagReqData63 1;
BA_ "GenSigSendType" SG_ 1543 BCM_R_DiagRespData0 1;
BA_ "GenSigSendType" SG_ 1543 BCM_R_DiagRespData1 1;
BA_ "GenSigSendType" SG_ 1543 BCM_R_DiagRespData2 1;
BA_ "GenSigSendType" SG_ 1543 BCM_R_DiagRespData3 1;
BA_ "GenSigSendType" SG_ 1543 BCM_R_DiagRespData4 1;
BA_ "GenSigSendType" SG_ 1543 BCM_R_DiagRespData5 1;
BA_ "GenSigSendType" SG_ 1543 BCM_R_DiagRespData6 1;
BA_ "GenSigSendType" SG_ 1543 BCM_R_DiagRespData7 1;
BA_ "GenSigSendType" SG_ 1543 BCM_R_DiagRespData8 1;
BA_ "GenSigSendType" SG_ 1543 BCM_R_DiagRespData9 1;
BA_ "GenSigSendType" SG_ 1543 BCM_R_DiagRespData10 1;
BA_ "GenSigSendType" SG_ 1543 BCM_R_DiagRespData11 1;
BA_ "GenSigSendType" SG_ 1543 BCM_R_DiagRespData12 1;
BA_ "GenSigSendType" SG_ 1543 BCM_R_DiagRespData13 1;
BA_ "GenSigSendType" SG_ 1543 BCM_R_DiagRespData14 1;
BA_ "GenSigSendType" SG_ 1543 BCM_R_DiagRespData15 1;
BA_ "GenSigSendType" SG_ 1543 BCM_R_DiagRespData16 1;
BA_ "GenSigSendType" SG_ 1543 BCM_R_DiagRespData17 1;
BA_ "GenSigSendType" SG_ 1543 BCM_R_DiagRespData18 1;
BA_ "GenSigSendType" SG_ 1543 BCM_R_DiagRespData19 1;
BA_ "GenSigSendType" SG_ 1543 BCM_R_DiagRespData20 1;
BA_ "GenSigSendType" SG_ 1543 BCM_R_DiagRespData21 1;
BA_ "GenSigSendType" SG_ 1543 BCM_R_DiagRespData22 1;
BA_ "GenSigSendType" SG_ 1543 BCM_R_DiagRespData23 1;
BA_ "GenSigSendType" SG_ 1543 BCM_R_DiagRespData24 1;
BA_ "GenSigSendType" SG_ 1543 BCM_R_DiagRespData25 1;
BA_ "GenSigSendType" SG_ 1543 BCM_R_DiagRespData26 1;
BA_ "GenSigSendType" SG_ 1543 BCM_R_DiagRespData27 1;
BA_ "GenSigSendType" SG_ 1543 BCM_R_DiagRespData28 1;
BA_ "GenSigSendType" SG_ 1543 BCM_R_DiagRespData29 1;
BA_ "GenSigSendType" SG_ 1543 BCM_R_DiagRespData30 1;
BA_ "GenSigSendType" SG_ 1543 BCM_R_DiagRespData31 1;
BA_ "GenSigSendType" SG_ 1543 BCM_R_DiagRespData32 1;
BA_ "GenSigSendType" SG_ 1543 BCM_R_DiagRespData33 1;
BA_ "GenSigSendType" SG_ 1543 BCM_R_DiagRespData34 1;
BA_ "GenSigSendType" SG_ 1543 BCM_R_DiagRespData35 1;
BA_ "GenSigSendType" SG_ 1543 BCM_R_DiagRespData36 1;
BA_ "GenSigSendType" SG_ 1543 BCM_R_DiagRespData37 1;
BA_ "GenSigSendType" SG_ 1543 BCM_R_DiagRespData38 1;
BA_ "GenSigSendType" SG_ 1543 BCM_R_DiagRespData39 1;
BA_ "GenSigSendType" SG_ 1543 BCM_R_DiagRespData40 1;
BA_ "GenSigSendType" SG_ 1543 BCM_R_DiagRespData41 1;
BA_ "GenSigSendType" SG_ 1543 BCM_R_DiagRespData42 1;
BA_ "GenSigSendType" SG_ 1543 BCM_R_DiagRespData43 1;
BA_ "GenSigSendType" SG_ 1543 BCM_R_DiagRespData44 1;
BA_ "GenSigSendType" SG_ 1543 BCM_R_DiagRespData45 1;
BA_ "GenSigSendType" SG_ 1543 BCM_R_DiagRespData46 1;
BA_ "GenSigSendType" SG_ 1543 BCM_R_DiagRespData47 1;
BA_ "GenSigSendType" SG_ 1543 BCM_R_DiagRespData48 1;
BA_ "GenSigSendType" SG_ 1543 BCM_R_DiagRespData49 1;
BA_ "GenSigSendType" SG_ 1543 BCM_R_DiagRespData50 1;
BA_ "GenSigSendType" SG_ 1543 BCM_R_DiagRespData51 1;
BA_ "GenSigSendType" SG_ 1543 BCM_R_DiagRespData52 1;
BA_ "GenSigSendType" SG_ 1543 BCM_R_DiagRespData53 1;
BA_ "GenSigSendType" SG_ 1543 BCM_R_DiagRespData54 1;
BA_ "GenSigSendType" SG_ 1543 BCM_R_DiagRespData55 1;
BA_ "GenSigSendType" SG_ 1543 BCM_R_DiagRespData56 1;
BA_ "GenSigSendType" SG_ 1543 BCM_R_DiagRespData57 1;
BA_ "GenSigSendType" SG_ 1543 BCM_R_DiagRespData58 1;
BA_ "GenSigSendType" SG_ 1543 BCM_R_DiagRespData59 1;
BA_ "GenSigSendType" SG_ 1543 BCM_R_DiagRespData60 1;
BA_ "GenSigSendType" SG_ 1543 BCM_R_DiagRespData61 1;
BA_ "GenSigSendType" SG_ 1543 BCM_R_DiagRespData62 1;
BA_ "GenSigSendType" SG_ 1543 BCM_R_DiagRespData63 1;
BA_ "GenSigSendType" SG_ 1671 BCM_R_DiagReqData0 1;
BA_ "GenSigSendType" SG_ 1671 BCM_R_DiagReqData1 1;
BA_ "GenSigSendType" SG_ 1671 BCM_R_DiagReqData2 1;
BA_ "GenSigSendType" SG_ 1671 BCM_R_DiagReqData3 1;
BA_ "GenSigSendType" SG_ 1671 BCM_R_DiagReqData4 1;
BA_ "GenSigSendType" SG_ 1671 BCM_R_DiagReqData5 1;
BA_ "GenSigSendType" SG_ 1671 BCM_R_DiagReqData6 1;
BA_ "GenSigSendType" SG_ 1671 BCM_R_DiagReqData7 1;
BA_ "GenSigSendType" SG_ 1671 BCM_R_DiagReqData8 1;
BA_ "GenSigSendType" SG_ 1671 BCM_R_DiagReqData9 1;
BA_ "GenSigSendType" SG_ 1671 BCM_R_DiagReqData10 1;
BA_ "GenSigSendType" SG_ 1671 BCM_R_DiagReqData11 1;
BA_ "GenSigSendType" SG_ 1671 BCM_R_DiagReqData12 1;
BA_ "GenSigSendType" SG_ 1671 BCM_R_DiagReqData13 1;
BA_ "GenSigSendType" SG_ 1671 BCM_R_DiagReqData14 1;
BA_ "GenSigSendType" SG_ 1671 BCM_R_DiagReqData15 1;
BA_ "GenSigSendType" SG_ 1671 BCM_R_DiagReqData16 1;
BA_ "GenSigSendType" SG_ 1671 BCM_R_DiagReqData17 1;
BA_ "GenSigSendType" SG_ 1671 BCM_R_DiagReqData18 1;
BA_ "GenSigSendType" SG_ 1671 BCM_R_DiagReqData19 1;
BA_ "GenSigSendType" SG_ 1671 BCM_R_DiagReqData20 1;
BA_ "GenSigSendType" SG_ 1671 BCM_R_DiagReqData21 1;
BA_ "GenSigSendType" SG_ 1671 BCM_R_DiagReqData22 1;
BA_ "GenSigSendType" SG_ 1671 BCM_R_DiagReqData23 1;
BA_ "GenSigSendType" SG_ 1671 BCM_R_DiagReqData24 1;
BA_ "GenSigSendType" SG_ 1671 BCM_R_DiagReqData25 1;
BA_ "GenSigSendType" SG_ 1671 BCM_R_DiagReqData26 1;
BA_ "GenSigSendType" SG_ 1671 BCM_R_DiagReqData27 1;
BA_ "GenSigSendType" SG_ 1671 BCM_R_DiagReqData28 1;
BA_ "GenSigSendType" SG_ 1671 BCM_R_DiagReqData29 1;
BA_ "GenSigSendType" SG_ 1671 BCM_R_DiagReqData30 1;
BA_ "GenSigSendType" SG_ 1671 BCM_R_DiagReqData31 1;
BA_ "GenSigSendType" SG_ 1671 BCM_R_DiagReqData32 1;
BA_ "GenSigSendType" SG_ 1671 BCM_R_DiagReqData33 1;
BA_ "GenSigSendType" SG_ 1671 BCM_R_DiagReqData34 1;
BA_ "GenSigSendType" SG_ 1671 BCM_R_DiagReqData35 1;
BA_ "GenSigSendType" SG_ 1671 BCM_R_DiagReqData36 1;
BA_ "GenSigSendType" SG_ 1671 BCM_R_DiagReqData37 1;
BA_ "GenSigSendType" SG_ 1671 BCM_R_DiagReqData38 1;
BA_ "GenSigSendType" SG_ 1671 BCM_R_DiagReqData39 1;
BA_ "GenSigSendType" SG_ 1671 BCM_R_DiagReqData40 1;
BA_ "GenSigSendType" SG_ 1671 BCM_R_DiagReqData41 1;
BA_ "GenSigSendType" SG_ 1671 BCM_R_DiagReqData42 1;
BA_ "GenSigSendType" SG_ 1671 BCM_R_DiagReqData43 1;
BA_ "GenSigSendType" SG_ 1671 BCM_R_DiagReqData44 1;
BA_ "GenSigSendType" SG_ 1671 BCM_R_DiagReqData45 1;
BA_ "GenSigSendType" SG_ 1671 BCM_R_DiagReqData46 1;
BA_ "GenSigSendType" SG_ 1671 BCM_R_DiagReqData47 1;
BA_ "GenSigSendType" SG_ 1671 BCM_R_DiagReqData48 1;
BA_ "GenSigSendType" SG_ 1671 BCM_R_DiagReqData49 1;
BA_ "GenSigSendType" SG_ 1671 BCM_R_DiagReqData50 1;
BA_ "GenSigSendType" SG_ 1671 BCM_R_DiagReqData51 1;
BA_ "GenSigSendType" SG_ 1671 BCM_R_DiagReqData52 1;
BA_ "GenSigSendType" SG_ 1671 BCM_R_DiagReqData53 1;
BA_ "GenSigSendType" SG_ 1671 BCM_R_DiagReqData54 1;
BA_ "GenSigSendType" SG_ 1671 BCM_R_DiagReqData55 1;
BA_ "GenSigSendType" SG_ 1671 BCM_R_DiagReqData56 1;
BA_ "GenSigSendType" SG_ 1671 BCM_R_DiagReqData57 1;
BA_ "GenSigSendType" SG_ 1671 BCM_R_DiagReqData58 1;
BA_ "GenSigSendType" SG_ 1671 BCM_R_DiagReqData59 1;
BA_ "GenSigSendType" SG_ 1671 BCM_R_DiagReqData60 1;
BA_ "GenSigSendType" SG_ 1671 BCM_R_DiagReqData61 1;
BA_ "GenSigSendType" SG_ 1671 BCM_R_DiagReqData62 1;
BA_ "GenSigSendType" SG_ 1671 BCM_R_DiagReqData63 1;
BA_ "GenSigSendType" SG_ 1612 DKCU_DiagRespData0 1;
BA_ "GenSigSendType" SG_ 1612 DKCU_DiagRespData1 1;
BA_ "GenSigSendType" SG_ 1612 DKCU_DiagRespData2 1;
BA_ "GenSigSendType" SG_ 1612 DKCU_DiagRespData3 1;
BA_ "GenSigSendType" SG_ 1612 DKCU_DiagRespData4 1;
BA_ "GenSigSendType" SG_ 1612 DKCU_DiagRespData5 1;
BA_ "GenSigSendType" SG_ 1612 DKCU_DiagRespData6 1;
BA_ "GenSigSendType" SG_ 1612 DKCU_DiagRespData7 1;
BA_ "GenSigSendType" SG_ 1612 DKCU_DiagRespData8 1;
BA_ "GenSigSendType" SG_ 1612 DKCU_DiagRespData9 1;
BA_ "GenSigSendType" SG_ 1612 DKCU_DiagRespData10 1;
BA_ "GenSigSendType" SG_ 1612 DKCU_DiagRespData11 1;
BA_ "GenSigSendType" SG_ 1612 DKCU_DiagRespData12 1;
BA_ "GenSigSendType" SG_ 1612 DKCU_DiagRespData13 1;
BA_ "GenSigSendType" SG_ 1612 DKCU_DiagRespData14 1;
BA_ "GenSigSendType" SG_ 1612 DKCU_DiagRespData15 1;
BA_ "GenSigSendType" SG_ 1612 DKCU_DiagRespData16 1;
BA_ "GenSigSendType" SG_ 1612 DKCU_DiagRespData17 1;
BA_ "GenSigSendType" SG_ 1612 DKCU_DiagRespData18 1;
BA_ "GenSigSendType" SG_ 1612 DKCU_DiagRespData19 1;
BA_ "GenSigSendType" SG_ 1612 DKCU_DiagRespData20 1;
BA_ "GenSigSendType" SG_ 1612 DKCU_DiagRespData21 1;
BA_ "GenSigSendType" SG_ 1612 DKCU_DiagRespData22 1;
BA_ "GenSigSendType" SG_ 1612 DKCU_DiagRespData23 1;
BA_ "GenSigSendType" SG_ 1612 DKCU_DiagRespData24 1;
BA_ "GenSigSendType" SG_ 1612 DKCU_DiagRespData25 1;
BA_ "GenSigSendType" SG_ 1612 DKCU_DiagRespData26 1;
BA_ "GenSigSendType" SG_ 1612 DKCU_DiagRespData27 1;
BA_ "GenSigSendType" SG_ 1612 DKCU_DiagRespData28 1;
BA_ "GenSigSendType" SG_ 1612 DKCU_DiagRespData29 1;
BA_ "GenSigSendType" SG_ 1612 DKCU_DiagRespData30 1;
BA_ "GenSigSendType" SG_ 1612 DKCU_DiagRespData31 1;
BA_ "GenSigSendType" SG_ 1612 DKCU_DiagRespData32 1;
BA_ "GenSigSendType" SG_ 1612 DKCU_DiagRespData33 1;
BA_ "GenSigSendType" SG_ 1612 DKCU_DiagRespData34 1;
BA_ "GenSigSendType" SG_ 1612 DKCU_DiagRespData35 1;
BA_ "GenSigSendType" SG_ 1612 DKCU_DiagRespData36 1;
BA_ "GenSigSendType" SG_ 1612 DKCU_DiagRespData37 1;
BA_ "GenSigSendType" SG_ 1612 DKCU_DiagRespData38 1;
BA_ "GenSigSendType" SG_ 1612 DKCU_DiagRespData39 1;
BA_ "GenSigSendType" SG_ 1612 DKCU_DiagRespData40 1;
BA_ "GenSigSendType" SG_ 1612 DKCU_DiagRespData41 1;
BA_ "GenSigSendType" SG_ 1612 DKCU_DiagRespData42 1;
BA_ "GenSigSendType" SG_ 1612 DKCU_DiagRespData43 1;
BA_ "GenSigSendType" SG_ 1612 DKCU_DiagRespData44 1;
BA_ "GenSigSendType" SG_ 1612 DKCU_DiagRespData45 1;
BA_ "GenSigSendType" SG_ 1612 DKCU_DiagRespData46 1;
BA_ "GenSigSendType" SG_ 1612 DKCU_DiagRespData47 1;
BA_ "GenSigSendType" SG_ 1612 DKCU_DiagRespData48 1;
BA_ "GenSigSendType" SG_ 1612 DKCU_DiagRespData49 1;
BA_ "GenSigSendType" SG_ 1612 DKCU_DiagRespData50 1;
BA_ "GenSigSendType" SG_ 1612 DKCU_DiagRespData51 1;
BA_ "GenSigSendType" SG_ 1612 DKCU_DiagRespData52 1;
BA_ "GenSigSendType" SG_ 1612 DKCU_DiagRespData53 1;
BA_ "GenSigSendType" SG_ 1612 DKCU_DiagRespData54 1;
BA_ "GenSigSendType" SG_ 1612 DKCU_DiagRespData55 1;
BA_ "GenSigSendType" SG_ 1612 DKCU_DiagRespData56 1;
BA_ "GenSigSendType" SG_ 1612 DKCU_DiagRespData57 1;
BA_ "GenSigSendType" SG_ 1612 DKCU_DiagRespData58 1;
BA_ "GenSigSendType" SG_ 1612 DKCU_DiagRespData59 1;
BA_ "GenSigSendType" SG_ 1612 DKCU_DiagRespData60 1;
BA_ "GenSigSendType" SG_ 1612 DKCU_DiagRespData61 1;
BA_ "GenSigSendType" SG_ 1612 DKCU_DiagRespData62 1;
BA_ "GenSigSendType" SG_ 1612 DKCU_DiagRespData63 1;
BA_ "GenSigSendType" SG_ 1740 DKCU_DiagReqData0 1;
BA_ "GenSigSendType" SG_ 1740 DKCU_DiagReqData1 1;
BA_ "GenSigSendType" SG_ 1740 DKCU_DiagReqData2 1;
BA_ "GenSigSendType" SG_ 1740 DKCU_DiagReqData3 1;
BA_ "GenSigSendType" SG_ 1740 DKCU_DiagReqData4 1;
BA_ "GenSigSendType" SG_ 1740 DKCU_DiagReqData5 1;
BA_ "GenSigSendType" SG_ 1740 DKCU_DiagReqData6 1;
BA_ "GenSigSendType" SG_ 1740 DKCU_DiagReqData7 1;
BA_ "GenSigSendType" SG_ 1740 DKCU_DiagReqData8 1;
BA_ "GenSigSendType" SG_ 1740 DKCU_DiagReqData9 1;
BA_ "GenSigSendType" SG_ 1740 DKCU_DiagReqData10 1;
BA_ "GenSigSendType" SG_ 1740 DKCU_DiagReqData11 1;
BA_ "GenSigSendType" SG_ 1740 DKCU_DiagReqData12 1;
BA_ "GenSigSendType" SG_ 1740 DKCU_DiagReqData13 1;
BA_ "GenSigSendType" SG_ 1740 DKCU_DiagReqData14 1;
BA_ "GenSigSendType" SG_ 1740 DKCU_DiagReqData15 1;
BA_ "GenSigSendType" SG_ 1740 DKCU_DiagReqData16 1;
BA_ "GenSigSendType" SG_ 1740 DKCU_DiagReqData17 1;
BA_ "GenSigSendType" SG_ 1740 DKCU_DiagReqData18 1;
BA_ "GenSigSendType" SG_ 1740 DKCU_DiagReqData19 1;
BA_ "GenSigSendType" SG_ 1740 DKCU_DiagReqData20 1;
BA_ "GenSigSendType" SG_ 1740 DKCU_DiagReqData21 1;
BA_ "GenSigSendType" SG_ 1740 DKCU_DiagReqData22 1;
BA_ "GenSigSendType" SG_ 1740 DKCU_DiagReqData23 1;
BA_ "GenSigSendType" SG_ 1740 DKCU_DiagReqData24 1;
BA_ "GenSigSendType" SG_ 1740 DKCU_DiagReqData25 1;
BA_ "GenSigSendType" SG_ 1740 DKCU_DiagReqData26 1;
BA_ "GenSigSendType" SG_ 1740 DKCU_DiagReqData27 1;
BA_ "GenSigSendType" SG_ 1740 DKCU_DiagReqData28 1;
BA_ "GenSigSendType" SG_ 1740 DKCU_DiagReqData29 1;
BA_ "GenSigSendType" SG_ 1740 DKCU_DiagReqData30 1;
BA_ "GenSigSendType" SG_ 1740 DKCU_DiagReqData31 1;
BA_ "GenSigSendType" SG_ 1740 DKCU_DiagReqData32 1;
BA_ "GenSigSendType" SG_ 1740 DKCU_DiagReqData33 1;
BA_ "GenSigSendType" SG_ 1740 DKCU_DiagReqData34 1;
BA_ "GenSigSendType" SG_ 1740 DKCU_DiagReqData35 1;
BA_ "GenSigSendType" SG_ 1740 DKCU_DiagReqData36 1;
BA_ "GenSigSendType" SG_ 1740 DKCU_DiagReqData37 1;
BA_ "GenSigSendType" SG_ 1740 DKCU_DiagReqData38 1;
BA_ "GenSigSendType" SG_ 1740 DKCU_DiagReqData39 1;
BA_ "GenSigSendType" SG_ 1740 DKCU_DiagReqData40 1;
BA_ "GenSigSendType" SG_ 1740 DKCU_DiagReqData41 1;
BA_ "GenSigSendType" SG_ 1740 DKCU_DiagReqData42 1;
BA_ "GenSigSendType" SG_ 1740 DKCU_DiagReqData43 1;
BA_ "GenSigSendType" SG_ 1740 DKCU_DiagReqData44 1;
BA_ "GenSigSendType" SG_ 1740 DKCU_DiagReqData45 1;
BA_ "GenSigSendType" SG_ 1740 DKCU_DiagReqData46 1;
BA_ "GenSigSendType" SG_ 1740 DKCU_DiagReqData47 1;
BA_ "GenSigSendType" SG_ 1740 DKCU_DiagReqData48 1;
BA_ "GenSigSendType" SG_ 1740 DKCU_DiagReqData49 1;
BA_ "GenSigSendType" SG_ 1740 DKCU_DiagReqData50 1;
BA_ "GenSigSendType" SG_ 1740 DKCU_DiagReqData51 1;
BA_ "GenSigSendType" SG_ 1740 DKCU_DiagReqData52 1;
BA_ "GenSigSendType" SG_ 1740 DKCU_DiagReqData53 1;
BA_ "GenSigSendType" SG_ 1740 DKCU_DiagReqData54 1;
BA_ "GenSigSendType" SG_ 1740 DKCU_DiagReqData55 1;
BA_ "GenSigSendType" SG_ 1740 DKCU_DiagReqData56 1;
BA_ "GenSigSendType" SG_ 1740 DKCU_DiagReqData57 1;
BA_ "GenSigSendType" SG_ 1740 DKCU_DiagReqData58 1;
BA_ "GenSigSendType" SG_ 1740 DKCU_DiagReqData59 1;
BA_ "GenSigSendType" SG_ 1740 DKCU_DiagReqData60 1;
BA_ "GenSigSendType" SG_ 1740 DKCU_DiagReqData61 1;
BA_ "GenSigSendType" SG_ 1740 DKCU_DiagReqData62 1;
BA_ "GenSigSendType" SG_ 1740 DKCU_DiagReqData63 1;
BA_ "GenSigSendType" SG_ 1791 OBD_Func_DiagReqData0 1;
BA_ "GenSigSendType" SG_ 1791 OBD_Func_DiagReqData1 1;
BA_ "GenSigSendType" SG_ 1791 OBD_Func_DiagReqData2 1;
BA_ "GenSigSendType" SG_ 1791 OBD_Func_DiagReqData3 1;
BA_ "GenSigSendType" SG_ 1791 OBD_Func_DiagReqData4 1;
BA_ "GenSigSendType" SG_ 1791 OBD_Func_DiagReqData5 1;
BA_ "GenSigSendType" SG_ 1791 OBD_Func_DiagReqData6 1;
BA_ "GenSigSendType" SG_ 1791 OBD_Func_DiagReqData7 1;
VAL_ 189 BCM_R_Windows_AntiPinch_Warn 0 "OFF" 1 "Anti-pinch FR window" ;
VAL_ 189 BCM_R_Window_Learning_Sts 0 "Invalid" 1 "FR window done" 2 "FR window failure" ;
VAL_ 189 BCM_R_Window_Suppression_Warn 0 "OFF" 1 "Suppressed" 2 "Not suppressed" ;
VAL_ 189 BCM_R_tailgate_LockActive 0 "Not Activate" 1 "Activated" ;
VAL_ 189 BCM_R_Window_ThermalProtect 0 "OFF" 1 "Level 1" 2 "Level 2" ;
VAL_ 189 BCM_R_tailgate_Error 0 "Not Error" 1 "Error" ;
VAL_ 206 BCMRE_DuctTempRearRightSts 0 "Normal" 1 "Short circuit Battery" 2 "Short circuit GND" 3 "Invalid" ;
VAL_ 206 BCMRE_DuctTempRearLeftSts 0 "Normal" 1 "Short circuit Battery" 2 "Short circuit GND" 3 "Invalid" ;
VAL_ 206 BCMRE_DuctTempSensor3_Sts 0 "Normal" 1 "Short circuit Battery" 2 "Short circuit GND" 3 "Invalid" ;
VAL_ 206 BCMRE_DuctTempSensor4_Sts 0 "Normal" 1 "Short circuit Battery" 2 "Short circuit GND" 3 "Invalid" ;
VAL_ 206 BCMRE_RearEvapTempSensor_Sts 0 "Normal" 1 "Short circuit Battery" 2 "Short circuit GND" 3 "Invalid" ;
VAL_ 253 BCMRE_Rear_Wiper_Park_Pos_Status 0 "Rear wiper not in Parking position" 1 "Rear wiper in Parking position" 2 "Reserved" 3 "Reserved" ;
VAL_ 253 BCMRE_RearWiperWorkingSts 0 "OFF" 1 "ON" 2 "Fault" ;
VAL_ 253 BCMRE_STAT_RearWiperServiceMode 0 "OFF" 1 "ON" 2 "Fault" 3 "Signal Invalid" ;
VAL_ 275 BCM_Rear_Wash_Status 0 "RearWash OFF" 1 "Rear Wash ON" ;
VAL_ 289 BCMRE_CL30s_RE_Sts 0 "OFF" 1 "ON" 2 "Fault" 3 "Invalid" ;
VAL_ 289 BCMRE_CL30c_RE_Sts 0 "OFF" 1 "ON" 2 "Fault" 3 "Invalid" ;
VAL_ 289 BCMRE_CLR_RE_Sts 0 "OFF" 1 "ON" 2 "Fault" 3 "Invalid" ;
VAL_ 289 BCMRE_CL15_RE_Sts 0 "OFF" 1 "ON" 2 "Fault" 3 "Invalid" ;
VAL_ 289 BCMRE_CL58_RE_Sts 0 "OFF" 1 "ON" 2 "Fault" 3 "Invalid" ;
VAL_ 325 BCMRE_CoolantLevel3 0 "Normal condition" 1 "Low level condition" 2 "Reserved" 3 "Invalid" ;
VAL_ 325 BCMRE_CoolantLevel3Error 0 "Normal" 1 "Fault" ;
VAL_ 325 BCMRE_SOV_Status 0 "OFF" 1 "ON" 2 "Fault" 3 "Invalid" ;
VAL_ 325 BCMRE_SOV2_Fault 0 "Normal" 1 "Open circuit" 2 "Driver chip fault" 3 "Invalid" ;
VAL_ 325 BCMRE_EvapSOV2_Status 0 "Invalid" 1 "SOV Open" 2 "SOV Close" 3 "Fault" ;
VAL_ 325 BCMRE_RearAPTC_Status 0 "Normal" 1 "Fault" ;
VAL_ 325 BCMRE_RearAPTC_FaultState 0 "Normal" 1 "Fault" ;
VAL_ 325 BCMRE_RearAPTC_LinComError 0 "Normal" 1 "Fault" ;
VAL_ 325 BCMRE_RearAPTC_OverCurrentFault 0 "Normal" 1 "Fault" ;
VAL_ 325 BCMRE_RearAPTC_LvUnderVoltFault 0 "Normal" 1 "Fault" ;
VAL_ 325 BCMRE_RearAPTC_LvOverVoltFault 0 "Normal" 1 "Fault" ;
VAL_ 325 BCMRE_RearAPTC_IGBTTempSensorFau 0 "Normal" 1 "Fault" ;
VAL_ 325 BCMRE_RearAPTC_IGBTOverTempFault 0 "Normal" 1 "Fault" ;
VAL_ 325 BCMRE_RearAPTC_TempSensorFault 0 "Normal" 1 "Fault" ;
VAL_ 325 BCMRE_RearAPTC_OverTempFault 0 "Normal" 1 "Fault" ;
VAL_ 325 BCMRE_RearAPTC_HvUnderVoltFault 0 "Normal" 1 "Fault" ;
VAL_ 325 BCMRE_RearAPTC_HvOverVoltFault 0 "Normal" 1 "Fault" ;
VAL_ 325 BCMRE_RearAPTC_ShortCircuitFault 0 "Normal" 1 "Fault" ;
VAL_ 325 BCMRE_RearAPTC_OpentCircuitFault 0 "Normal" 1 "Fault" ;
VAL_ 325 BCMRE_RearAPTC_ResponseError 0 "Normal" 1 "Fault" ;
VAL_ 325 BCMRE_RearEXV_RsErr 0 "No Comm Error" 1 "Comm Error detected" ;
VAL_ 325 BCMRE_RearEXV_CurInit_Stat 0 "Not Initialized" 1 "Initialization in Process" 2 "Initialized" 3 "Unused and Undefined" ;
VAL_ 325 BCMRE_RearEXV_Run_Stat 0 "Actuator is not moving" 1 "Actuator is moving" ;
VAL_ 325 BCMRE_RearEXV_Fault_Stat 0 "Actuator Not Faulted" 1 "Motor-Coil shorted" 2 "Motor-Coil open load" 3 "Over temperature shutdown" 4 "not defined" 5 "Motor_Stall" ;
VAL_ 325 BCMRE_RearEXV_Volt_Stat 0 "Voltage Range ok" 1 "Overvoltage" 2 "Under voltage" 3 "not defined" ;
VAL_ 325 BCMRE_RearEXV_OvrTemp_Warn 0 "Ok" 1 "High Temperature Warning" 2 "not defined" 3 "not defined" ;
VAL_ 522 ETG_Lift_Gate_Status 0 "Fully closed" 1 "Fully opened" 2 "Stopped halfway at Area 1" 3 "Stopped halfway at Area 2" 4 "Stopped halfway at Area 3" 5 "Ready to open" 6 "Opening" 7 "Ready to close" 8 "Closing" 9 "SNA (Signal not available)" ;
VAL_ 522 ETG_Power_Latch_Status 0 "uninitialized" 1 "Stoped" 2 "Cinching" 3 "Cinching reset" 4 "Releasing" 5 "Releasing reset" 7 "SNA" ;
VAL_ 522 ETG_Latch_Segment 0 "Full latch" 1 "Half latch" 2 "Open latch" 3 "SNA" ;
VAL_ 522 ETG_DSW_Status 0 "Not active" 1 "Active" ;
VAL_ 522 ETG_GSW_Status 0 "Not active" 1 "Active" ;
VAL_ 522 ETG_LTS_Status 0 "Not active" 1 "Active" ;
VAL_ 522 ETG_RTS_Status 0 "Not active" 1 "Active" ;
VAL_ 522 ETG_HAL_Status 0 "Low level" 1 "High level" ;
VAL_ 522 ETG_FUL_Status 0 "Low level" 1 "High level" ;
VAL_ 522 ETG_AJR_Status 0 "Low level(Open)" 1 "High level(Close)" ;
VAL_ 522 ETG_NTL_Status 0 "Low level" 1 "High level" ;
VAL_ 522 ETG_ERR_Voltage 0 "Normal" 1 "Under voltage" 2 "Over voltage" ;
VAL_ 522 ETG_ERR_Left_Motor 0 "Normal" 1 "Open circuit" 2 "short circuit" ;
VAL_ 522 ETG_ERR_Right_Motor 0 "Normal" 1 "Open circuit" 2 "short circuit" ;
VAL_ 522 ETG_ERR_Latch 0 "Normal" 1 "Open circuit" 2 "short circuit" ;
VAL_ 522 ETG_ERR_Hall 0 "Normal" 1 "Hall power short circuit" 2 "Hall position out of range" 3 "Hall signal out of sync" ;
VAL_ 522 ETG_Lift_Motor_Stall 0 "Not active" 1 "Active" ;
VAL_ 522 ETG_Lift_Motor_AntiPinch 0 "Not active" 1 "Active" ;
VAL_ 522 ETG_Lift_Motor_Thermal 0 "Not active" 1 "Active" ;
VAL_ 522 ETG_Power_Latch_Thermal 0 "Not active" 1 "Active" ;
VAL_ 522 ETG_Abuse_Protection 0 "Not active" 1 "Active" ;
VAL_ 523 FKS_RespError 0 "Ok" 1 "Error active" ;
VAL_ 523 FKS_OpenReq 0 "Idle" 1 "Operation Request" 2 "Invalid" 3 "Invalid" ;
VAL_ 523 FKS_HWError 0 "No Error" 1 "Error" ;
VAL_ 523 FKS_AntennaError 0 "No Error" 1 "Bottom or Top Sensor not connected" 2 "Bottom sensor short to Power or GND" 3 "Top sensor short to Power or GND" ;
VAL_ 523 FKS_OverVolDected 0 "No Error" 1 "Error" ;
VAL_ 523 FKS_UnderVolDected 0 "No Error" 1 "Error" ;
VAL_ 523 FKS_activate_deactivate 0 "Deactivated" 1 "Activated" 2 "Reserved" 3 "Signal invalid" ;
VAL_ 535 BCM_PositionLight_RL_STS 0 "OFF" 1 "ON" 2 "Reserved" 3 "Signal Invalid" 4 "Fault" ;
VAL_ 535 BCM_PositionLight_RR_STS 0 "OFF" 1 "ON" 2 "Reserved" 3 "Signal Invalid" 4 "Fault" ;
VAL_ 535 BCM_TurnIndicator_RL_STS 0 "OFF" 1 "ON" 2 "Reserved" 3 "Signal Invalid" 4 "Fault" ;
VAL_ 535 BCM_TurnIndicator_RR_STS 0 "OFF" 1 "ON" 2 "Reserved" 3 "Signal Invalid" 4 "Fault" ;
VAL_ 535 BCM_ReverseLamp_RL_STS 0 "OFF" 1 "ON" 2 "Reserved" 3 "Signal Invalid" 4 "Fault" ;
VAL_ 535 BCM_ReverseLamp_RR_STS 0 "OFF" 1 "ON" 2 "Reserved" 3 "Signal Invalid" 4 "Fault" ;
VAL_ 535 BCM_BrakeLight_RL_STS 0 "OFF" 1 "ON" 2 "Reserved" 3 "Signal Invalid" 4 "Fault" ;
VAL_ 535 BCM_BrakeLight_RR_STS 0 "OFF" 1 "ON" 2 "Reserved" 3 "Signal Invalid" 4 "Fault" ;
VAL_ 535 BCM_RearFogLamp_RR_STS 0 "OFF" 1 "ON" 2 "Reserved" 3 "Signal Invalid" 4 "Fault" ;
VAL_ 535 BCM_BrakeLight_Center_STS 0 "OFF" 1 "ON" 2 "Reserved" 3 "Signal Invalid" 4 "Fault" ;
VAL_ 535 BCM_LicensePlateLamp_RE_STS 0 "OFF" 1 "ON" 2 "Reserved" 3 "Signal Invalid" 4 "Fault" ;
VAL_ 535 BCM_RearFogLamp_RL_STS 0 "OFF" 1 "ON" 2 "Reserved" 3 "Signal Invalid" 4 "Fault" ;
VAL_ 535 BCM_SignatureRear_STS 0 "OFF" 1 "ON" 2 "Reserved" 3 "Signal Invalid" 4 "Fault" ;
VAL_ 535 BCMRE_WelcomeFarewellLight_STS 0 "OFF" 1 "Welcome mode 1" 2 "Welcome mode 2" 3 "Welcome mode 3" 4 "Farewell mode 1" 5 "Farewell mode 2" 6 "Farewell mode 3" 7 "Signal invalid" ;
VAL_ 535 BCM_PositionLight_RM_STS 0 "OFF" 1 "ON" 2 "Reserved" 3 "Signal Invalid" 4 "Fault" ;
VAL_ 535 BCM_ParkingLight_RL_STS 0 "OFF" 1 "ON" 2 "Reserved" 3 "Signal Invalid" ;
VAL_ 535 BCM_ParkingLight_RM_STS 0 "OFF" 1 "ON" 2 "Reserved" 3 "Signal Invalid" ;
VAL_ 535 BCM_ParkingLight_RR_STS 0 "OFF" 1 "ON" 2 "Reserved" 3 "Signal Invalid" ;
VAL_ 540 BCM_RE_RLDoorCourtesyLightSts 0 "OFF" 1 "ON" 2 "No Request" 3 "Signal Invalid" ;
VAL_ 540 BCM_RE_RRDoorCourtesyLightSts 0 "OFF" 1 "ON" 2 "No Request" 3 "Signal Invalid" ;
VAL_ 540 BCM_RE_CargoLightSts 0 "OFF" 1 "ON" 2 "Reserved" 3 "Signal Invalid" ;
VAL_ 540 BCM_RE_Rear_3rd_DomeLampSts 0 "OFF" 1 "ON" 2 "Fault" 3 "Signal Invalid" ;
VAL_ 540 BCM_RLProjectorLightSts 0 "OFF" 1 "ON" 2 "Reserved" 3 "Signal Invalid" ;
VAL_ 540 BCM_RRProjectorLightSts 0 "OFF" 1 "ON" 2 "Reserved" 3 "Signal Invalid" ;
VAL_ 784 CCUR_STAT_IonButton 0 "OFF" 1 "ON" 2 "Reserved" 3 "Signal invalid" ;
VAL_ 784 CCUR_STAT_Defrost 0 "OFF" 1 "ON" 2 "Reserved" 3 "Signal invalid" ;
VAL_ 784 CCUR_STAT_Auto 0 "OFF" 1 "ON" 2 "Reserved" 3 "Signal invalid" ;
VAL_ 784 CCUR_STAT_Aircondition 0 "OFF" 1 "ON" 2 "Reserved" 3 "Signal invalid" ;
VAL_ 784 CCUR_STAT_FlapPos 0 "OFF" 1 "Vent" 2 "Vent/Foot" 3 "Foot" 4 "Foot/Defrost" 5 "Defrost" 6 "Default" 7 "Signal invalid" ;
VAL_ 784 CCUR_STAT_FanSpeed 0 "OFF" 1 "Level 1" 2 "Level 2" 3 "Level 3" 4 "Level 4" 5 "Level 5" 6 "Level 6" 7 "Reserved" 8 "Reserved" 9 "Reserved" 10 "Reserved" 11 "Reserved" 12 "Reserved" 13 "Reserved" 14 "Reserved" 15 "Signal invalid" ;
VAL_ 784 CCUR_STAT_PTC_Heater 0 "OFF" 1 "Stage 1" 2 "Stage 2" 3 "Stage 3" 4 "Reserved" 5 "Reserved" 6 "Reserved" 7 "Signal invalid" ;
VAL_ 784 CCUR_STAT_OnOff 0 "OFF" 1 "ON" 2 "Reserved" 3 "Signal invalid" ;
VAL_ 784 CCUR_STAT_MaxAc 0 "OFF" 1 "ON" 2 "Reserved" 3 "Signal invalid" ;
VAL_ 784 CCUR_STAT_SyncClimateZone 0 "OFF" 1 "ON" 2 "Reserved" 3 "Signal invalid" ;
VAL_ 784 CCUR_STAT_RecircFlap 0 "Inside" 1 "Outside" 2 "Auto" 3 "Signal invalid" ;
VAL_ 1040 BCMRE_RearHeatedWindow 0 "OFF" 1 "ON" 2 "Error" 3 "Signal invalid" ;
VAL_ 1056 BCM_STAT_AutoRearWiper 0 "OFF" 1 "ON" 2 "Reserved" 3 "Signal invalid" ;
VAL_ 1056 BCM_STAT_MirrorFoldSetting 0 "Auto Fold OFF" 1 "Auto Fold ON" 2 "Reserved" 3 "Signal invalid" ;
VAL_ 1056 BCM_STAT_IMMO_KeyfobID2 0 "No trigger from MHU" 1 "Fob1" 2 "Fob2" 3 "key illegal" 4 "No key found" 5 "Searching" 6 "Reserved" 7 "Signal invalid" ;
VAL_ 1056 BCM_STAT_MirrorAutoUnfold 0 "Vehicle Unlock" 1 "Driver walk toward" 2 "OFF" 3 "Signal invalid" ;
VAL_ 1056 BCM_STAT_MirrorReverseLink 0 "OFF" 1 "Right Mirror" 2 "Left Mirror" 3 "Both Mirror" ;
VAL_ 1056 BCM_STAT_MirrorDefaultSTATting 0 "Not pressed" 1 "Pressed" 2 "Reserved" 3 "Signal invalid" ;
VAL_ 1056 BCM_STAT_WelcomeTriggerCondition 0 "Vehicle unLock" 1 "Driver walk toward" 2 "OFF" 3 "Signal invalid" ;
VAL_ 1056 BCM_STAT_FrontDomeLamp 0 "OFF" 1 "ON" 2 "AUTO" 3 "Signal invalid" ;
VAL_ 1056 BCM_STAT_FollowMeHome 0 "OFF" 1 "30 secs" 2 "60 secs" 3 "90 secs" 4 "120 secs" 5 "Signal invalid" ;
VAL_ 1056 BCM_STAT_ExteriorLight 0 "OFF" 1 "Parking" 2 "ON" 3 "AUTO" 4 "Signal invalid" ;
VAL_ 1056 BCM_STAT_RemoteLockFeedback 0 "OFF" 1 "Lights and Horn" 2 "Lights Only" 3 "Horn Only" 4 "Reserved" 5 "Reserved" 6 "Reserved" 7 "Signal invalid" ;
VAL_ 1056 BCM_STAT_RemoteDoorUnlock 0 "Reserved" 1 "Driver door" 2 "All doors" 3 "Signal invalid" ;
VAL_ 1056 BCM_STAT_AutoDoorUnlock 0 "OFF" 1 "ON" 2 "Reserved" 3 "Signal invalid" ;
VAL_ 1056 BCM_STAT_WiperServiceMode 0 "OFF" 1 "ON" 2 "Reserved" 3 "Signal Invalid" ;
VAL_ 1056 BCM_STAT_IMMO_KeyfobID 0 "No Key Found" 1 "ID1" 2 "ID2" 3 "Signal Invalid" ;
VAL_ 1056 BCM_STAT_RearHeatedWindowMirror 0 "OFF" 1 "ON" 2 "Reserved" 3 "Signal invalid" ;
VAL_ 1056 BCM_STAT_AntiTheftMode 0 "OFF" 1 "Light Only" 2 "Horn Only" 3 "Light and Horn" 4 "Signal invalid" ;
VAL_ 1056 BCM_STAT_ClimateKeepOnSts 0 "OFF" 1 "PET" 2 "CAMP" 3 "REMOTE CONTROL" ;
VAL_ 1056 BCM_STAT_FKSfeedback 0 "OFF" 1 "ON" 2 "Reserved" 3 "Signal Invalid" ;
VAL_ 1075 BCMRE_STAT_RearDefrost 0 "OFF" 1 "ON" 2 "Fault" 3 "Signal invalid" ;
VAL_ 1097 RESP_REM_LengthTyp_APM 0 "Functional status" 1 "Active function change" 2 "Reserved" 3 "Signal invalid" ;
VAL_ 1170 AmbLight_Error_Z4 0 "No Error" 1 "Error" ;
VAL_ 1170 AmbLight_LinError_Z4 0 "No Error" 1 "Error" ;
VAL_ 1170 AmbLight_Error_Z4B 0 "No Error" 1 "Error" ;
VAL_ 1170 AmbLight_LinError_Z4B 0 "No Error" 1 "Error" ;
VAL_ 1170 AmbLight_Error_Z5 0 "No Error" 1 "Error" ;
VAL_ 1170 AmbLight_LinError_Z5 0 "No Error" 1 "Error" ;
VAL_ 1170 AmbLight_Error_Z5B 0 "No Error" 1 "Error" ;
VAL_ 1170 AmbLight_LinError_Z5B 0 "No Error" 1 "Error" ;
VAL_ 1170 AmbLight_Error_Z9 0 "No Error" 1 "Error" ;
VAL_ 1170 AmbLight_LinError_Z9 0 "No Error" 1 "Error" ;
VAL_ 1170 AmbLight_Error_Z10 0 "No Error" 1 "Error" ;
VAL_ 1170 AmbLight_LinError_Z10 0 "No Error" 1 "Error" ;
VAL_ 1219 APM_Malfunction 0 "No Error" 1 "Error" ;
VAL_ 1219 ChildWindowLockStS 0 "No Error" 1 "Error" ;
VAL_ 1219 APM_Warning_Flag_3 0 "No Error" 1 "Error" ;
VAL_ 1219 APM_Warning_Flag_4 0 "No Error" 1 "Error" ;
VAL_ 1219 APM_Warning_Flag_5 0 "No Error" 1 "Error" ;
VAL_ 1219 APM_Warning_Flag_6 0 "No Error" 1 "Error" ;
VAL_ 1219 APM_Warning_Flag_7 0 "No Error" 1 "Error" ;
VAL_ 1219 APM_Warning_Flag_8 0 "No Error" 1 "Error" ;
VAL_ 1219 APM_Warning_Flag_9 0 "No Error" 1 "Error" ;
VAL_ 1219 APM_Warning_Flag_10 0 "No Error" 1 "Error" ;
VAL_ 1219 APM_Warning_Flag_11 0 "No Error" 1 "Error" ;
VAL_ 1219 APM_Warning_Flag_12 0 "No Error" 1 "Error" ;
VAL_ 1242 BCM_R_NoValidKey_1 0 "None" 1 "Alert" ;
VAL_ 1242 BCM_R_SSB_defect 0 "None" 1 "Alert" ;
VAL_ 1242 BCM_R_WrongGearPosToStart 0 "None" 1 "Alert" ;
VAL_ 1242 BCM_R_NoValidKey_2 0 "None" 1 "Alert" ;
VAL_ 1242 BCM_R_PressBrakeToStart 0 "None" 1 "Alert" ;
VAL_ 1242 BCM_R_TurnOffPosLightRemindr 0 "None" 1 "Alert" ;
VAL_ 1242 BCM_R_KeyFob_LowBattery 0 "None" 1 "Alert" ;
VAL_ 1242 BCM_R_StopLightDefect 0 "None" 1 "Alert" ;
VAL_ 1242 BCM_R_LowBeamDefect 0 "None" 1 "Alert" ;
VAL_ 1242 BCM_R_HighBeamDefect 0 "None" 1 "Alert" ;
VAL_ 1242 BCM_R_PositionLightDefect 0 "None" 1 "Alert" ;
VAL_ 1242 BCM_R_CHMLS_Defect 0 "None" 1 "Alert" ;
VAL_ 1242 BCM_R_LicencePlateLight_Defect 0 "None" 1 "Alert" ;
VAL_ 1242 BCM_R_FrontFog_Defect 0 "None" 1 "Alert" ;
VAL_ 1242 BCM_R_RearLeftDoorLockDefect 0 "None" 1 "Alert" ;
VAL_ 1242 BCM_R_ReverseLightDefect 0 "None" 1 "Alert" ;
VAL_ 1242 BCM_R_RLS_Malfunction 0 "None" 1 "Alert" ;
VAL_ 1242 BCM_R_12VBattery_LowLevel 0 "None" 1 "Alert" ;
VAL_ 1242 BCM_R_ForgetKeyFOBInCar 0 "None" 1 "Alert" ;
VAL_ 1242 BCM_R_12VBattery_Discharging 0 "None" 1 "Alert" ;
VAL_ 1242 BCM_R_TurnIndicatorDefect 0 "None" 1 "Alert" ;
VAL_ 1242 BCM_R_dTPMS_Malfunc 0 "None" 1 "Alert" ;
VAL_ 1242 BCM_R_dTPMS_Malfunc_LostSensor 0 "None" 1 "Alert" ;
VAL_ 1242 BCM_R_dTPMS_LowPressure 0 "None" 1 "Alert" ;
VAL_ 1242 BCM_R_dTPMS_RapidLeak 0 "None" 1 "Alert" ;
VAL_ 1242 BCM_R_dTPMS_HighTemperature 0 "None" 1 "Alert" ;
VAL_ 1242 BCM_R_dTPMS_HighPressure 0 "None" 1 "Alert" ;
VAL_ 1242 BCM_R_dTPMS_LowBattery 0 "None" 1 "Alert" ;
VAL_ 1242 BCM_R_Keyfob_Leftcar 0 "None" 1 "Alert" ;
VAL_ 1242 BCM_R_IDB_Brakelight_Malfunctio 0 "None" 1 "Alert" ;
VAL_ 1242 BCM_R_CVC_Brakelight_Malfunction 0 "None" 1 "Alert" ;
VAL_ 1242 BCM_R_ADAS_Turnlight_Malfunction 0 "None" 1 "Alert" ;
VAL_ 1242 BCM_R_ADAS_Highbeam_Malfunction 0 "None" 1 "Alert" ;
VAL_ 1242 BCM_R_ADAS_LowBeam_Malfunction 0 "None" 1 "Alert" ;
VAL_ 1242 BCM_R_CVC_B_Malfunction 0 "None" 1 "Alert" ;
VAL_ 1242 BCM_R_BCM_Malfunction 0 "None" 1 "Alert" ;
VAL_ 1242 BCM_R_SCM_Malfunction 0 "None" 1 "Alert" ;
VAL_ 1242 BCM_R_CrashSignalDefect 0 "None" 1 "Alert" ;
VAL_ 1242 BCM_R_RearFog_Defect 0 "None" 1 "Alert" ;
VAL_ 1242 BCM_R_FrontWiperDefect 0 "None" 1 "Alert" ;
VAL_ 1242 BCM_R_FrontLeftDoorLockDefect 0 "None" 1 "Alert" ;
VAL_ 1242 BCM_R_LDML_Malfunction 0 "None" 1 "Alert" ;
VAL_ 1242 BCM_R_RLT_Malfunction 0 "None" 1 "Alert" ;
VAL_ 1242 BCM_R_BCM_POWER_Malfunction 0 "None" 1 "Alert" ;
VAL_ 1242 BCM_R_IDB_AutoHazardBlinking_Mal 0 "None" 1 "Alert" ;
VAL_ 1242 BCM_R_LossCommGearStatus 0 "Normal" 1 "Error" ;
VAL_ 1001 DKCU_PrimaryDKValidationSts 0 "Unknown" 1 "Invalid" 2 "Authorized" 3 "Temporarily Blocked" 4 "KeyMismatch" ;
VAL_ 1001 DKCU_Guest1DKValidationSts 0 "Unknown" 1 "Invalid" 2 "Authorized" 3 "Temporarily Blocked" 4 "KeyMismatch" ;
VAL_ 1001 DKCU_Guest2DKValidationSts 0 "Unknown" 1 "Invalid" 2 "Authorized" 3 "Temporarily Blocked" 4 "KeyMismatch" ;
VAL_ 1001 DKCU_Guest3DKValidationSts 0 "Unknown" 1 "Invalid" 2 "Authorized" 3 "Temporarily Blocked" 4 "KeyMismatch" ;
VAL_ 1002 DKCU_PhoneKey_PrimaryUser_ID 0 "Device Not Available" 1 "Primary Device Connected" ;
VAL_ 1002 DKCU_PhoneKey_PrimaryUser_Locati 0 "UNKNOWN" 1 "INSIDE_CABIN" 2 "INSIDE_TRUNK" 3 "OUTSIDE_TRUNK" 4 "OUTSIDE_FAR" 5 "DOOR_ZONE_FRONT_LEFT" 6 "DOOR_ZONE_FRONT_RIGHT" 7 "DOOR_ZONE_REAR_RIGHT" 8 "DOOR_ZONE_REAR_LEFT" 9 "DROPPEDKEY_STATIONARY" 10 "Reserved" 11 "Reserved" 12 "Reserved" 13 "Reserved" 14 "Reserved" 15 " INVALID / NOT_AVAILABLE" ;
VAL_ 1002 DKCU_PhoneKey_PrimaryUser_Motion 0 "NOT IN MOTION" 1 "IN_MOTION" ;
VAL_ 1002 DKCU_CVC_PrimaryUser_DevicePolic 0 "Full" 1 "AccessOnly" 2 "AccessAndDriveRestricted" 3 "CarDelivery" 4 "Valet" 5 "VehicleService" 6 "Reserved" 7 "Reserved" 8 "Reserved" 9 "Reserved" 10 "Reserved" 11 "Reserved" 12 "Reserved" 13 "Reserved" 14 "Reserved" 15 "Reserved" ;
VAL_ 1002 DKCU_PhoneKey_Guest1_ID 0 "Device Not Available" 1 "Guest1 Device Connected" ;
VAL_ 1002 DKCU_PhoneKey_Guest1_Location 0 "UNKNOWN" 1 "INSIDE_CABIN" 2 "INSIDE_TRUNK" 3 "OUTSIDE_TRUNK" 4 "OUTSIDE_FAR" 5 "DOOR_ZONE_FRONT_LEFT" 6 "DOOR_ZONE_FRONT_RIGHT" 7 "DOOR_ZONE_REAR_RIGHT" 8 "DOOR_ZONE_REAR_LEFT" 9 "DROPPEDKEY_STATIONARY" 10 "Reserved" 11 "Reserved" 12 "Reserved" 13 "Reserved" 14 "Reserved" 15 " INVALID / NOT_AVAILABLE" ;
VAL_ 1002 DKCU_PhoneKey_Guest1_MotionFlag 0 "NOT IN MOTION" 1 "IN_MOTION" ;
VAL_ 1002 DKCU_CVC_Guest1_DevicePolicy 0 "Full" 1 "AccessOnly" 2 "AccessAndDriveRestricted" 3 "CarDelivery" 4 "Valet" 5 "VehicleService" 6 "Reserved" 7 "Reserved" 8 "Reserved" 9 "Reserved" 10 "Reserved" 11 "Reserved" 12 "Reserved" 13 "Reserved" 14 "Reserved" 15 "Reserved" ;
VAL_ 1002 DKCU_PhoneKey_Guest2_ID 0 "Device Not Available" 1 "Guest1 Device Connected" ;
VAL_ 1002 DKCU_PhoneKey_Guest2_Location 0 "UNKNOWN" 1 "INSIDE_CABIN" 2 "INSIDE_TRUNK" 3 "OUTSIDE_TRUNK" 4 "OUTSIDE_FAR" 5 "DOOR_ZONE_FRONT_LEFT" 6 "DOOR_ZONE_FRONT_RIGHT" 7 "DOOR_ZONE_REAR_RIGHT" 8 "DOOR_ZONE_REAR_LEFT" 9 "DROPPEDKEY_STATIONARY" 10 "Reserved" 11 "Reserved" 12 "Reserved" 13 "Reserved" 14 "Reserved" 15 " INVALID / NOT_AVAILABLE" ;
VAL_ 1002 DKCU_PhoneKey_Guest2_MotionFlag 0 "NOT IN MOTION" 1 "IN_MOTION" ;
VAL_ 1002 DKCU_CVC_Guest2_DevicePolicy 0 "Full" 1 "AccessOnly" 2 "AccessAndDriveRestricted" 3 "CarDelivery" 4 "Valet" 5 "VehicleService" 6 "Reserved" 7 "Reserved" 8 "Reserved" 9 "Reserved" 10 "Reserved" 11 "Reserved" 12 "Reserved" 13 "Reserved" 14 "Reserved" 15 "Reserved" ;
VAL_ 1002 DKCU_PhoneKey_Guest3_ID 0 "Device Not Available" 1 "Guest1 Device Connected" ;
VAL_ 1002 DKCU_PhoneKey_Guest3_Location 0 "UNKNOWN" 1 "INSIDE_CABIN" 2 "INSIDE_TRUNK" 3 "OUTSIDE_TRUNK" 4 "OUTSIDE_FAR" 5 "DOOR_ZONE_FRONT_LEFT" 6 "DOOR_ZONE_FRONT_RIGHT" 7 "DOOR_ZONE_REAR_RIGHT" 8 "DOOR_ZONE_REAR_LEFT" 9 "DROPPEDKEY_STATIONARY" 10 "Reserved" 11 "Reserved" 12 "Reserved" 13 "Reserved" 14 "Reserved" 15 " INVALID / NOT_AVAILABLE" ;
VAL_ 1002 DKCU_PhoneKey_Guest3_MotionFlag 0 "NOT IN MOTION" 1 "IN_MOTION" ;
VAL_ 1002 DKCU_CVC_Guest3_DevicePolicy 0 "Full" 1 "AccessOnly" 2 "AccessAndDriveRestricted" 3 "CarDelivery" 4 "Valet" 5 "VehicleService" 6 "Reserved" 7 "Reserved" 8 "Reserved" 9 "Reserved" 10 "Reserved" 11 "Reserved" 12 "Reserved" 13 "Reserved" 14 "Reserved" 15 "Reserved" ;
VAL_ 1003 DKCU_CVC_Lock_Req 0 "No Request" 1 "Request" ;
VAL_ 1003 DKCU_CVC_Unlock_Req 0 "No Request" 1 "Request" ;
VAL_ 1003 DKCU_Foot_Kick_Req 0 "No Request" 1 "Request" ;
VAL_ 1003 DKCU_CVC_ApproachingUnlock_Req 0 "No Request" 1 "Request" ;
VAL_ 1003 DKCU_CVC_WalkawayLock_Req 0 "No Request" 1 "Request" ;
VAL_ 1003 DKCU_CVC_LocateCarReq 0 "No Request" 1 "Request" ;
VAL_ 1003 DKCU_CVC_FindCarReq 0 "No Request" 1 "Request" ;
VAL_ 1003 DKCU_CVC_Welcome_Req 0 "No Request" 1 "Request" ;
VAL_ 1005 DKCU_NfcDoorAccessStatus 0 "NotValidated" 1 "Authorized" 2 "Unauthorized" 3 "Expired" 4 "Error" ;
VAL_ 1005 DKCU_NfcStartAuthStatus 0 "NotValidated" 1 "Authorized" 2 "Unauthorized" 3 "Expired" 4 "Error" ;
VAL_ 1005 DKCU_CVC_NFC_Presence 0 "none" 1 "NFC object detected" ;
VAL_ 1005 DKCU_CVC_NFC_Type 0 "None" 1 "Card" 2 "Smartphone" 3 "Reserved" ;
VAL_ 1005 DKCU_CVC_NFC_Validity 0 "Invalid" 1 "Valid/authenticated" ;
VAL_ 1005 DKCU_CVC_NFC_Fault 0 "No Fault" 1 "Comm Fault" 2 "Auth Fail" ;
VAL_ 1005 DKCU_CVC_NFC_Event 0 "No Tap" 1 "Tap Unlock" 2 "Tap Lock" 3 "Tap Start" ;
VAL_ 1006 DKCU_DigitalKeyShareUpdate 0 "NoUpdate" 1 "NewKeyReceived" 2 "KeyRevoked" 3 "KeyUpdated" 4 "InvalidKeyReceived" 5 "UpdateInProgress" ;
VAL_ 1006 DKCU_Shared_Key_Active 0 "Not Active" 1 "Active" ;
VAL_ 1007 DKCU_CVC_DoorLockControlReq 0 "No Request" 1 "Lock" 2 "Unlock" ;
VAL_ 1008 DKCU_CVC_TailgateLockControlReq 0 "No Request" 1 "Lock" 2 "Unlock" ;
VAL_ 1008 DKCU_CVC_TailgateOpenReq 0 "No Request" 1 "Open" 2 "Close" ;
VAL_ 1008 DKCU_CVC_BonnetLockControlReq 0 "No Request" 1 "Lock" 2 "Unlock" ;
VAL_ 1008 DKCU_CVC_BonnetOpenReq 0 "No Request" 1 "Lock" 2 "Unlock" ;
VAL_ 1012 DKAnchor_FrontAnchorStatus_A1 0 "No Error" 1 "Error" ;
VAL_ 1012 DKAnchor_LeftAnchorStatus_A2 0 "No Error" 1 "Error" ;
VAL_ 1012 DKAnchor_RightAnchorStatus_A3 0 "No Error" 1 "Error" ;
VAL_ 1012 DKAnchor_RearAnchorStatus_A4 0 "No Error" 1 "Error" ;
VAL_ 1012 DKAnchor_DKCUAnchorStatus_A5 0 "No Error" 1 "Error" ;
VAL_ 1012 DKAnchor_CPDAnchorStatus_A6 0 "No Error" 1 "Error" ;
VAL_ 1012 DKAnchor_ExtNFCStatus_A7 0 "No Fault" 1 "Fault" ;
VAL_ 1012 DKAnchor_IntNFCStatus_A8 0 "No Fault" 1 "Fault" ;
VAL_ 1012 DK_PhoneKeyPanicAlarmAlert 0 "None" 1 "Alert" ;
VAL_ 1012 DK_PhoneKeyBattLowAlert 0 "None" 1 "Low" ;
VAL_ 1012 DK_PhoneKeyIdleStsAlert 0 "Active Use" 1 "No Active Use" ;
VAL_ 1012 DK_VehicleIdleStsAlert 0 "Active Use" 1 "No Active Use" ;
VAL_ 1012 DK_BleOnOffStsAlert 0 "On" 1 "Off" ;
VAL_ 1012 DK_LeftCarAlert 0 "None" 1 "Alert" ;
VAL_ 1012 DK_AuthFailAlert 0 "None" 1 "Fail" ;
VAL_ 1012 DK_PhoneKeyForgotInsideAlert 0 "None" 1 "ForgotInside" ;
VAL_ 1012 DK_PhoneKeyApproachUnlockAlert 0 "Sucessful" 1 "Failed" ;
VAL_ 1012 DK_PhoneKeyCapabilityAlert 0 "UWB and BLE Both" 1 "BLE_Only" ;
VAL_ 1012 DK_PhoneKeyNfcExteriorAuthFailAl 0 "None" 1 "AuthFail" ;
VAL_ 1012 DK_PhoneKeyNfcInteriorAuthFailAl 0 "None" 1 "AuthFail" ;
VAL_ 1012 DK_PhoneKeyTrunkClosingAlert 0 "None" 1 "Alert" ;
VAL_ 1012 DK_PhoneKeyWalkawayLockFailAlert 0 "None" 1 "Alert" ;
VAL_ 1012 DK_PhoneKeyRemoteBLECmdFailAlert 0 "None" 1 "Alert" ;
VAL_ 1013 CPD_Child_presence_Status 0 "NOT_DETECTED" 1 "DETECTED" 2 "FAULT" ;
VAL_ 1014 PhoneKey_Capability_Status 0 "Unknown" 1 "BLE_ONLY" 2 "BLE_PLUS_UWB" ;
VAL_ 1014 Phone_BLEConnectionSts 0 "Lost" 1 "Bad" 2 "Good" 3 "Very Good" ;
VAL_ 1014 Phone_UWBConnectionSts 0 "Lost" 1 "Bad" 2 "Good" 3 "Very Good" ;
VAL_ 1014 Phone_NFCConnectionSts 0 "Lost" 1 "Bad" 2 "Good" 3 "Very Good" ;
VAL_ 1016 DKCU_Temp_Inv_Req 0 "UNKNOWN" 1 "Temperature Intervention" ;
VAL_ 1016 DKCU_Remote_Phone_Inv_Req 0 "UNKNOWN" 1 "Phone Intervention" ;
VAL_ 1018 DKCU_CVC_Footkick_Sts 0 "No gesture detected" 1 "Valid foot kick gesture detected and accepted" 2 "Gesture detected but rejected due to failed conditions (e.g., key not authorized, vehicle not locked)" 3 "Gesture detected but not proper required gesture" 4 "Reserved" 5 "Reserved" 6 "Reserved" 7 "Error/Fault in gesture sensor or anchor" ;
